VERSION ""

NS_ :

BS_:

BU_: ACM APIM APIM_CDC APIM_CIM APIM_CISM ARM DSP ESPM FCIMB GENERIC GWM HUD_ADV IPC MRCMB_RDAPM_HS3 RACM_RCIM TRM_ITRM TSTR WCM WCMB WCMC

BO_ 531 DesiredTorqBrk_HS3: 8 GWM
 SG_ PrplWhlTot_Tq_RqMx : 7|16@0+ (4,-131072) [-131072|131068] "Nm"  GENERIC
 SG_ LscmbBrkPrchg_B_Actl : 16|1@0+ (1,0) [0|1] "SED"  GENERIC
 SG_ LscmbbMntr_B_Err : 17|1@0+ (1,0) [0|1] "SED"  APIM,APIM_CDC,APIM_CIM,APIM_CISM,IPC
 SG_ LscmbbDeny_B_ActlBrk : 18|1@0+ (1,0) [0|1] "SED"  GENERIC
 SG_ LscmbbBrkDis_B_Actl : 19|1@0+ (1,0) [0|1] "SED"  GENERIC
 SG_ LscmbbBrkDecel_B_Actl : 20|1@0+ (1,0) [0|1] "SED"  GENERIC
 SG_ LscmbbBaSensInc_B_Actl : 21|1@0+ (1,0) [0|1] "SED"  GENERIC
 SG_ AccStopActv_B_ActlBrk : 22|1@0+ (1,0) [0|1] "SED"  GENERIC
 SG_ StabCtlBrkActv_B_Actl : 23|1@0+ (1,0) [0|1] "SED"  APIM,APIM_CDC,APIM_CIM,APIM_CISM
 SG_ PrkBrkStatus : 26|3@0+ (1,0) [0|7] "SED"  APIM,APIM_CDC,APIM_CIM,APIM_CISM,IPC
 SG_ VehStop_D_Stat : 28|2@0+ (1,0) [0|3] "SED"  GENERIC
 SG_ PrkBrkRedLamp_D_Rq : 30|2@0+ (1,0) [0|3] "SED"  APIM_CDC,APIM_CIM,APIM_CISM,IPC
 SG_ TracCtlPtActv_B_Actl : 31|1@0+ (1,0) [0|1] "SED"  GENERIC
 SG_ AccDis_B_ActlEpb : 32|1@0+ (1,0) [0|1] "SED"  GENERIC
 SG_ PrkBrkMsgTxt_D_Rq : 36|4@0+ (1,0) [0|15] "SED"  APIM,APIM_CDC,APIM_CIM,APIM_CISM,IPC
 SG_ PrkBrkYwLamp_D_Rq : 38|2@0+ (1,0) [0|3] "SED"  APIM_CDC,APIM_CIM,APIM_CISM,IPC
 SG_ VehicleStationary : 39|1@0+ (1,0) [0|1] "SED"  GENERIC
 SG_ VehLongOvrGnd_A_Est : 41|10@0+ (0.035,-17.9) [-17.9|17.905] "m/s^2"  TRM_ITRM
 SG_ AccBrkDeny_B_Actl : 42|1@0+ (1,0) [0|1] "SED"  GENERIC
 SG_ AccBrkActv_B_Actl : 43|1@0+ (1,0) [0|1] "SED"  GENERIC
 SG_ AccBrkDis_B_Actl : 44|1@0+ (1,0) [0|1] "SED"  GENERIC
 SG_ AbsActv_B_Actl : 45|1@0+ (1,0) [0|1] "SED"  APIM,APIM_CDC,APIM_CIM,APIM_CISM,TRM_ITRM
 SG_ PrplDrgCtlActv_B_Actl : 46|1@0+ (1,0) [0|1] "SED"  GENERIC
 SG_ CcDis_B_Cmd : 47|1@0+ (1,0) [0|1] "SED"  GENERIC
 SG_ CmbbBrkDis_B_Actl : 56|1@0+ (1,0) [0|1] "SED"  GENERIC
 SG_ CmbbBaSensInc_B_Actl : 57|1@0+ (1,0) [0|1] "SED"  GENERIC
 SG_ CmbbBrkDecel_B_Actl : 58|1@0+ (1,0) [0|1] "SED"  TRM_ITRM
 SG_ CmbbBrkPrchg_B_Actl : 59|1@0+ (1,0) [0|1] "SED"  TRM_ITRM
 SG_ CmbbDeny_B_ActlBrk : 60|1@0+ (1,0) [0|1] "SED"  GENERIC
 SG_ AccBrkPrchgActv_B_Actl : 61|1@0+ (1,0) [0|1] "SED"  GENERIC
 SG_ AccBrkTotTqMn_B_Actl : 62|1@0+ (1,0) [0|1] "SED"  TRM_ITRM
 SG_ AccBrkWarm_B_Actl : 63|1@0+ (1,0) [0|1] "SED"  GENERIC

BO_ 533 APIM_Send_Signals_2: 8 APIM_CDC
 SG_ TCU_Init_Actvtn_St : 1|2@0+ (1,0) [0|3] "SED"  GWM
 SG_ TCU_Final_Actvtn_St : 3|2@0+ (1,0) [0|3] "SED"  GWM
 SG_ TrlrAidMde_D_Rq : 5|2@0+ (1,0) [0|3] "SED"  GWM
 SG_ PaakMyKey_D_Rq : 7|2@0+ (1,0) [0|3] "SED"  GWM
 SG_ DcacMdeButtn_B_Stat : 8|1@0+ (1,0) [0|1] "SED"  GWM
 SG_ DcacGfciTestBttn_B_Stat : 9|1@0+ (1,0) [0|1] "SED"  GWM
 SG_ DcacPwButtn_B_Stat : 10|1@0+ (1,0) [0|1] "SED"  GWM
 SG_ DcacPwResetButtn_B_Stat : 11|1@0+ (1,0) [0|1] "SED"  GWM
 SG_ DcacPwOffButtn_B_Stat : 12|1@0+ (1,0) [0|1] "SED"  GWM
 SG_ DcacPwLoButtn_B_Stat : 13|1@0+ (1,0) [0|1] "SED"  GWM
 SG_ DcacPwHiButtn_B_Stat : 14|1@0+ (1,0) [0|1] "SED"  GWM
 SG_ DcacPwButtn_B_Falt : 15|1@0+ (1,0) [0|1] "SED"  GWM
 SG_ OnbChrgGoTUpdate_B_Rq : 16|1@0+ (1,0) [0|1] "SED"  GWM
 SG_ OnbChrgGoTDelete_B_Rq : 17|1@0+ (1,0) [0|1] "SED"  GWM
 SG_ OnbChrgClearAll_B_Rq : 18|1@0+ (1,0) [0|1] "SED"  GWM
 SG_ AutoEpbButtn_B_Stat : 19|1@0+ (1,0) [0|1] "SED"  GWM
 SG_ TrlrHitch_D_RqMnu : 23|4@0+ (1,0) [0|15] "SED"  GWM
 SG_ OnbChrgGoTOn_D_Rq : 25|2@0+ (1,0) [0|3] "SED"  GWM
 SG_ OnbChrgGoTExtHtr_D_Rq : 27|2@0+ (1,0) [0|3] "SED"  GWM
 SG_ OnbChrgGoTElement_D_Rq : 31|4@0+ (1,0) [0|15] "unitless"  GWM
 SG_ AutoEpbZoomView_B_Stat : 32|1@0+ (1,0) [0|1] "SED"  GWM
 SG_ OnbChrgGoTPrcond_D_Rq : 34|2@0+ (1,0) [0|3] "SED"  GWM
 SG_ OnbChrgGoTHr_T_Rq : 39|5@0+ (1,0) [0|31] "hour"  GWM
 SG_ OtaTrg_D_Stat : 41|2@0+ (1,0) [0|3] "SED"  GWM
 SG_ OnbChrgGoTTouch_D_Rq : 43|2@0+ (1,0) [0|3] "SED"  GWM
 SG_ OnbChrgGoTMnte_D_Rq : 47|4@0+ (1,0) [0|15] "minute"  GWM
 SG_ LghtAmbDrvMde_D_Rq : 49|2@0+ (1,0) [0|3] "SED"  GWM
 SG_ TrlrAlarmButtn_B_Stat : 50|1@0+ (1,0) [0|1] "SED"  GWM,TRM_ITRM
 SG_ TrlrBrkGain_No_Rq : 55|5@0+ (0.5,0) [0|15.5] "unitless"  GWM,TRM_ITRM
 SG_ TjaLcEnbl_D_RqMnu : 57|2@0+ (1,0) [0|3] "SED"  GWM
 SG_ ExtLghtRvrseOn_B_Rq : 58|1@0+ (1,0) [0|1] "SED"  GWM
 SG_ ClrExitAsstEnbl_D_RqMnu : 60|2@0+ (1,0) [0|3] "SED"  GWM
 SG_ DcacPw_D_Rq : 62|2@0+ (1,0) [0|3] "SED"  GWM
 SG_ DcacPwReset_B_Rq : 63|1@0+ (1,0) [0|1] "SED"  GWM

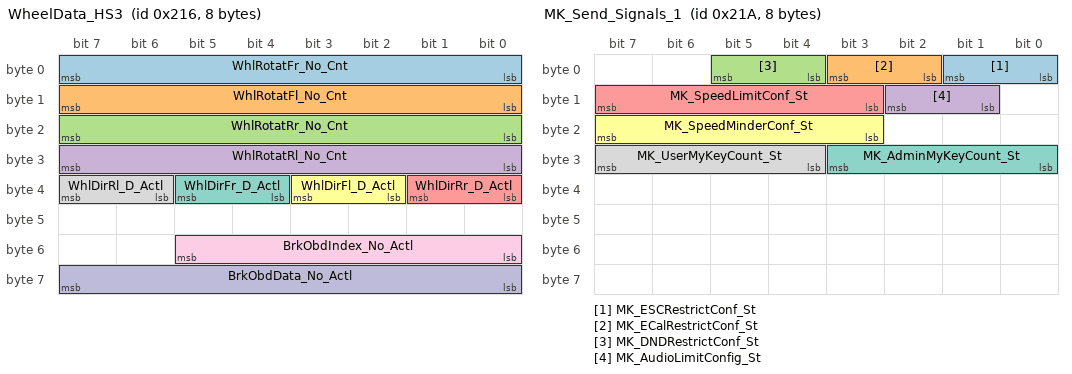
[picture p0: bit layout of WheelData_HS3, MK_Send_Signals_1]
BO_ 534 WheelData_HS3: 8 GWM
 SG_ WhlRotatFr_No_Cnt : 7|8@0+ (1,0) [0|255] "unitless"  APIM,APIM_CDC,APIM_CIM,APIM_CISM
 SG_ WhlRotatFl_No_Cnt : 15|8@0+ (1,0) [0|255] "unitless"  APIM,APIM_CDC,APIM_CIM,APIM_CISM
 SG_ WhlRotatRr_No_Cnt : 23|8@0+ (1,0) [0|255] "unitless"  APIM,APIM_CDC,APIM_CIM,APIM_CISM
 SG_ WhlRotatRl_No_Cnt : 31|8@0+ (1,0) [0|255] "unitless"  APIM,APIM_CDC,APIM_CIM,APIM_CISM
 SG_ WhlDirRr_D_Actl : 33|2@0+ (1,0) [0|3] "SED"  APIM,APIM_CDC,APIM_CIM,APIM_CISM
 SG_ WhlDirFl_D_Actl : 35|2@0+ (1,0) [0|3] "SED"  APIM,APIM_CDC,APIM_CIM,APIM_CISM
 SG_ WhlDirFr_D_Actl : 37|2@0+ (1,0) [0|3] "SED"  APIM,APIM_CDC,APIM_CIM,APIM_CISM
 SG_ WhlDirRl_D_Actl : 39|2@0+ (1,0) [0|3] "SED"  APIM,APIM_CDC,APIM_CIM,APIM_CISM
 SG_ BrkObdIndex_No_Actl : 53|6@0+ (1,0) [0|63] "unitless"  GENERIC
 SG_ BrkObdData_No_Actl : 63|8@0+ (1,0) [0|255] "unitless"  GENERIC

BO_ 535 WheelSpeed_HS3: 8 GWM
 SG_ WhlFl_W_Meas : 6|15@0+ (0.01,0) [0|327.67] "rad/s"  ARM
 SG_ WhlFr_W_Meas : 22|15@0+ (0.01,0) [0|327.67] "rad/s"  ARM
 SG_ WhlRl_W_Meas : 38|15@0+ (0.01,0) [0|327.67] "rad/s"  ARM
 SG_ WhlRr_W_Meas : 54|15@0+ (0.01,0) [0|327.67] "rad/s"  ARM

BO_ 538 MK_Send_Signals_1: 8 IPC
 SG_ MK_ESCRestrictConf_St : 1|2@0+ (1,0) [0|3] "SED"  APIM,APIM_CISM,GWM
 SG_ MK_ECalRestrictConf_St : 3|2@0+ (1,0) [0|3] "SED"  APIM,APIM_CISM,GWM
 SG_ MK_DNDRestrictConf_St : 5|2@0+ (1,0) [0|3] "SED"  APIM,APIM_CISM,GWM
 SG_ MK_AudioLimitConfig_St : 10|2@0+ (1,0) [0|3] "SED"  APIM,APIM_CISM,GWM
 SG_ MK_SpeedLimitConf_St : 15|5@0+ (1,0) [0|31] "SED"  APIM,APIM_CISM,GWM
 SG_ MK_SpeedMinderConf_St : 23|5@0+ (1,0) [0|31] "SED"  APIM,APIM_CISM,GWM
 SG_ MK_AdminMyKeyCount_St : 27|4@0+ (1,0) [0|13] "SED"  APIM,APIM_CISM,GWM
 SG_ MK_UserMyKeyCount_St : 31|4@0+ (1,0) [0|13] "SED"  APIM,APIM_CISM,GWM

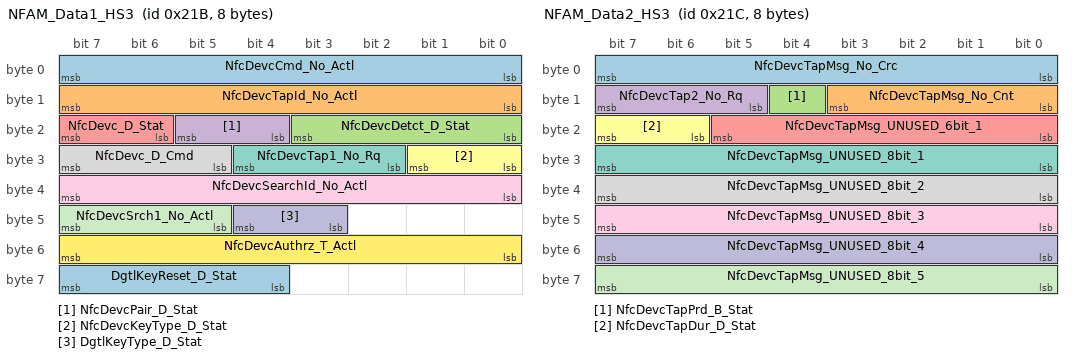
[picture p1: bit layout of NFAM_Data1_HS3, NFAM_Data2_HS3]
BO_ 539 NFAM_Data1_HS3: 8 GWM
 SG_ NfcDevcCmd_No_Actl : 7|8@0+ (1,0) [0|255] "unitless" Vector__XXX
 SG_ NfcDevcTapId_No_Actl : 15|8@0+ (1,0) [0|255] "unitless"  APIM,APIM_CDC,APIM_CIM,IPC
 SG_ NfcDevcDetct_D_Stat : 19|4@0+ (1,0) [0|15] "SED"  APIM,APIM_CDC,APIM_CIM,IPC
 SG_ NfcDevcPair_D_Stat : 21|2@0+ (1,0) [0|3] "SED" Vector__XXX
 SG_ NfcDevc_D_Stat : 23|2@0+ (1,0) [0|3] "SED" Vector__XXX
 SG_ NfcDevcKeyType_D_Stat : 25|2@0+ (1,0) [0|3] "SED" Vector__XXX
 SG_ NfcDevcTap1_No_Rq : 28|3@0+ (1,0) [0|7] "unitless"  APIM,APIM_CDC,APIM_CIM,IPC
 SG_ NfcDevc_D_Cmd : 31|3@0+ (1,0) [0|7] "SED" Vector__XXX
 SG_ NfcDevcSearchId_No_Actl : 39|8@0+ (1,0) [0|255] "unitless" Vector__XXX
 SG_ DgtlKeyType_D_Stat : 44|2@0+ (1,0) [0|3] "SED" Vector__XXX
 SG_ NfcDevcSrch1_No_Actl : 47|3@0+ (1,0) [0|7] "unitless" Vector__XXX
 SG_ NfcDevcAuthrz_T_Actl : 55|8@0+ (1,0) [0|255] "second" Vector__XXX
 SG_ DgtlKeyReset_D_Stat : 63|4@0+ (1,0) [0|15] "SED" Vector__XXX

BO_ 540 NFAM_Data2_HS3: 8 GWM
 SG_ NfcDevcTapMsg_No_Crc : 7|8@0+ (1,0) [0|255] "unitless"  APIM,APIM_CDC,APIM_CIM,IPC
 SG_ NfcDevcTapMsg_No_Cnt : 11|4@0+ (1,0) [0|15] "unitless"  APIM,APIM_CDC,APIM_CIM,IPC
 SG_ NfcDevcTapPrd_B_Stat : 12|1@0+ (1,0) [0|1] "SED"  APIM,APIM_CDC,APIM_CIM,IPC
 SG_ NfcDevcTap2_No_Rq : 15|3@0+ (1,0) [0|7] "unitless"  APIM,APIM_CDC,APIM_CIM,IPC
 SG_ NfcDevcTapMsg_UNUSED_6bit_1 : 21|6@0+ (1,0) [63|63] "Unitless"  APIM_CDC,APIM_CIM
 SG_ NfcDevcTapDur_D_Stat : 23|2@0+ (1,0) [0|3] "SED"  APIM,APIM_CDC,APIM_CIM,IPC
 SG_ NfcDevcTapMsg_UNUSED_8bit_1 : 31|8@0+ (1,0) [255|255] "Unitless"  APIM_CDC,APIM_CIM
 SG_ NfcDevcTapMsg_UNUSED_8bit_2 : 39|8@0+ (1,0) [255|255] "Unitless"  APIM_CDC,APIM_CIM
 SG_ NfcDevcTapMsg_UNUSED_8bit_3 : 47|8@0+ (1,0) [255|255] "Unitless"  APIM_CDC,APIM_CIM
 SG_ NfcDevcTapMsg_UNUSED_8bit_4 : 55|8@0+ (1,0) [255|255] "Unitless"  APIM_CDC,APIM_CIM
 SG_ NfcDevcTapMsg_UNUSED_8bit_5 : 63|8@0+ (1,0) [255|255] "Unitless"  APIM_CDC,APIM_CIM

BO_ 542 LocationServices_3_HS3: 8 GWM
 SG_ LocationServices_3 : 7|64@0+ (1,0) [0|1.84467440737096E+019] "unitless"  ACM,APIM,APIM_CDC,APIM_CIM,APIM_CISM,IPC

BO_ 543 TelTaleData: 8 APIM_CDC
 SG_ TeltalWarnData_No_Actl : 7|64@0+ (1,0) [0|1.84467440737096E+019] "unitless"  APIM,APIM_CISM,GWM

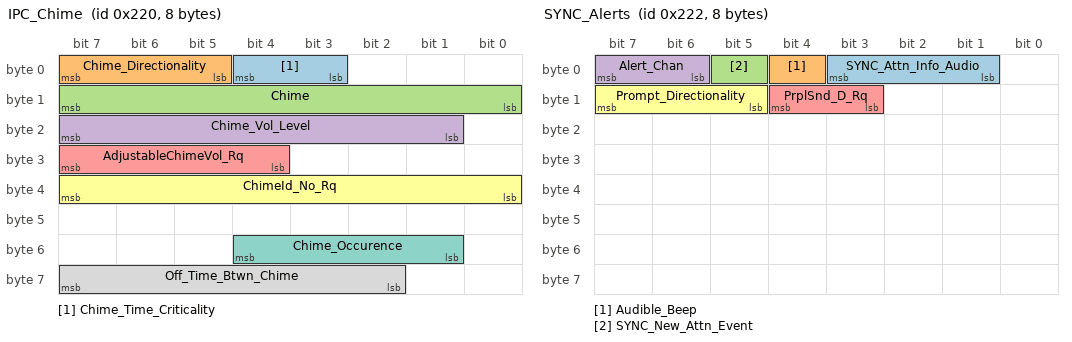
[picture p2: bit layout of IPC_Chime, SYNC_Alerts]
BO_ 544 IPC_Chime: 8 APIM_CDC
 SG_ Chime_Time_Criticality : 4|2@0+ (1,0) [0|3] "SED"  ACM,APIM_CISM,DSP,GWM
 SG_ Chime_Directionality : 7|3@0+ (1,0) [0|7] "SED"  ACM,APIM_CISM,DSP,GWM
 SG_ Chime : 15|8@0+ (1,0) [0|255] "unitless"  ACM,APIM_CISM,DSP,GWM
 SG_ Chime_Vol_Level : 23|7@0+ (1,0) [0|127] "unitless"  ACM,APIM_CISM,DSP,GWM
 SG_ AdjustableChimeVol_Rq : 31|4@0+ (1,0) [0|15] "SED"  ACM,APIM_CISM,DSP,GWM
 SG_ ChimeId_No_Rq : 39|8@0+ (1,0) [0|255] "SED"  ACM,APIM_CISM,GWM
 SG_ Chime_Occurence : 52|4@0+ (1,0) [0|15] "SED"  ACM,APIM_CISM,DSP,GWM
 SG_ Off_Time_Btwn_Chime : 63|6@0+ (1,0) [0|52] "unitless"  ACM,APIM_CISM,DSP,GWM

BO_ 545 DSPAMP_Send_Signals_1: 8 DSP
 SG_ DSP_MyKeyVolLim_St : 2|2@0+ (1,0) [0|3] "SED"  APIM,APIM_CDC,APIM_CIM,APIM_CISM
 SG_ DSP_BeltminderAudio_St : 4|2@0+ (1,0) [0|3] "SED"  APIM,APIM_CDC,APIM_CIM,APIM_CISM
 SG_ DSP_Sur_Sound_st : 7|2@0+ (1,0) [0|3] "SED"  APIM,APIM_CDC,APIM_CIM,APIM_CISM
 SG_ DSP_Audio_Volume_Up_St : 9|1@0+ (1,0) [0|1] "SED"  ACM,APIM,APIM_CDC,APIM_CIM,APIM_CISM,GWM,HUD_ADV,IPC,RACM_RCIM
 SG_ DSP_Audio_Vol_Level_St : 15|5@0+ (1,0) [0|30] "unitless"  ACM,APIM,APIM_CDC,APIM_CIM,APIM_CISM,HUD_ADV,IPC,RACM_RCIM,WCM
 SG_ DSP_MyKeyVolLimitUp_St : 19|2@0+ (1,0) [0|3] "SED"  APIM,APIM_CDC,APIM_CIM,APIM_CISM
 SG_ DSP_Bezel_Diag_St : 23|4@0+ (1,0) [0|15] "SED"  APIM,APIM_CDC,APIM_CIM,APIM_CISM
 SG_ AutoConfigOcc_Rear : 28|1@0+ (1,0) [0|1] "SED"  APIM,APIM_CDC,APIM_CIM,APIM_CISM
 SG_ AutoConfigOcc_AllSeats : 29|1@0+ (1,0) [0|1] "SED"  APIM,APIM_CDC,APIM_CIM,APIM_CISM
 SG_ AutoConfigOcc_Front : 30|1@0+ (1,0) [0|1] "SED"  APIM,APIM_CDC,APIM_CIM,APIM_CISM
 SG_ AutoConfigOcc_Driver : 31|1@0+ (1,0) [0|1] "SED"  APIM,APIM_CDC,APIM_CIM,APIM_CISM
 SG_ SurndSndUpmix2_D_Stat : 34|3@0+ (1,0) [0|7] "SED"  APIM,APIM_CDC,APIM_CIM,APIM_CISM
 SG_ AudioOccMde_D_Stat : 39|5@0+ (1,0) [0|31] "SED"  APIM,APIM_CDC,APIM_CIM,APIM_CISM
 SG_ SpkrDgtlCntr_D_Stat : 43|2@0+ (1,0) [0|3] "SED"  ACM,APIM_CDC,APIM_CIM,APIM_CISM
 SG_ SpkrDgtlLeft_D_Stat : 45|2@0+ (1,0) [0|3] "SED"  GENERIC
 SG_ SpkrDgtlRight_D_Stat : 47|2@0+ (1,0) [0|3] "SED"  GENERIC
 SG_ SndImmrsnLvl_D_Stat : 55|8@0+ (1,0) [0|255] "SED"  APIM,APIM_CDC,APIM_CIM,APIM_CISM

BO_ 546 SYNC_Alerts: 8 APIM_CDC
 SG_ SYNC_Attn_Info_Audio : 3|3@0+ (1,0) [0|7] "SED"  ACM,DSP
 SG_ Audible_Beep : 4|1@0+ (1,0) [0|1] "SED"  ACM,DSP
 SG_ SYNC_New_Attn_Event : 5|1@0+ (1,0) [0|1] "SED"  ACM,DSP
 SG_ Alert_Chan : 7|2@0+ (1,0) [0|3] "SED"  ACM,DSP,RACM_RCIM,WCM
 SG_ PrplSnd_D_Rq : 12|2@0+ (1,0) [0|3] "SED"  ACM
 SG_ Prompt_Directionality : 15|3@0+ (1,0) [0|7] "SED"  ACM,DSP

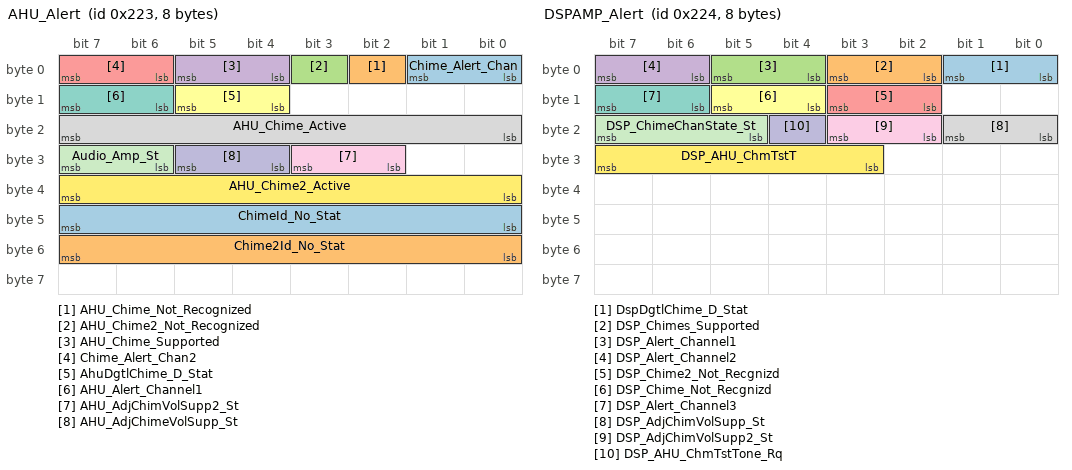
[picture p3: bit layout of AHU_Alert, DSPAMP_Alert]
BO_ 547 AHU_Alert: 8 APIM_CIM
 SG_ Chime_Alert_Chan : 1|2@0+ (1,0) [0|3] "SED"  DSP,GWM,IPC
 SG_ AHU_Chime_Not_Recognized : 2|1@0+ (1,0) [0|1] "SED"  APIM_CDC,GWM,IPC
 SG_ AHU_Chime2_Not_Recognized : 3|1@0+ (1,0) [0|1] "SED"  APIM_CDC,GWM,IPC
 SG_ AHU_Chime_Supported : 5|2@0+ (1,0) [0|3] "SED"  APIM,APIM_CDC,GWM,IPC
 SG_ Chime_Alert_Chan2 : 7|2@0+ (1,0) [0|3] "SED"  DSP,GWM,IPC
 SG_ AhuDgtlChime_D_Stat : 13|2@0+ (1,0) [0|3] "SED"  DSP
 SG_ AHU_Alert_Channel1 : 15|2@0+ (1,0) [0|3] "SED"  APIM,APIM_CDC,GWM,IPC,RACM_RCIM,WCM
 SG_ AHU_Chime_Active : 23|8@0+ (1,0) [0|255] "SED"  APIM_CDC,DSP,GWM,IPC
 SG_ AHU_AdjChimVolSupp2_St : 27|2@0+ (1,0) [0|3] "SED"  APIM_CDC,IPC
 SG_ AHU_AdjChimeVolSupp_St : 29|2@0+ (1,0) [0|3] "SED"  APIM_CDC,IPC
 SG_ Audio_Amp_St : 31|2@0+ (1,0) [0|3] "SED"  GWM
 SG_ AHU_Chime2_Active : 39|8@0+ (1,0) [0|255] "SED"  APIM_CDC,DSP,GWM,IPC
 SG_ ChimeId_No_Stat : 47|8@0+ (1,0) [0|255] "SED"  APIM_CDC,IPC
 SG_ Chime2Id_No_Stat : 55|8@0+ (1,0) [0|255] "SED"  APIM_CDC,IPC

BO_ 548 DSPAMP_Alert: 8 DSP
 SG_ DspDgtlChime_D_Stat : 1|2@0+ (1,0) [0|3] "SED"  ACM,APIM_CIM,APIM_CISM
 SG_ DSP_Chimes_Supported : 3|2@0+ (1,0) [0|3] "SED"  ACM,APIM,APIM_CDC,APIM_CIM,APIM_CISM,IPC
 SG_ DSP_Alert_Channel1 : 5|2@0+ (1,0) [0|3] "SED"  ACM,APIM_CDC,APIM_CIM,APIM_CISM,IPC
 SG_ DSP_Alert_Channel2 : 7|2@0+ (1,0) [0|3] "SED"  ACM,APIM_CDC,APIM_CIM,APIM_CISM,IPC
 SG_ DSP_Chime2_Not_Recgnizd : 11|2@0+ (1,0) [0|3] "SED"  APIM_CDC,APIM_CIM,APIM_CISM,IPC
 SG_ DSP_Chime_Not_Recgnizd : 13|2@0+ (1,0) [0|3] "SED"  APIM_CDC,APIM_CIM,APIM_CISM,IPC
 SG_ DSP_Alert_Channel3 : 15|2@0+ (1,0) [0|3] "SED"  APIM,APIM_CDC,APIM_CIM,APIM_CISM,IPC,RACM_RCIM,WCM
 SG_ DSP_AdjChimVolSupp_St : 17|2@0+ (1,0) [0|3] "SED"  ACM,APIM_CDC,APIM_CIM,APIM_CISM,IPC
 SG_ DSP_AdjChimVolSupp2_St : 19|2@0+ (1,0) [0|3] "SED"  ACM,APIM_CDC,APIM_CIM,APIM_CISM,IPC
 SG_ DSP_AHU_ChmTstTone_Rq : 20|1@0+ (1,0) [0|1] "SED"  ACM,APIM_CIM,APIM_CISM
 SG_ DSP_ChimeChanState_St : 23|3@0+ (1,0) [0|7] "SED"  ACM,APIM_CIM,APIM_CISM
 SG_ DSP_AHU_ChmTstT : 31|5@0+ (1,0) [0|31] "SED"  ACM,APIM_CIM,APIM_CISM

BO_ 549 IPC_Infotainment: 8 APIM_CDC
 SG_ IPC_New_Attn_Event : 0|1@0+ (1,0) [0|1] "SED"  ACM,APIM,APIM_CISM,DSP,GWM
 SG_ HudBrightMnuOn_B_Rq : 1|1@0+ (1,0) [0|1] "SED"  GWM,HUD_ADV
 SG_ IPC_Attn_Info_Audio : 4|3@0+ (1,0) [0|7] "SED"  ACM,APIM,APIM_CISM,DSP,GWM
 SG_ BeltminderAudioMute : 6|2@0+ (1,0) [0|3] "SED"  ACM,APIM,APIM_CISM,DSP,GWM
 SG_ MetricActv_B_Dsply : 7|1@0+ (1,0) [0|1] "SED"  ARM,GWM,HUD_ADV
 SG_ IPC_MyKeyVolLimit_St : 9|2@0+ (1,0) [0|3] "SED"  ACM,APIM,APIM_CISM,DSP,GWM
 SG_ HudVertMnuOn_B_Rq : 11|1@0+ (1,0) [0|1] "SED"  GWM,HUD_ADV
 SG_ SpeedChngChime_D_Rq2 : 13|2@0+ (1,0) [0|3] "SED"  GWM
 SG_ Chime_Source : 15|2@0+ (1,0) [0|3] "SED"  ACM,APIM_CISM,DSP,GWM
 SG_ StrtInGearOk_D_Stat : 17|2@0+ (1,0) [0|3] "SED"  GWM
 SG_ FactoryReset_Rq2 : 18|1@0+ (1,0) [0|1] "SED"  GWM
 SG_ HdcOn_B_Rq : 19|1@0+ (1,0) [0|1] "SED"  GWM
 SG_ HudCntntMnuOn_B_Rq : 20|1@0+ (1,0) [0|1] "SED"  GWM,HUD_ADV
 SG_ HudVertSzMnuOn_B_Rq : 21|1@0+ (1,0) [0|1] "SED"  GWM,HUD_ADV
 SG_ HudRotatMnuOn_B_Rq : 22|1@0+ (1,0) [0|1] "SED"  GWM,HUD_ADV
 SG_ Power_Up_Chime_Modules : 23|1@0+ (1,0) [0|1] "SED"  ACM,APIM_CISM,DSP,GWM
 SG_ WndwCabnMde_D_Rq2 : 25|2@0+ (1,0) [0|3] "SED"  GWM
 SG_ HazrdLghtMde_D_Rq2 : 27|2@0+ (1,0) [0|3] "SED"  GWM
 SG_ DelvrAsstLckMde_D_Rq2 : 29|2@0+ (1,0) [0|3] "SED"  GWM
 SG_ DelvrAsstButtn_D_Rq2 : 31|2@0+ (1,0) [0|3] "SED"  GWM
 SG_ Veh_V2_Dsply : 39|9@0+ (1,0) [0|511] "unitless"  APIM,APIM_CISM,ARM,GWM,HUD_ADV
 SG_ TjaLcEnbl_D_DrvRq : 41|2@0+ (1,0) [0|3] "SED"  GWM
 SG_ CCOI_PolicyClient_St2 : 45|4@0+ (1,0) [0|15] "SED"  GWM
 SG_ WwaActv_B_Stat : 46|1@0+ (1,0) [0|1] "SED"  ACM,APIM,APIM_CISM,GWM
 SG_ BattTracLoThres_D_Rq2 : 52|3@0+ (1,0) [0|7] "SED"  GWM
 SG_ NavIod_D_Rq : 55|3@0+ (1,0) [0|7] "SED"  APIM_CISM,GWM

BO_ 551 APIM_Request_Signals_1: 8 APIM_CDC
 SG_ PrkBrkPerfMnuOn_D_Stat : 1|2@0+ (1,0) [0|3] "SED"  GWM
 SG_ PrkBrkPerfButtn_D_Stat : 3|2@0+ (1,0) [0|3] "SED"  GWM
 SG_ TjaLaneBiasEnbl_D_RqMnu : 5|2@0+ (1,0) [0|3] "SED"  GWM
 SG_ EcoIdl_D_Rq : 7|2@0+ (1,0) [0|3] "SED"  GWM
 SG_ VehPerfDemo_B_RqDrv : 8|1@0+ (1,0) [0|1] "SED"  GWM
 SG_ GoTElementEdit_No_RqMnu : 12|4@0+ (1,0) [0|15] "unitless"  GWM
 SG_ PrcondEdit_D_RqMnu : 15|3@0+ (1,0) [0|7] "SED"  GWM
 SG_ SelDrvMdeDsply_B_Avai2 : 16|1@0+ (1,0) [0|1] "SED"  GWM
 SG_ ChrgToPcEdit_Pc_RqMnu : 23|7@0+ (1,0) [0|127] "percent"  GWM
 SG_ PwRnngBoardT_D_Rq : 25|2@0+ (1,0) [0|3] "SED"  GWM
 SG_ PwRnngBoardSwtch_D_Rq : 27|2@0+ (1,0) [0|3] "SED"  GWM
 SG_ PwRnngBoardMde_D_Rq : 29|2@0+ (1,0) [0|3] "SED"  GWM
 SG_ Rba_D_Rq : 31|2@0+ (1,0) [0|3] "SED"  GWM
 SG_ EmPrflButtnAssoc_D_Rq : 33|2@0+ (1,0) [0|3] "SED"  GWM
 SG_ PmCabnLvl_D_Stat : 36|3@0+ (1,0) [0|7] "SED"  GWM,RACM_RCIM
 SG_ PmCabn_D_Stat : 38|2@0+ (1,0) [0|3] "SED"  GWM,RACM_RCIM
 SG_ Cntr_Plg_Mode_Cmd : 39|1@0+ (1,0) [0|1] "SED"  GWM
 SG_ OneTEditActv_B_RqMnu : 40|1@0+ (1,0) [0|1] "SED"  GWM
 SG_ BattTracLoThres_D_Rq : 43|3@0+ (1,0) [0|7] "SED"  GWM
 SG_ EmPrflKeyAssoc_D_Rq : 46|3@0+ (1,0) [0|7] "SED"  GWM
 SG_ ChrgCrdLckEnbl_B_Stat : 47|1@0+ (1,0) [0|1] "SED"  GWM
 SG_ WndwChildLckPw_B_RqMnu : 48|1@0+ (1,0) [0|1] "SED"  GWM
 SG_ Btt_L_Actl2 : 55|7@0+ (0.1,0) [0|12.7] "meter"  GWM
 SG_ BecConfg_B_RqMnu : 56|1@0+ (1,0) [0|1] "SED"  GWM
 SG_ ChrgOvrdExitScrn_D_Rq : 58|2@0+ (1,0) [0|3] "SED"  GWM
 SG_ EmPrflNo_D_Rq : 61|3@0+ (1,0) [0|7] "SED"  GWM
 SG_ Em_D_Stat : 63|2@0+ (1,0) [0|3] "SED"  GWM

BO_ 552 DSPAMP_Send_Signals: 8 DSP
 SG_ Audio_Demo_Status : 0|1@0+ (1,0) [0|1] "SED"  APIM,APIM_CDC,APIM_CIM,APIM_CISM
 SG_ DSP_Shaker_St : 1|1@0+ (1,0) [0|1] "SED"  APIM,APIM_CDC,APIM_CIM,APIM_CISM
 SG_ DSP_AVC_St : 6|3@0+ (1,0) [0|7] "SED"  APIM,APIM_CDC,APIM_CIM,APIM_CISM
 SG_ DSP_NavCmdVolume_Up : 7|1@0+ (1,0) [0|1] "SED"  APIM,APIM_CDC,APIM_CIM,APIM_CISM,HUD_ADV,IPC
 SG_ DSP_Balance_St : 8|4@0+ (1,-7) [-7|8] "unitless"  APIM,APIM_CDC,APIM_CIM,APIM_CISM
 SG_ DSP_Bass_St : 12|4@0+ (1,-7) [-7|8] "unitless"  APIM,APIM_CDC,APIM_CIM,APIM_CISM
 SG_ DSP_DSPProgram_St : 15|3@0+ (1,0) [0|7] "SED"  APIM,APIM_CDC,APIM_CIM,APIM_CISM
 SG_ DSP_DSP_St : 16|5@0+ (1,0) [0|31] "SED"  APIM,APIM_CDC,APIM_CIM,APIM_CISM
 SG_ DSP_Fader_St : 20|4@0+ (1,-7) [-7|8] "unitless"  APIM,APIM_CDC,APIM_CIM,APIM_CISM
 SG_ DSP_NavCmdVolume_St : 24|5@0+ (1,0) [0|30] "SED"  APIM,APIM_CDC,APIM_CIM,APIM_CISM,HUD_ADV,IPC,WCM
 SG_ DSP_PhoneVolume_Up : 25|1@0+ (1,0) [0|1] "SED"  APIM,APIM_CDC,APIM_CIM,APIM_CISM,HUD_ADV,IPC
 SG_ DSP_Reg_St : 27|2@0+ (1,0) [0|3] "SED"  APIM,APIM_CDC,APIM_CIM,APIM_CISM
 SG_ DSP_PhoneVolume_St : 33|5@0+ (1,0) [0|30] "unitless"  APIM,APIM_CDC,APIM_CIM,APIM_CISM,HUD_ADV,IPC,WCM
 SG_ DSP_TAVolume_Up : 34|1@0+ (1,0) [0|1] "SED"  APIM,APIM_CDC,APIM_CIM,APIM_CISM,HUD_ADV,IPC
 SG_ DSP_VoiceFBVolume_Up : 35|1@0+ (1,0) [0|1] "SED"  APIM,APIM_CDC,APIM_CIM,APIM_CISM,HUD_ADV,IPC
 SG_ DSP_TAVolume_St : 44|5@0+ (1,0) [0|30] "unitless"  APIM,APIM_CDC,APIM_CIM,APIM_CISM,HUD_ADV,IPC,WCM
 SG_ DSP_Midrange_St : 51|4@0+ (1,-7) [-7|8] "unitless"  APIM,APIM_CDC,APIM_CIM,APIM_CISM
 SG_ DSP_Treble_St : 55|4@0+ (1,-7) [-7|8] "unitless"  APIM,APIM_CDC,APIM_CIM,APIM_CISM
 SG_ ActvNseMute_D_Stat : 58|2@0+ (1,0) [0|3] "SED"  APIM,APIM_CDC,APIM_CIM,APIM_CISM
 SG_ DSP_VoiceFBVolume_St : 63|5@0+ (1,0) [0|30] "unitless"  APIM,APIM_CDC,APIM_CIM,APIM_CISM,HUD_ADV,IPC,WCM

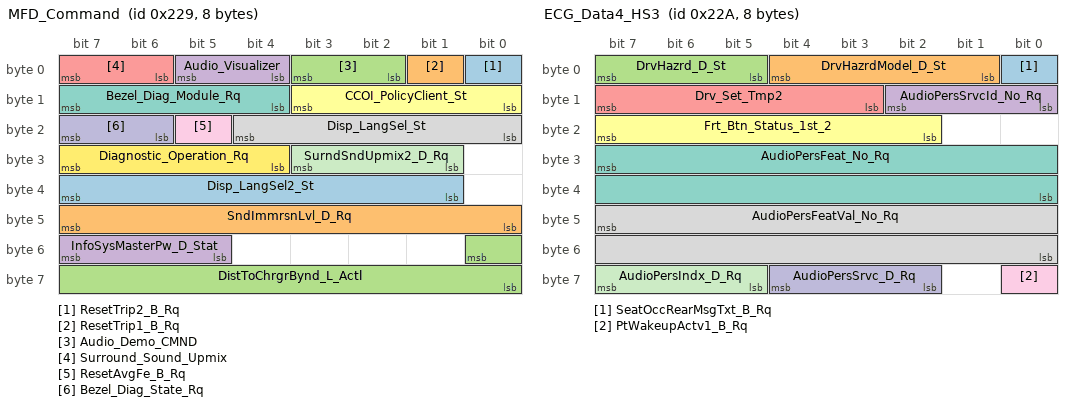
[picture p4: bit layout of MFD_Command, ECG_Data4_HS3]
BO_ 553 MFD_Command: 8 APIM_CDC
 SG_ ResetTrip2_B_Rq : 0|1@0+ (1,0) [0|1] "SED"  GWM,IPC
 SG_ ResetTrip1_B_Rq : 1|1@0+ (1,0) [0|1] "SED"  GWM,IPC
 SG_ Audio_Demo_CMND : 3|2@0+ (1,0) [0|3] "SED"  ACM,DSP,GWM
 SG_ Audio_Visualizer : 5|2@0+ (1,0) [0|3] "SED"  ACM,DSP,GWM
 SG_ Surround_Sound_Upmix : 7|2@0+ (1,0) [0|3] "SED"  DSP,GWM
 SG_ CCOI_PolicyClient_St : 11|4@0+ (1,0) [0|15] "SED"  GWM
 SG_ Bezel_Diag_Module_Rq : 15|4@0+ (1,0) [0|15] "SED"  ACM,DSP,GWM
 SG_ Disp_LangSel_St : 20|5@0+ (1,0) [0|31] "SED"  GWM,IPC,MRCMB_RDAPM_HS3,RACM_RCIM
 SG_ ResetAvgFe_B_Rq : 21|1@0+ (1,0) [0|1] "SED"  GWM,IPC
 SG_ Bezel_Diag_State_Rq : 23|2@0+ (1,0) [0|3] "SED"  ACM,DSP,GWM
 SG_ SurndSndUpmix2_D_Rq : 27|3@0+ (1,0) [0|7] "SED"  DSP,GWM
 SG_ Diagnostic_Operation_Rq : 31|4@0+ (1,0) [0|15] "SED"  ACM,DSP,GWM
 SG_ Disp_LangSel2_St : 39|7@0+ (1,0) [0|127] "SED"  GWM,IPC,MRCMB_RDAPM_HS3
 SG_ SndImmrsnLvl_D_Rq : 47|8@0+ (1,0) [0|255] "SED"  DSP,GWM
 SG_ DistToChrgrBynd_L_Actl : 48|9@0+ (1,0) [0|511] "kilometer"  GWM
 SG_ InfoSysMasterPw_D_Stat : 55|3@0+ (1,0) [0|7] "SED"  GWM

BO_ 554 ECG_Data4_HS3: 8 GWM
 SG_ SeatOccRearMsgTxt_B_Rq : 0|1@0+ (1,0) [0|1] "SED"  APIM,APIM_CDC,APIM_CIM,APIM_CISM
 SG_ DrvHazrdModel_D_St : 4|4@0+ (1,0) [0|15] "SED"  APIM,APIM_CDC,APIM_CIM,APIM_CISM,IPC
 SG_ DrvHazrd_D_St : 7|3@0+ (1,0) [0|7] "SED"  APIM,APIM_CDC,APIM_CIM,APIM_CISM,IPC
 SG_ AudioPersSrvcId_No_Rq : 10|3@0+ (1,0) [0|7] "unitless"  DSP
 SG_ Drv_Set_Tmp2 : 15|5@0+ (1,0) [0|31] "SED"  RACM_RCIM
 SG_ Frt_Btn_Status_1st_2 : 23|6@0+ (1,0) [0|63] "SED"  RACM_RCIM
 SG_ AudioPersFeat_No_Rq : 31|16@0+ (1,0) [0|65535] "unitless"  DSP
 SG_ AudioPersFeatVal_No_Rq : 47|16@0+ (1,0) [0|65535] "unitless"  DSP
 SG_ PtWakeupActv1_B_Rq : 56|1@0+ (1,0) [0|1] "SED"  APIM,APIM_CDC,APIM_CIM,APIM_CISM
 SG_ AudioPersSrvc_D_Rq : 60|3@0+ (1,0) [0|7] "SED"  DSP
 SG_ AudioPersIndx_D_Rq : 63|3@0+ (1,0) [0|7] "SED"  DSP

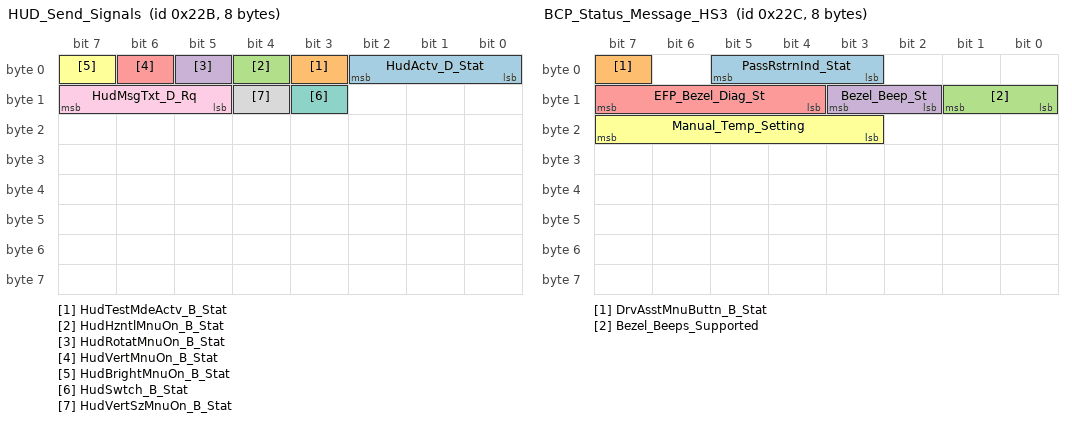
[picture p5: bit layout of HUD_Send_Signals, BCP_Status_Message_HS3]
BO_ 555 HUD_Send_Signals: 8 HUD_ADV
 SG_ HudActv_D_Stat : 2|3@0+ (1,0) [0|7] "SED"  APIM_CDC,APIM_CIM,APIM_CISM,IPC
 SG_ HudTestMdeActv_B_Stat : 3|1@0+ (1,0) [0|1] "SED"  APIM_CDC,APIM_CIM,APIM_CISM,IPC
 SG_ HudHzntlMnuOn_B_Stat : 4|1@0+ (1,0) [0|1] "SED"  APIM_CDC,APIM_CIM,APIM_CISM,IPC
 SG_ HudRotatMnuOn_B_Stat : 5|1@0+ (1,0) [0|1] "SED"  APIM_CDC,APIM_CIM,APIM_CISM,IPC
 SG_ HudVertMnuOn_B_Stat : 6|1@0+ (1,0) [0|1] "SED"  APIM_CDC,APIM_CIM,APIM_CISM,IPC
 SG_ HudBrightMnuOn_B_Stat : 7|1@0+ (1,0) [0|1] "SED"  APIM_CDC,APIM_CIM,APIM_CISM,IPC
 SG_ HudSwtch_B_Stat : 11|1@0+ (1,0) [0|1] "SED"  APIM_CDC,APIM_CIM,APIM_CISM,IPC
 SG_ HudVertSzMnuOn_B_Stat : 12|1@0+ (1,0) [0|1] "SED"  APIM_CDC,APIM_CIM,APIM_CISM,IPC
 SG_ HudMsgTxt_D_Rq : 15|3@0+ (1,0) [0|7] "SED"  APIM_CDC,APIM_CIM,APIM_CISM,IPC

BO_ 556 BCP_Status_Message_HS3: 8 GWM
 SG_ PassRstrnInd_Stat : 5|3@0+ (1,0) [0|7] "SED"  GENERIC
 SG_ DrvAsstMnuButtn_B_Stat : 7|1@0+ (1,0) [0|1] "SED"  APIM,APIM_CDC,APIM_CIM,APIM_CISM
 SG_ Bezel_Beeps_Supported : 9|2@0+ (1,0) [0|3] "SED"  APIM,APIM_CDC,APIM_CIM,APIM_CISM
 SG_ Bezel_Beep_St : 11|2@0+ (1,0) [0|3] "SED"  APIM,APIM_CDC,APIM_CIM,APIM_CISM
 SG_ EFP_Bezel_Diag_St : 15|4@0+ (1,0) [0|15] "SED"  APIM,APIM_CDC,APIM_CIM,APIM_CISM
 SG_ Manual_Temp_Setting : 23|5@0+ (1,0) [0|31] "SED"  ACM,APIM,APIM_CDC,APIM_CIM,APIM_CISM

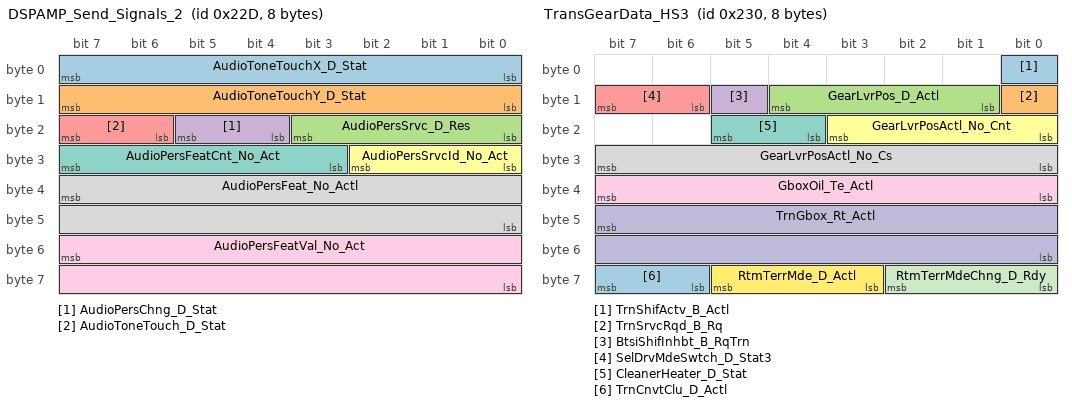
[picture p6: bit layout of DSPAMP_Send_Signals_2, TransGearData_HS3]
BO_ 557 DSPAMP_Send_Signals_2: 8 DSP
 SG_ AudioToneTouchX_D_Stat : 7|8@0+ (1,0) [0|255] "SED"  APIM,APIM_CDC,APIM_CIM,APIM_CISM
 SG_ AudioToneTouchY_D_Stat : 15|8@0+ (1,0) [0|255] "SED"  APIM,APIM_CDC,APIM_CIM,APIM_CISM
 SG_ AudioPersSrvc_D_Res : 19|4@0+ (1,0) [0|15] "SED"  GWM
 SG_ AudioPersChng_D_Stat : 21|2@0+ (1,0) [0|3] "SED"  GWM
 SG_ AudioToneTouch_D_Stat : 23|2@0+ (1,0) [0|3] "SED"  APIM,APIM_CDC,APIM_CIM,APIM_CISM
 SG_ AudioPersSrvcId_No_Act : 26|3@0+ (1,0) [0|7] "unitless"  GWM
 SG_ AudioPersFeatCnt_No_Act : 31|5@0+ (1,0) [0|31] "unitless"  GWM
 SG_ AudioPersFeat_No_Actl : 39|16@0+ (1,0) [0|65535] "unitless"  GWM
 SG_ AudioPersFeatVal_No_Act : 55|16@0+ (1,0) [0|65535] "unitless"  GWM

BO_ 558 ElecHorizon_Data1: 8 GWM
 SG_ EhData1_No_Actl : 7|64@0+ (1,0) [0|1.84467440737096E+019] "unitless"  APIM_CDC,GWM,HUD_ADV

BO_ 559 ElecHorizon_Data2: 8 GWM
 SG_ EhData2_No_Actl : 7|64@0+ (1,0) [0|1.84467440737096E+019] "unitless"  APIM_CDC,GWM,HUD_ADV

BO_ 560 TransGearData_HS3: 8 GWM
 SG_ TrnShifActv_B_Actl : 0|1@0+ (1,0) [0|1] "SED" Vector__XXX
 SG_ TrnSrvcRqd_B_Rq : 8|1@0+ (1,0) [0|1] "SED"  APIM_CDC,APIM_CIM,IPC
 SG_ GearLvrPos_D_Actl : 12|4@0+ (1,0) [0|15] "SED"  ACM,APIM,APIM_CDC,APIM_CIM,APIM_CISM,DSP,IPC,TRM_ITRM
 SG_ BtsiShifInhbt_B_RqTrn : 13|1@0+ (1,0) [0|1] "SED" Vector__XXX
 SG_ SelDrvMdeSwtch_D_Stat3 : 15|2@0+ (1,0) [0|3] "SED" Vector__XXX
 SG_ GearLvrPosActl_No_Cnt : 19|4@0+ (1,0) [0|15] "unitless"  TRM_ITRM
 SG_ CleanerHeater_D_Stat : 21|2@0+ (1,0) [0|3] "SED" Vector__XXX
 SG_ GearLvrPosActl_No_Cs : 31|8@0+ (1,0) [0|255] "unitless"  TRM_ITRM
 SG_ GboxOil_Te_Actl : 39|8@0+ (1,-60) [-60|195] "degC"  APIM,APIM_CDC,APIM_CIM,APIM_CISM,IPC
 SG_ TrnGbox_Rt_Actl : 47|16@0+ (0.001,0) [0|65.535] "unitless" Vector__XXX
 SG_ RtmTerrMdeChng_D_Rdy : 58|3@0+ (1,0) [0|7] "SED" Vector__XXX
 SG_ RtmTerrMde_D_Actl : 61|3@0+ (1,0) [0|7] "SED" Vector__XXX
 SG_ TrnCnvtClu_D_Actl : 63|2@0+ (1,0) [0|3] "SED" Vector__XXX

BO_ 561 TransGearData_2_HS3: 8 GWM
 SG_ TrnMsgTxt_D_Rq : 23|4@0+ (1,0) [0|15] "SED"  APIM_CDC,APIM_CIM,IPC
 SG_ TrnMsgTxt2_D_Rq : 39|3@0+ (1,0) [0|7] "SED"  APIM_CDC,APIM_CIM,APIM_CISM,IPC

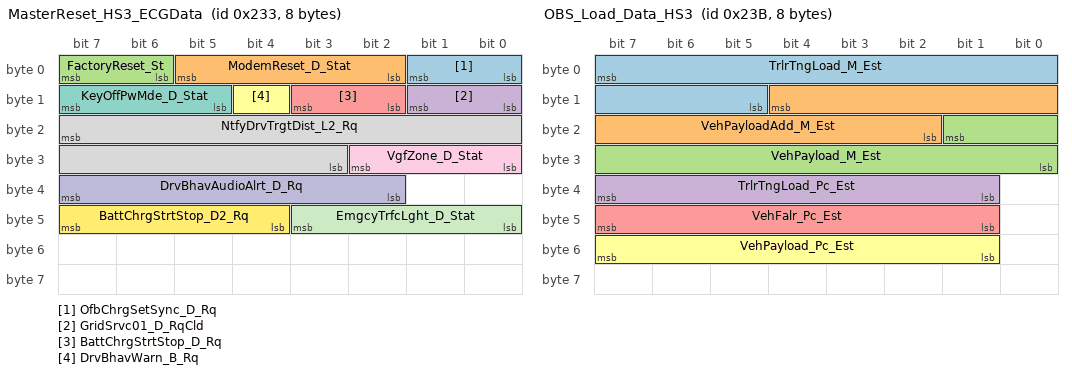
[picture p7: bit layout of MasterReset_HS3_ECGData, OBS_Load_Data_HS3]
BO_ 563 MasterReset_HS3_ECGData: 8 GWM
 SG_ OfbChrgSetSync_D_Rq : 1|2@0+ (1,0) [0|3] "SED"  APIM,APIM_CDC,APIM_CIM,APIM_CISM
 SG_ ModemReset_D_Stat : 5|4@0+ (1,0) [0|15] "SED"  ACM,APIM,APIM_CDC,APIM_CIM,APIM_CISM
 SG_ FactoryReset_St : 7|2@0+ (1,0) [0|3] "SED"  ACM,APIM,APIM_CDC,APIM_CIM,APIM_CISM
 SG_ GridSrvc01_D_RqCld : 9|2@0+ (1,0) [0|3] "SED"  APIM,APIM_CDC,APIM_CIM,APIM_CISM
 SG_ BattChrgStrtStop_D_Rq : 11|2@0+ (1,0) [0|3] "SED"  GENERIC
 SG_ DrvBhavWarn_B_Rq : 12|1@0+ (1,0) [0|1] "SED"  APIM_CDC,APIM_CIM,IPC
 SG_ KeyOffPwMde_D_Stat : 15|3@0+ (1,0) [0|7] "SED"  APIM,APIM_CDC,APIM_CIM,APIM_CISM
 SG_ NtfyDrvTrgtDist_L2_Rq : 23|13@0+ (0.1,0) [0|819.1] "Km" Vector__XXX
 SG_ VgfZone_D_Stat : 26|3@0+ (1,0) [0|7] "SED"  APIM_CDC,IPC
 SG_ DrvBhavAudioAlrt_D_Rq : 39|6@0+ (1,0) [0|63] "SED"  APIM,APIM_CDC,APIM_CIM,APIM_CISM
 SG_ EmgcyTrfcLght_D_Stat : 43|4@0+ (1,0) [0|15] "SED"  APIM_CDC,APIM_CIM
 SG_ BattChrgStrtStop_D2_Rq : 47|4@0+ (1,0) [0|15] "SED" Vector__XXX

BO_ 571 OBS_Load_Data_HS3: 8 GWM
 SG_ TrlrTngLoad_M_Est : 7|11@0+ (10,-10240) [-10240|10230] "kilogram"  APIM,APIM_CDC,APIM_CIM,APIM_CISM
 SG_ VehPayloadAdd_M_Est : 12|11@0+ (5,-5115) [-5115|5120] "kilogram"  APIM,APIM_CDC,APIM_CIM,APIM_CISM
 SG_ VehPayload_M_Est : 17|10@0+ (5,0) [0|5115] "kilogram"  APIM,APIM_CDC,APIM_CIM,APIM_CISM
 SG_ TrlrTngLoad_Pc_Est : 39|7@0+ (1,0) [0|127] "percent"  APIM,APIM_CDC,APIM_CIM,APIM_CISM
 SG_ VehFalr_Pc_Est : 47|7@0+ (1,0) [0|127] "percent"  APIM,APIM_CDC,APIM_CIM,APIM_CISM
 SG_ VehPayload_Pc_Est : 55|7@0+ (1,0) [0|127] "percent"  APIM,APIM_CDC,APIM_CIM,APIM_CISM

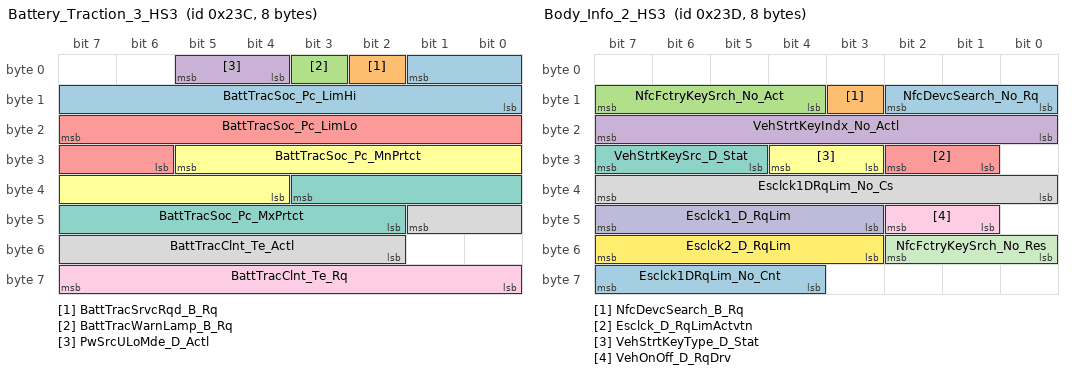
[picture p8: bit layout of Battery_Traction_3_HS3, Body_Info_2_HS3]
BO_ 572 Battery_Traction_3_HS3: 8 GWM
 SG_ BattTracSoc_Pc_LimHi : 1|10@0+ (0.1,0) [0|100] "%" Vector__XXX
 SG_ BattTracSrvcRqd_B_Rq : 2|1@0+ (1,0) [0|1] "SED"  APIM_CDC,APIM_CIM,IPC
 SG_ BattTracWarnLamp_B_Rq : 3|1@0+ (1,0) [0|1] "SED"  APIM_CDC,APIM_CIM,IPC
 SG_ PwSrcULoMde_D_Actl : 5|2@0+ (1,0) [0|3] "SED" Vector__XXX
 SG_ BattTracSoc_Pc_LimLo : 23|10@0+ (0.1,0) [0|100] "%" Vector__XXX
 SG_ BattTracSoc_Pc_MnPrtct : 29|10@0+ (0.1,0) [0|100] "%" Vector__XXX
 SG_ BattTracSoc_Pc_MxPrtct : 35|10@0+ (0.1,0) [0|100] "%"  APIM,APIM_CDC,APIM_CIM,APIM_CISM
 SG_ BattTracClnt_Te_Actl : 41|8@0+ (0.5,-60) [-60|67.5] "degC" Vector__XXX
 SG_ BattTracClnt_Te_Rq : 63|8@0+ (0.5,-60) [-60|67.5] "degC" Vector__XXX

BO_ 573 Body_Info_2_HS3: 8 GWM
 SG_ NfcDevcSearch_No_Rq : 10|3@0+ (1,0) [0|7] "unitless" Vector__XXX
 SG_ NfcDevcSearch_B_Rq : 11|1@0+ (1,0) [0|1] "SED" Vector__XXX
 SG_ NfcFctryKeySrch_No_Act : 15|4@0+ (1,0) [0|15] "unitless" Vector__XXX
 SG_ VehStrtKeyIndx_No_Actl : 23|8@0+ (1,0) [0|255] "unitless"  APIM,APIM_CDC,APIM_CIM
 SG_ Esclck_D_RqLimActvtn : 26|2@0+ (1,0) [0|3] "SED" Vector__XXX
 SG_ VehStrtKeyType_D_Stat : 28|2@0+ (1,0) [0|3] "SED"  APIM,APIM_CDC,APIM_CIM
 SG_ VehStrtKeySrc_D_Stat : 31|3@0+ (1,0) [0|7] "SED"  APIM,APIM_CDC,APIM_CIM
 SG_ Esclck1DRqLim_No_Cs : 39|8@0+ (1,0) [0|255] "unitless" Vector__XXX
 SG_ VehOnOff_D_RqDrv : 42|2@0+ (1,0) [0|3] "SED" Vector__XXX
 SG_ Esclck1_D_RqLim : 47|5@0+ (1,0) [0|31] "SED" Vector__XXX
 SG_ NfcFctryKeySrch_No_Res : 50|3@0+ (1,0) [0|7] "unitless" Vector__XXX
 SG_ Esclck2_D_RqLim : 55|5@0+ (1,0) [0|31] "SED" Vector__XXX
 SG_ Esclck1DRqLim_No_Cnt : 63|4@0+ (1,0) [0|15] "unitless" Vector__XXX

BO_ 576 AUDIO_RDISP2_WORD_Tx: 8 APIM_CDC
 SG_ AUDIO_RDISP2_WORD_Tx : 7|64@0+ (1,0) [0|1.84467440737096E+019] "unitless"  HUD_ADV

BO_ 577 NAV_RDISP2_WORD_Tx: 8 APIM_CDC
 SG_ NAV_RDISP2_WORD_Tx : 7|64@0+ (1,0) [0|1.84467440737096E+019] "unitless"  HUD_ADV

BO_ 578 CONMP_RDISP2_WORD_Tx: 8 APIM_CDC
 SG_ CONMP_RDISP2_WORD_Tx : 7|64@0+ (1,0) [0|1.84467440737096E+019] "unitless"  HUD_ADV

BO_ 579 PHONE_RDISP2_WORD_Tx: 8 APIM_CDC
 SG_ PHONE_RDISP2_WORD_Tx : 7|64@0+ (1,0) [0|1.84467440737096E+019] "unitless"  HUD_ADV

BO_ 581 TRAFFIC_RDISP_WORD_Tx_HS3: 8 GWM
 SG_ TRAFFIC_RDISP_WORD_Tx : 7|64@0+ (1,0) [0|1.84467440737096E+019] "unitless"  APIM,APIM_CDC,APIM_CIM,APIM_CISM

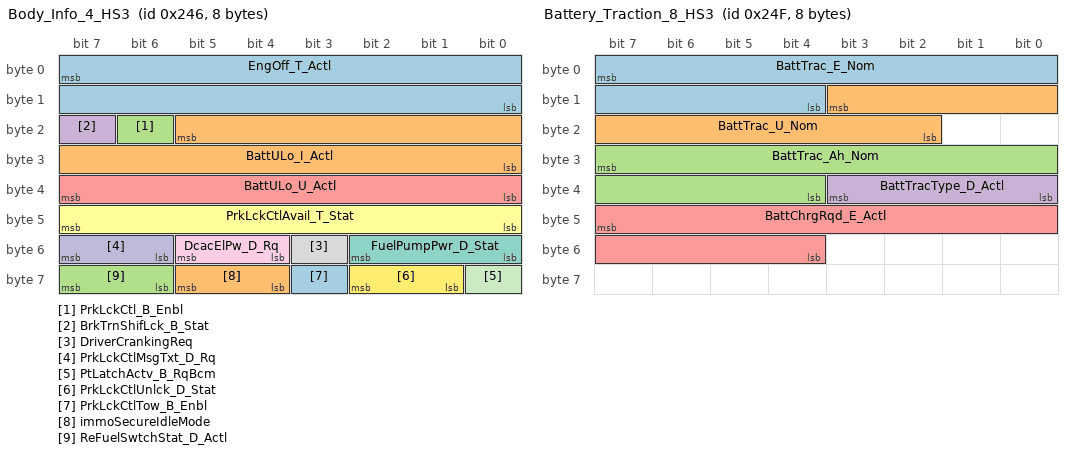
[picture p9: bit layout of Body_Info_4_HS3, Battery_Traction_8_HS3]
BO_ 582 Body_Info_4_HS3: 8 GWM
 SG_ EngOff_T_Actl : 7|16@0+ (1,0) [0|65535] "second^0.5"  APIM_CDC,APIM_CIM,IPC
 SG_ BattULo_I_Actl : 21|14@0+ (0.0625,-512) [-512|511.9375] "ampere" Vector__XXX
 SG_ PrkLckCtl_B_Enbl : 22|1@0+ (1,0) [0|1] "SED"  APIM,APIM_CDC,APIM_CIM,APIM_CISM,IPC
 SG_ BrkTrnShifLck_B_Stat : 23|1@0+ (1,0) [0|1] "SED" Vector__XXX
 SG_ BattULo_U_Actl : 39|8@0+ (0.0625,0) [0|15.9375] "volt" Vector__XXX
 SG_ PrkLckCtlAvail_T_Stat : 47|8@0+ (1,0) [0|255] "second"  APIM_CDC,APIM_CIM,IPC
 SG_ FuelPumpPwr_D_Stat : 50|3@0+ (1,0) [0|7] "SED" Vector__XXX
 SG_ DriverCrankingReq : 51|1@0+ (1,0) [0|1] "SED" Vector__XXX
 SG_ DcacElPw_D_Rq : 53|2@0+ (1,0) [0|3] "SED" Vector__XXX
 SG_ PrkLckCtlMsgTxt_D_Rq : 55|2@0+ (1,0) [0|3] "SED"  APIM_CDC,APIM_CIM,IPC
 SG_ PtLatchActv_B_RqBcm : 56|1@0+ (1,0) [0|1] "SED"  APIM_CDC,APIM_CIM,IPC
 SG_ PrkLckCtlUnlck_D_Stat : 58|2@0+ (1,0) [0|3] "SED"  APIM_CDC,APIM_CIM,IPC
 SG_ PrkLckCtlTow_B_Enbl : 59|1@0+ (1,0) [0|1] "SED"  APIM_CDC,APIM_CIM,IPC
 SG_ immoSecureIdleMode : 61|2@0+ (1,0) [0|3] "SED"  APIM,APIM_CDC,APIM_CIM,APIM_CISM
 SG_ ReFuelSwtchStat_D_Actl : 63|2@0+ (1,0) [0|3] "SED" Vector__XXX

BO_ 584 AUDIO_RDISP2_WORD_Rx: 8 HUD_ADV
 SG_ AUDIO_RDISP2_WORD_Rx : 7|64@0+ (1,0) [0|1.84467440737096E+019] "unitless"  ACM,APIM_CDC,APIM_CIM,APIM_CISM

BO_ 585 NAV_RDISP2_WORD_Rx: 8 HUD_ADV
 SG_ NAV_RDISP2_WORD_Rx : 7|64@0+ (1,0) [0|1.84467440737096E+019] "unitless"  APIM,APIM_CDC,APIM_CIM,APIM_CISM

BO_ 586 CONMP_RDISP2_WORD_Rx: 8 HUD_ADV
 SG_ CONMP_RDISP2_WORD_Rx : 7|64@0+ (1,0) [0|1.84467440737096E+019] "unitless"  APIM,APIM_CDC,APIM_CIM,APIM_CISM

BO_ 587 PHONE_RDISP2_WORD_Rx: 8 HUD_ADV
 SG_ PHONE_RDISP2_WORD_Rx : 7|64@0+ (1,0) [0|1.84467440737096E+019] "unitless"  ACM,APIM,APIM_CDC,APIM_CIM,APIM_CISM

BO_ 588 RDRV_RDISP2_WORD_Rx: 8 HUD_ADV
 SG_ RDRV_RDISP2_WORD_Rx : 7|64@0+ (1,0) [0|1.84467440737096E+019] "unitless"  APIM,GENERIC

BO_ 589 TRAFFIC_RDISP_WORD_Rx: 8 APIM_CDC
 SG_ TRAFFIC_RDISP_WORD_Rx : 7|64@0+ (1,0) [0|1.84467440737096E+019] "unitless"  GWM

BO_ 591 Battery_Traction_8_HS3: 8 GWM
 SG_ BattTrac_E_Nom : 7|12@0+ (50,0) [0|204750] "watt*hr"  APIM,APIM_CDC,APIM_CIM,APIM_CISM
 SG_ BattTrac_U_Nom : 11|10@0+ (0.5,0) [0|511.5] "volt" Vector__XXX
 SG_ BattTrac_Ah_Nom : 31|12@0+ (0.1,0) [0|409.5] "ampere*hour" Vector__XXX
 SG_ BattTracType_D_Actl : 35|4@0+ (1,0) [0|15] "SED" Vector__XXX
 SG_ BattChrgRqd_E_Actl : 47|12@0+ (50,0) [0|204750] "watt*hour" Vector__XXX

BO_ 592 RFA_BLEM_APIM_Tx_HS3: 8 GWM
 SG_ RFA_BLEM_APIM_Tx : 7|64@0+ (1,0) [0|1.84467440737096E+019] "unitless"  APIM,APIM_CDC,APIM_CIM,APIM_CISM

BO_ 593 ECG_MC_WORD_Tx: 8 GWM
 SG_ ECG_MC_WORD_Tx : 7|64@0+ (1,0) [0|1.84467440737096E+019] "unitless"  APIM_CDC,IPC

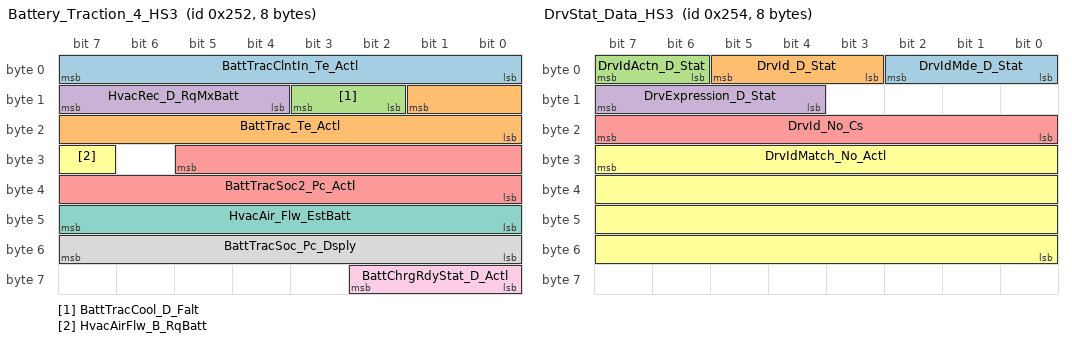
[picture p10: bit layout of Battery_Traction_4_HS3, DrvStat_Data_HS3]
BO_ 594 Battery_Traction_4_HS3: 8 GWM
 SG_ BattTracClntIn_Te_Actl : 7|8@0+ (1,-50) [-50|205] "degC" Vector__XXX
 SG_ BattTrac_Te_Actl : 9|10@0+ (0.5,-50) [-50|461.5] "degC" Vector__XXX
 SG_ BattTracCool_D_Falt : 11|2@0+ (1,0) [0|3] "SED" Vector__XXX
 SG_ HvacRec_D_RqMxBatt : 15|4@0+ (1,0) [0|15] "SED" Vector__XXX
 SG_ BattTracSoc2_Pc_Actl : 29|14@0+ (0.01,0) [0|163.83] "%" Vector__XXX
 SG_ HvacAirFlw_B_RqBatt : 31|1@0+ (1,0) [0|1] "SED" Vector__XXX
 SG_ HvacAir_Flw_EstBatt : 47|8@0+ (0.5,0) [0|127.5] "liter/second" Vector__XXX
 SG_ BattTracSoc_Pc_Dsply : 55|8@0+ (0.5,0) [0|127.5] "Percent"  APIM,APIM_CDC,APIM_CIM,APIM_CISM,HUD_ADV,IPC
 SG_ BattChrgRdyStat_D_Actl : 58|3@0+ (1,0) [0|7] "SED" Vector__XXX

BO_ 595 APIM_Send_Signals_7: 8 APIM_CDC
 SG_ TrakAppl_D_RqMnu : 4|5@0+ (1,0) [0|31] "SED"  GWM,IPC
 SG_ DrvIdMde_D_Rq : 7|3@0+ (1,0) [0|7] "SED"  GWM
 SG_ DrvIdDelete_No_Rq : 15|32@0+ (1,0) [0|4294967295] "Unitless"  GWM
 SG_ EngIdlShutDownT_D_Rq : 47|8@0+ (1,0) [0|255] "SED"  GWM
 SG_ TrakApplActvSet_D_Rq : 55|4@0+ (1,0) [0|15] "SED"  GWM,IPC

BO_ 596 DrvStat_Data_HS3: 8 GWM
 SG_ DrvIdMde_D_Stat : 2|3@0+ (1,0) [0|7] "SED"  APIM,APIM_CDC,APIM_CIM,APIM_CISM
 SG_ DrvId_D_Stat : 5|3@0+ (1,0) [0|7] "SED"  APIM,APIM_CDC,APIM_CIM,APIM_CISM
 SG_ DrvIdActn_D_Stat : 7|2@0+ (1,0) [0|3] "SED"  APIM,APIM_CDC,APIM_CIM,APIM_CISM
 SG_ DrvExpression_D_Stat : 15|4@0+ (1,0) [0|15] "SED"  APIM,APIM_CDC,APIM_CIM,APIM_CISM
 SG_ DrvId_No_Cs : 23|8@0+ (1,0) [0|255] "unitless"  APIM,APIM_CDC,APIM_CIM,APIM_CISM
 SG_ DrvIdMatch_No_Actl : 31|32@0+ (1,0) [0|4294967295] "Unitless"  APIM,APIM_CDC,APIM_CIM,APIM_CISM

BO_ 597 AUDIO_RSE_WORD_Tx: 8 APIM_CIM
 SG_ AUDIO_RSE_WORD_Tx : 7|64@0+ (1,0) [0|1.84467440737096E+019] "unitless"  RACM_RCIM

BO_ 598 CONMP_RSE_WORD_Tx: 8 APIM_CDC
 SG_ CONMP_RSE_WORD_Tx : 7|64@0+ (1,0) [0|1.84467440737096E+019] "unitless"  RACM_RCIM

BO_ 600 APIM_RFA_BLEM_Tx: 8 APIM_CDC
 SG_ APIM_RFA_BLEM_Tx : 7|64@0+ (1,0) [0|1.84467440737096E+019] "unitless"  GWM

BO_ 601 ECG_MC_WORD_Rx: 8 APIM_CDC
 SG_ ECG_MC_WORD_Rx : 7|64@0+ (1,0) [0|1.84467440737096E+019] "unitless"  GWM

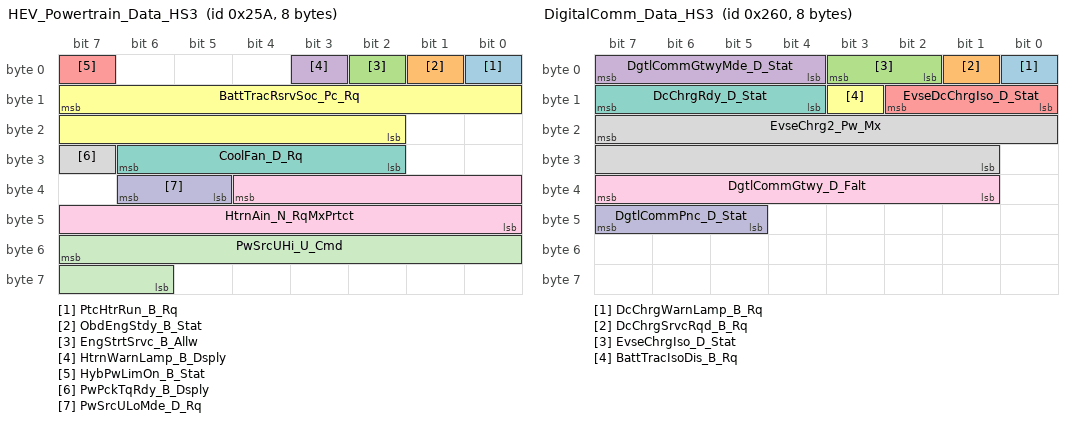
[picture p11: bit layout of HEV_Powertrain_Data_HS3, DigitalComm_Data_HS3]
BO_ 602 HEV_Powertrain_Data_HS3: 8 GWM
 SG_ PtcHtrRun_B_Rq : 0|1@0+ (1,0) [0|1] "SED" Vector__XXX
 SG_ ObdEngStdy_B_Stat : 1|1@0+ (1,0) [0|1] "SED" Vector__XXX
 SG_ EngStrtSrvc_B_Allw : 2|1@0+ (1,0) [0|1] "SED" Vector__XXX
 SG_ HtrnWarnLamp_B_Dsply : 3|1@0+ (1,0) [0|1] "SED"  APIM_CDC,APIM_CIM,IPC
 SG_ HybPwLimOn_B_Stat : 7|1@0+ (1,0) [0|1] "SED" Vector__XXX
 SG_ BattTracRsrvSoc_Pc_Rq : 15|14@0+ (0.01,0) [0|163.83] "percent" Vector__XXX
 SG_ CoolFan_D_Rq : 30|5@0+ (1,0) [0|31] "unitless" Vector__XXX
 SG_ PwPckTqRdy_B_Dsply : 31|1@0+ (1,0) [0|1] "SED"  APIM,APIM_CDC,APIM_CIM,APIM_CISM,IPC
 SG_ HtrnAin_N_RqMxPrtct : 36|13@0+ (2,0) [0|16382] "RPM" Vector__XXX
 SG_ PwSrcULoMde_D_Rq : 38|2@0+ (1,0) [0|3] "SED" Vector__XXX
 SG_ PwSrcUHi_U_Cmd : 55|10@0+ (0.5,0) [0|511.5] "volt" Vector__XXX

BO_ 605 AUDIO_RSE_WORD_Rx: 8 RACM_RCIM
 SG_ AUDIO_RSE_WORD_Rx : 7|64@0+ (1,0) [0|1.84467440737096E+019] "unitless"  ACM,APIM_CDC,APIM_CIM,APIM_CISM

BO_ 606 CONMP_RSE_WORD_Rx: 8 RACM_RCIM
 SG_ CONMP_RSE_WORD_Rx : 7|64@0+ (1,0) [0|1.84467440737096E+019] "unitless"  APIM,APIM_CDC,APIM_CIM,APIM_CISM

BO_ 607 RDRV_RSE_WORD_Rx: 8 RACM_RCIM
 SG_ RDRV_RSE_WORD_Rx : 7|64@0+ (1,0) [0|1.84467440737096E+019] "unitless"  GENERIC

BO_ 608 DigitalComm_Data_HS3: 8 GWM
 SG_ DcChrgWarnLamp_B_Rq : 0|1@0+ (1,0) [0|1] "SED"  APIM_CDC,APIM_CIM
 SG_ DcChrgSrvcRqd_B_Rq : 1|1@0+ (1,0) [0|1] "SED"  APIM_CDC,APIM_CIM,IPC
 SG_ EvseChrgIso_D_Stat : 3|2@0+ (1,0) [0|3] "SED" Vector__XXX
 SG_ DgtlCommGtwyMde_D_Stat : 7|4@0+ (1,0) [0|15] "SED" Vector__XXX
 SG_ EvseDcChrgIso_D_Stat : 10|3@0+ (1,0) [0|7] "SED" Vector__XXX
 SG_ BattTracIsoDis_B_Rq : 11|1@0+ (1,0) [0|1] "SED" Vector__XXX
 SG_ DcChrgRdy_D_Stat : 15|4@0+ (1,0) [0|15] "SED" Vector__XXX
 SG_ EvseChrg2_Pw_Mx : 23|15@0+ (50,0) [0|1638350] "watts" Vector__XXX
 SG_ DgtlCommGtwy_D_Falt : 39|7@0+ (1,0) [0|127] "SED" Vector__XXX
 SG_ DgtlCommPnc_D_Stat : 47|3@0+ (1,0) [0|7] "SED" Vector__XXX

BO_ 610 AWD_Display_Stat_HS3: 8 GWM
 SG_ AwdLckWhlFl_Pc_RqDsply : 7|7@0+ (1,0) [0|127] "percent"  APIM_CDC,APIM_CIM,IPC
 SG_ AwdLckWhlFr_Pc_RqDsply : 15|7@0+ (1,0) [0|127] "percent"  APIM_CDC,APIM_CIM,IPC
 SG_ AwdLckWhlRl_Pc_RqDsply : 23|7@0+ (1,0) [0|127] "percent"  APIM_CDC,APIM_CIM,IPC
 SG_ AwdLckWhlRr_Pc_RqDsply : 31|7@0+ (1,0) [0|127] "percent"  APIM_CDC,APIM_CIM,IPC

BO_ 611 Driveline_Data_1_HS3: 8 GWM
 SG_ AwdSrvcRqd_B_Rq : 0|1@0+ (1,0) [0|1] "SED"  APIM_CDC,APIM_CIM,IPC
 SG_ Awd2wdLamp_D_RqDsply : 2|2@0+ (1,0) [0|3] "SED"  APIM,APIM_CDC,APIM_CIM,APIM_CISM,HUD_ADV,IPC
 SG_ NtrlTowAvail_B_Stat : 4|1@0+ (1,0) [0|1] "SED"  APIM_CDC,APIM_CIM,IPC
 SG_ AwdRnge_D_Actl : 7|3@0+ (1,0) [0|7] "SED"  ACM,APIM,APIM_CDC,APIM_CIM,APIM_CISM,IPC
 SG_ AwdLck_Tq_Rq : 15|12@0+ (1,0) [0|4095] "Nm"  APIM_CDC,APIM_CIM,APIM_CISM,IPC
 SG_ AwdAutoLamp_D_RqDsply : 17|2@0+ (1,0) [0|3] "SED"  APIM,APIM_CDC,APIM_CIM,APIM_CISM,HUD_ADV,IPC
 SG_ AwdHiLamp_D_RqDsply : 19|2@0+ (1,0) [0|3] "SED"  APIM,APIM_CDC,APIM_CIM,APIM_CISM,HUD_ADV,IPC
 SG_ AwdOffRoadMode_D_Stats : 25|2@0+ (1,0) [0|3] "SED"  APIM,APIM_CDC,APIM_CIM,APIM_CISM,IPC
 SG_ AwdSys_D_Stat : 27|2@0+ (1,0) [0|3] "SED"  IPC
 SG_ AwdLck_D_Stat : 31|4@0+ (1,0) [0|15] "SED"  IPC
 SG_ SelDrvMdeAwd_D_Stat : 33|2@0+ (1,0) [0|3] "SED"  GENERIC
 SG_ AwdLoLamp_D_RqDsply : 35|2@0+ (1,0) [0|3] "SED"  APIM,APIM_CDC,APIM_CIM,APIM_CISM,HUD_ADV,IPC
 SG_ AwdDrvMde_D_Stat : 38|3@0+ (1,0) [0|7] "SED"  APIM,APIM_CDC,APIM_CIM,APIM_CISM,IPC
 SG_ TrnAout_Tq_RqMx : 47|13@0+ (1,-1250) [-1250|6941] "Nm"  IPC
 SG_ AwdTerrMde_D_Actl : 50|3@0+ (1,0) [0|7] "SED"  IPC
 SG_ AwdTerrMdeChng_D_Rdy : 58|3@0+ (1,0) [0|7] "SED"  IPC
 SG_ AwdStat_D_RqDsply : 63|5@0+ (1,0) [0|31] "SED"  APIM_CDC,APIM_CIM,IPC

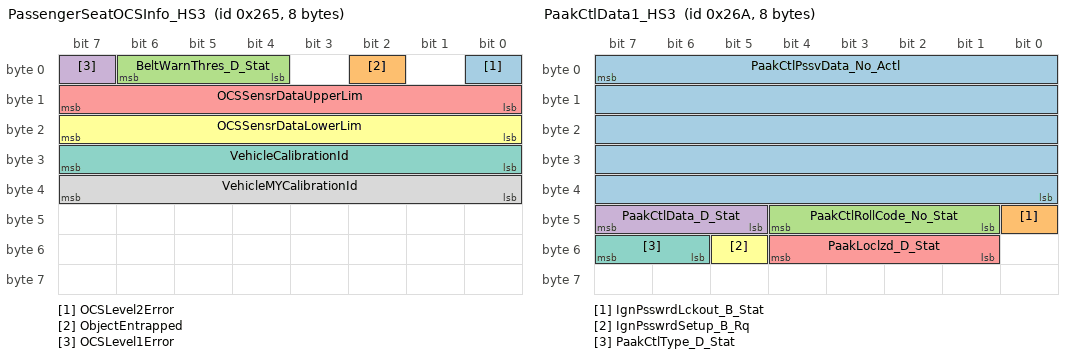
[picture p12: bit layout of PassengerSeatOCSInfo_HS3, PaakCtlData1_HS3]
BO_ 613 PassengerSeatOCSInfo_HS3: 8 GWM
 SG_ OCSLevel2Error : 0|1@0+ (1,0) [0|1] "SED" Vector__XXX
 SG_ ObjectEntrapped : 2|1@0+ (1,0) [0|1] "SED"  APIM_CDC,APIM_CIM,IPC
 SG_ BeltWarnThres_D_Stat : 6|3@0+ (1,0) [0|7] "SED" Vector__XXX
 SG_ OCSLevel1Error : 7|1@0+ (1,0) [0|1] "SED" Vector__XXX
 SG_ OCSSensrDataUpperLim : 15|8@0+ (1,0) [0|255] "SED" Vector__XXX
 SG_ OCSSensrDataLowerLim : 23|8@0+ (1,0) [0|255] "SED" Vector__XXX
 SG_ VehicleCalibrationId : 31|8@0+ (1,0) [0|255] "SED" Vector__XXX
 SG_ VehicleMYCalibrationId : 39|8@0+ (1,0) [0|255] "SED" Vector__XXX

BO_ 618 PaakCtlData1_HS3: 8 GWM
 SG_ PaakCtlPssvData_No_Actl : 7|40@0+ (1,0) [0|1099511627775] "unitless" Vector__XXX
 SG_ IgnPsswrdLckout_B_Stat : 40|1@0+ (1,0) [0|1] "SED"  APIM,APIM_CDC,APIM_CIM,APIM_CISM
 SG_ PaakCtlRollCode_No_Stat : 44|4@0+ (1,0) [0|15] "unitless" Vector__XXX
 SG_ PaakCtlData_D_Stat : 47|3@0+ (1,0) [0|7] "SED" Vector__XXX
 SG_ PaakLoclzd_D_Stat : 52|4@0+ (1,0) [0|15] "SED" Vector__XXX
 SG_ IgnPsswrdSetup_B_Rq : 53|1@0+ (1,0) [0|1] "SED"  APIM,APIM_CDC,APIM_CIM,APIM_CISM
 SG_ PaakCtlType_D_Stat : 55|2@0+ (1,0) [0|3] "SED" Vector__XXX

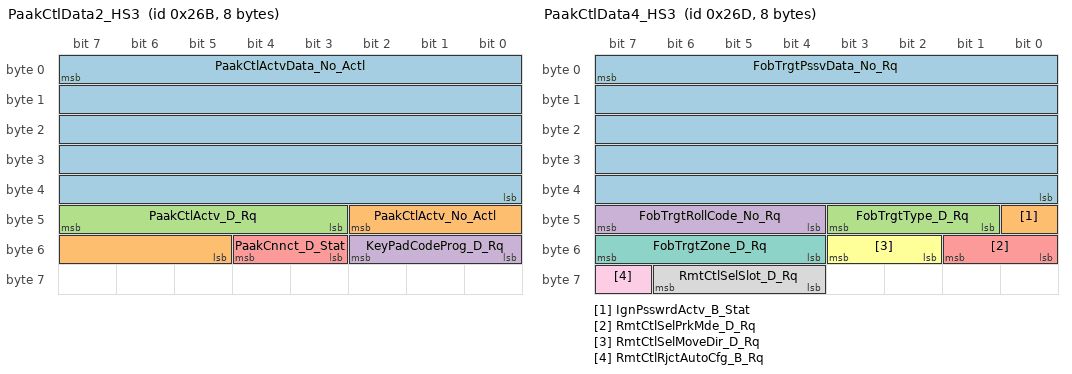
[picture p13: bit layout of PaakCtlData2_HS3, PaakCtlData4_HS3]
BO_ 619 PaakCtlData2_HS3: 8 GWM
 SG_ PaakCtlActvData_No_Actl : 7|40@0+ (1,0) [0|1099511627775] "unitless" Vector__XXX
 SG_ PaakCtlActv_No_Actl : 42|6@0+ (1,0) [0|63] "unitless" Vector__XXX
 SG_ PaakCtlActv_D_Rq : 47|5@0+ (1,0) [0|31] "SED" Vector__XXX
 SG_ KeyPadCodeProg_D_Rq : 50|3@0+ (1,0) [0|7] "SED" Vector__XXX
 SG_ PaakCnnct_D_Stat : 52|2@0+ (1,0) [0|3] "SED"  APIM,APIM_CDC,APIM_CIM,APIM_CISM

BO_ 621 PaakCtlData4_HS3: 8 GWM
 SG_ FobTrgtPssvData_No_Rq : 7|40@0+ (1,0) [0|1099511627775] "Encrypted" Vector__XXX
 SG_ IgnPsswrdActv_B_Stat : 40|1@0+ (1,0) [0|1] "SED"  APIM,APIM_CDC,APIM_CIM,APIM_CISM
 SG_ FobTrgtType_D_Rq : 43|3@0+ (1,0) [0|7] "SED" Vector__XXX
 SG_ FobTrgtRollCode_No_Rq : 47|4@0+ (1,0) [0|15] "unitless" Vector__XXX
 SG_ RmtCtlSelPrkMde_D_Rq : 49|2@0+ (1,0) [0|3] "SED" Vector__XXX
 SG_ RmtCtlSelMoveDir_D_Rq : 51|2@0+ (1,0) [0|3] "SED" Vector__XXX
 SG_ FobTrgtZone_D_Rq : 55|4@0+ (1,0) [0|15] "SED" Vector__XXX
 SG_ RmtCtlSelSlot_D_Rq : 62|3@0+ (1,0) [0|7] "SED" Vector__XXX
 SG_ RmtCtlRjctAutoCfg_B_Rq : 63|1@0+ (1,0) [0|1] "SED" Vector__XXX

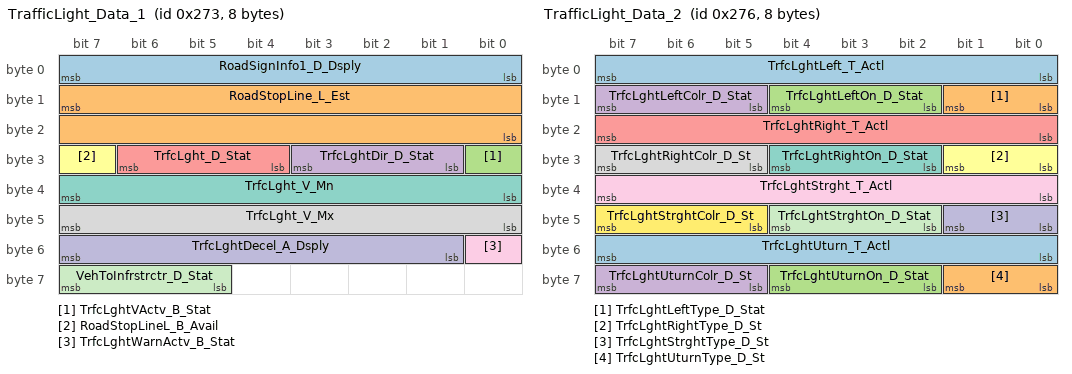
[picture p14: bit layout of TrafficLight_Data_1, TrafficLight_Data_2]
BO_ 627 TrafficLight_Data_1: 8 APIM_CDC
 SG_ RoadSignInfo1_D_Dsply : 7|8@0+ (1,0) [0|255] "SED"  GWM,IPC
 SG_ RoadStopLine_L_Est : 15|16@0+ (1,0) [0|65535] "cm"  GWM,IPC
 SG_ TrfcLghtVActv_B_Stat : 24|1@0+ (1,0) [0|1] "SED"  GWM,IPC
 SG_ TrfcLghtDir_D_Stat : 27|3@0+ (1,0) [0|7] "SED"  GWM,HUD_ADV,IPC
 SG_ TrfcLght_D_Stat : 30|3@0+ (1,0) [0|7] "SED"  GWM,HUD_ADV,IPC
 SG_ RoadStopLineL_B_Avail : 31|1@0+ (1,0) [0|1] "SED"  GWM,IPC
 SG_ TrfcLght_V_Mn : 39|8@0+ (1,0) [0|255] "km/hour"  GWM,IPC
 SG_ TrfcLght_V_Mx : 47|8@0+ (1,0) [0|255] "km/hour"  GWM,IPC
 SG_ TrfcLghtWarnActv_B_Stat : 48|1@0+ (1,0) [0|1] "SED"  GWM,HUD_ADV,IPC
 SG_ TrfcLghtDecel_A_Dsply : 55|7@0+ (1,0) [0|127] "km/hour"  GWM,HUD_ADV,IPC
 SG_ VehToInfrstrctr_D_Stat : 63|3@0+ (1,0) [0|7] "SED"  GWM,HUD_ADV,IPC

BO_ 630 TrafficLight_Data_2: 8 APIM_CDC
 SG_ TrfcLghtLeft_T_Actl : 7|8@0+ (1,0) [0|255] "second"  GWM,HUD_ADV,IPC
 SG_ TrfcLghtLeftType_D_Stat : 9|2@0+ (1,0) [0|3] "SED"  GWM,HUD_ADV,IPC
 SG_ TrfcLghtLeftOn_D_Stat : 12|3@0+ (1,0) [0|7] "SED"  GWM,HUD_ADV,IPC
 SG_ TrfcLghtLeftColr_D_Stat : 15|3@0+ (1,0) [0|7] "SED"  GWM,HUD_ADV,IPC
 SG_ TrfcLghtRight_T_Actl : 23|8@0+ (1,0) [0|255] "second"  GWM,HUD_ADV,IPC
 SG_ TrfcLghtRightType_D_St : 25|2@0+ (1,0) [0|3] "SED"  GWM,HUD_ADV,IPC
 SG_ TrfcLghtRightOn_D_Stat : 28|3@0+ (1,0) [0|7] "SED"  GWM,HUD_ADV,IPC
 SG_ TrfcLghtRightColr_D_St : 31|3@0+ (1,0) [0|7] "SED"  GWM,HUD_ADV,IPC
 SG_ TrfcLghtStrght_T_Actl : 39|8@0+ (1,0) [0|255] "second"  GWM,HUD_ADV,IPC
 SG_ TrfcLghtStrghtType_D_St : 41|2@0+ (1,0) [0|3] "SED"  GWM,HUD_ADV,IPC
 SG_ TrfcLghtStrghtOn_D_Stat : 44|3@0+ (1,0) [0|7] "SED"  GWM,HUD_ADV,IPC
 SG_ TrfcLghtStrghtColr_D_St : 47|3@0+ (1,0) [0|7] "SED"  GWM,HUD_ADV,IPC
 SG_ TrfcLghtUturn_T_Actl : 55|8@0+ (1,0) [0|255] "second"  GWM,HUD_ADV,IPC
 SG_ TrfcLghtUturnType_D_St : 57|2@0+ (1,0) [0|3] "SED"  GWM,HUD_ADV,IPC
 SG_ TrfcLghtUturnOn_D_Stat : 60|3@0+ (1,0) [0|7] "SED"  GWM,HUD_ADV,IPC
 SG_ TrfcLghtUturnColr_D_St : 63|3@0+ (1,0) [0|7] "SED"  GWM,HUD_ADV,IPC

BO_ 636 TCU_Send_Signals_3_HS3: 8 GWM
 SG_ WifiHtsptCrdntl_B_Stat : 0|1@0+ (1,0) [0|1] "SED"  APIM,APIM_CDC,APIM_CIM,APIM_CISM
 SG_ WifiHtsptEnbl_D_Stat : 2|2@0+ (1,0) [0|3] "SED"  APIM,APIM_CDC,APIM_CIM,APIM_CISM
 SG_ WifiEnbl_D_Stat : 4|2@0+ (1,0) [0|3] "SED"  APIM,APIM_CDC,APIM_CIM,APIM_CISM
 SG_ WifiDevcListNew_B_Stat : 5|1@0+ (1,0) [0|1] "SED"  APIM,APIM_CDC,APIM_CIM,APIM_CISM
 SG_ WifiDataUsage_D_Stat : 7|2@0+ (1,0) [0|3] "SED"  APIM,APIM_CDC,APIM_CIM,APIM_CISM
 SG_ ModemSigStren_D_Stat : 11|3@0+ (1,0) [0|7] "SED"  ACM,APIM,APIM_CDC,APIM_CIM,APIM_CISM
 SG_ WifiHtsptVisbl_D_Stat : 13|2@0+ (1,0) [0|3] "SED"  APIM,APIM_CDC,APIM_CIM,APIM_CISM
 SG_ WifiHtsptScrty_D_Stat : 15|2@0+ (1,0) [0|3] "SED"  APIM,APIM_CDC,APIM_CIM,APIM_CISM
 SG_ WifiDataUsage_Pc_Actl : 20|4@0+ (5,50) [50|125] "percent"  APIM,APIM_CDC,APIM_CIM,APIM_CISM
 SG_ WifiHtsptCnnct_D_Stat : 26|2@0+ (1,0) [0|3] "SED"  APIM,APIM_CDC,APIM_CIM,APIM_CISM
 SG_ WifiDataUsageOn_D_Stat : 28|2@0+ (1,0) [0|3] "SED"  APIM,APIM_CDC,APIM_CIM,APIM_CISM
 SG_ ModemTechnology_D2_Stat : 31|3@0+ (1,0) [0|7] "SED"  APIM,APIM_CDC,APIM_CIM,APIM_CISM,HUD_ADV
 SG_ Telematics_D_Falt : 39|3@0+ (1,0) [0|7] "SED"  APIM,APIM_CDC,APIM_CIM,APIM_CISM
 SG_ WifiNoDevcCnnct_No_Actl : 47|8@0+ (1,0) [0|255] "unitless"  APIM,APIM_CDC,APIM_CIM,APIM_CISM
 SG_ WifiHtspt_D_Falt : 51|4@0+ (1,0) [0|15] "SED"  ACM,APIM,APIM_CDC,APIM_CIM,APIM_CISM
 SG_ WifiHtsptFqBand_D_Stat : 60|2@0+ (1,0) [0|3] "SED"  ACM,APIM,APIM_CDC,APIM_CIM,APIM_CISM
 SG_ WifiHtsptFq_D_Avail : 63|3@0+ (1,0) [0|7] "SED"  ACM,APIM,APIM_CDC,APIM_CIM,APIM_CISM

BO_ 638 TCU_Send_Signals_5_HS3: 8 GWM
 SG_ EmgcyCallCancl_T_Actl : 4|5@0+ (1,0) [0|31] "second"  APIM,APIM_CDC,APIM_CIM,APIM_CISM
 SG_ EmgcyCall_D_Stat : 7|3@0+ (1,0) [0|7] "SED"  APIM,APIM_CDC,APIM_CIM,APIM_CISM
 SG_ EmgcyCallHmi_D_Stat : 14|4@0+ (1,0) [0|15] "SED"  APIM,APIM_CDC,APIM_CIM,APIM_CISM
 SG_ EmgcyCallFalt_B_Dsply : 15|1@0+ (1,0) [0|1] "SED"  APIM_CDC,APIM_CIM,IPC

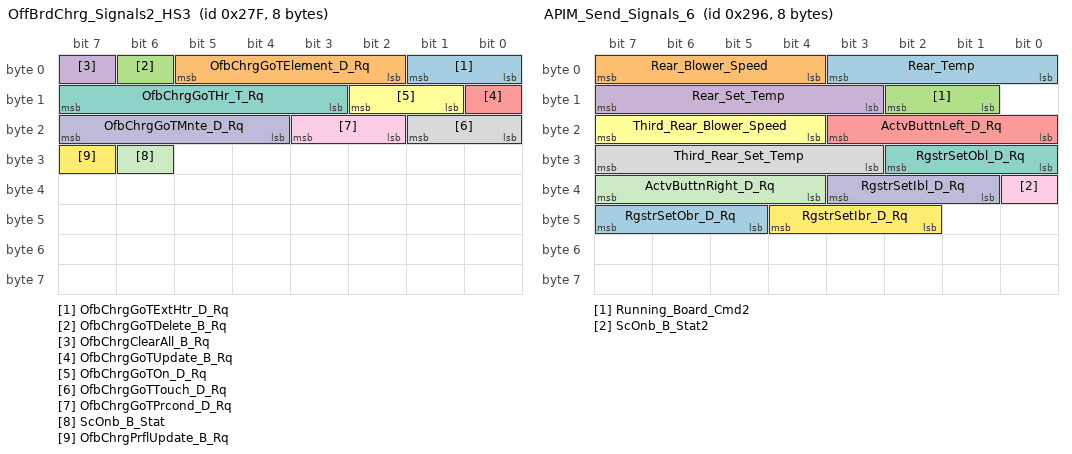
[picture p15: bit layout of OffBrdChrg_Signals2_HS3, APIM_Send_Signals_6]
BO_ 639 OffBrdChrg_Signals2_HS3: 8 GWM
 SG_ OfbChrgGoTExtHtr_D_Rq : 1|2@0+ (1,0) [0|3] "SED"  GENERIC
 SG_ OfbChrgGoTElement_D_Rq : 5|4@0+ (1,0) [0|15] "unitless"  GENERIC
 SG_ OfbChrgGoTDelete_B_Rq : 6|1@0+ (1,0) [0|1] "SED"  GENERIC
 SG_ OfbChrgClearAll_B_Rq : 7|1@0+ (1,0) [0|1] "SED"  GENERIC
 SG_ OfbChrgGoTUpdate_B_Rq : 8|1@0+ (1,0) [0|1] "SED"  APIM,APIM_CDC,APIM_CIM,APIM_CISM
 SG_ OfbChrgGoTOn_D_Rq : 10|2@0+ (1,0) [0|3] "SED"  GENERIC
 SG_ OfbChrgGoTHr_T_Rq : 15|5@0+ (1,0) [0|31] "hour"  GENERIC
 SG_ OfbChrgGoTTouch_D_Rq : 17|2@0+ (1,0) [0|3] "SED"  GENERIC
 SG_ OfbChrgGoTPrcond_D_Rq : 19|2@0+ (1,0) [0|3] "SED"  GENERIC
 SG_ OfbChrgGoTMnte_D_Rq : 23|4@0+ (1,0) [0|15] "minute"  GENERIC
 SG_ ScOnb_B_Stat : 30|1@0+ (1,0) [0|1] "SED"  APIM,APIM_CDC,APIM_CIM,APIM_CISM
 SG_ OfbChrgPrflUpdate_B_Rq : 31|1@0+ (1,0) [0|1] "SED"  APIM,APIM_CDC,APIM_CIM,APIM_CISM

BO_ 640 PwrFoldSeatRight_HS3: 8 GWM
 SG_ SeatFold3lButtn_D_Stat : 0|1@0+ (1,0) [0|1] "SED" Vector__XXX
 SG_ SeatFold3bButtn_D_Stat : 1|1@0+ (1,0) [0|1] "SED" Vector__XXX
 SG_ SeatBckMtnRl_D_Stat : 4|3@0+ (1,0) [0|7] "SED" Vector__XXX
 SG_ SeatBckMtn3l_D_Stat : 7|3@0+ (1,0) [0|7] "SED" Vector__XXX
 SG_ SeatBckPosRl_D_Stat : 11|4@0+ (1,0) [0|15] "SED" Vector__XXX
 SG_ SeatBckPos3l_D_Stat : 15|4@0+ (1,0) [0|15] "SED" Vector__XXX
 SG_ SeatFoldRrButtn_D_Stat : 16|1@0+ (1,0) [0|1] "SED" Vector__XXX
 SG_ SeatFoldRlButtn_D_Stat : 17|1@0+ (1,0) [0|1] "SED" Vector__XXX
 SG_ SeatFoldRbButtn_D_Stat : 18|1@0+ (1,0) [0|1] "SED" Vector__XXX
 SG_ SeatFold3rButtn_D_Stat : 19|1@0+ (1,0) [0|1] "SED" Vector__XXX
 SG_ SeatMtnRlMsgTxt_D_Rq : 23|4@0+ (1,0) [0|15] "SED"  APIM,APIM_CDC,APIM_CIM,APIM_CISM,IPC
 SG_ SeatSlidPosR2Drv_B_St : 24|1@0+ (1,0) [0|1] "SED" Vector__XXX
 SG_ SeatMovIdR2Drv_No_Actl : 27|3@0+ (1,0) [0|7] "unitless" Vector__XXX
 SG_ SeatMovR2Drv_D_Res : 31|4@0+ (1,0) [0|15] "SED" Vector__XXX
 SG_ SeatCalfRestR2Drv_B_St : 34|1@0+ (1,0) [0|1] "SED" Vector__XXX
 SG_ SeatLmbrHghtR2Drv_B_St : 35|1@0+ (1,0) [0|1] "SED" Vector__XXX
 SG_ SeatLmbrExtnR2Drv_B_St : 36|1@0+ (1,0) [0|1] "SED" Vector__XXX
 SG_ SeatBckInclnR2Drv_B_St : 37|1@0+ (1,0) [0|1] "SED" Vector__XXX
 SG_ SeatMovSrvcR2Drv_D_Arb : 39|2@0+ (1,0) [0|3] "SED" Vector__XXX

BO_ 645 ECG_Data5_HS3: 8 GWM
 SG_ VehImpactCode_No2_Actl : 7|16@0+ (1,0) [0|65535] "unitless"  APIM,APIM_CDC,APIM_CIM,APIM_CISM

BO_ 647 HEC_DispDimm: 8 IPC
 SG_ HEC_BTEndTelService_Rq : 3|2@0+ (1,0) [0|3] "SED"  APIM,APIM_CISM
 SG_ HEC_BTIncomingCall_Rq : 23|2@0+ (1,0) [0|3] "SED"  APIM,APIM_CISM

BO_ 648 APIM_Send_Signals_5: 8 APIM_CDC
 SG_ TrlrCamraHght_L_Actl : 7|8@0+ (25,0) [0|6375] "millimeter"  GWM
 SG_ TrlrWidth_L_Actl : 15|7@0+ (25,0) [0|3175] "millimeter"  GWM
 SG_ HitchToTrlrBox_L_Actl : 23|7@0+ (25,0) [0|3175] "millimeter"  GWM
 SG_ TrlrCamraCalib_D_Rq : 31|2@0+ (1,0) [0|3] "SED"  GWM

BO_ 649 APIM_Send_Signals_11: 8 APIM_CDC
 SG_ AirAmb_Te_ActlCld2 : 7|10@0+ (0.25,-128) [-128|127.75] "degC"  GWM
 SG_ InftnmntHlth_D_Stat : 13|4@0+ (1,0) [0|15] "SED"  GWM
 SG_ InftnmntHlth_No_Actl : 23|4@0+ (1,0) [0|15] "unitless"  GWM

BO_ 651 TCU_Send_Signals_HS3: 8 GWM
 SG_ CrnkInhbtSrvcHlth_B_St : 36|1@0+ (1,0) [0|1] "SED" Vector__XXX
 SG_ EmgcyCallMute_D_Stat : 39|3@0+ (1,0) [0|7] "SED"  ACM,APIM,APIM_CDC,APIM_CIM,APIM_CISM,DSP
 SG_ TelematicsSrvc_D_St : 47|3@0+ (1,0) [0|7] "SED"  ACM,APIM,APIM_CDC,APIM_CIM,APIM_CISM

BO_ 652 TCUB_Send_Signals_HS3: 8 GWM
 SG_ TelematicsSrvc_D_St2 : 7|3@0+ (1,0) [0|7] "SED"  APIM,APIM_CDC,APIM_CIM,APIM_CISM

BO_ 659 APIM_NFAM_Word_Tx: 8 APIM_CDC
 SG_ APIM_NFAM_Word_Tx : 7|64@0+ (1,0) [0|1.84467440737096E+019] "unitless"  GWM

BO_ 662 APIM_Send_Signals_6: 8 APIM_CDC
 SG_ Rear_Temp : 3|4@0+ (1,0) [0|15] "SED"  GWM
 SG_ Rear_Blower_Speed : 7|4@0+ (1,0) [0|15] "SED"  GWM
 SG_ Running_Board_Cmd2 : 10|2@0+ (1,0) [0|3] "SED"  GWM
 SG_ Rear_Set_Temp : 15|5@0+ (1,0) [0|31] "SED"  GWM
 SG_ ActvButtnLeft_D_Rq : 19|4@0+ (1,0) [0|15] "SED"  GWM
 SG_ Third_Rear_Blower_Speed : 23|4@0+ (1,0) [0|15] "SED"  GWM
 SG_ RgstrSetObl_D_Rq : 26|3@0+ (1,0) [0|7] "SED"  GWM
 SG_ Third_Rear_Set_Temp : 31|5@0+ (1,0) [0|31] "SED"  GWM
 SG_ ScOnb_B_Stat2 : 32|1@0+ (1,0) [0|1] "SED"  GWM
 SG_ RgstrSetIbl_D_Rq : 35|3@0+ (1,0) [0|7] "SED"  GWM
 SG_ ActvButtnRight_D_Rq : 39|4@0+ (1,0) [0|15] "SED"  GWM
 SG_ RgstrSetIbr_D_Rq : 44|3@0+ (1,0) [0|7] "SED"  GWM
 SG_ RgstrSetObr_D_Rq : 47|3@0+ (1,0) [0|7] "SED"  GWM

BO_ 663 PowerTransferData_HS3: 8 GWM
 SG_ Bpt_Pw_Allw : 7|16@0+ (0.1,0) [0|6553.5] "kilowatt"  APIM,APIM_CDC,APIM_CIM,APIM_CISM
 SG_ BptMnSoc_L_Actl : 23|13@0+ (0.1,0) [0|819.1] "kilometer"  APIM,APIM_CDC,APIM_CIM,APIM_CISM
 SG_ BptDchrg_T_Rmng : 26|15@0+ (1,0) [0|32767] "minute"  APIM,APIM_CDC,APIM_CIM,APIM_CISM
 SG_ Bpt_I_Est : 43|10@0+ (1,-510) [-510|513] "ampere"  APIM_CDC,APIM_CIM,APIM_CISM
 SG_ BptDchrg_Pw_Dsply : 49|10@0+ (0.1,0) [0|102.3] "kilowatt"  APIM,APIM_CDC,APIM_CIM,APIM_CISM

BO_ 667 APIM_NFAM_Word_Rx_HS3: 8 GWM
 SG_ APIM_NFAM_Word_Rx : 7|64@0+ (1,0) [0|1.84467440737096E+019] "unitless"  APIM,APIM_CDC,APIM_CIM,APIM_CISM

BO_ 668 PwrFoldSeatLeft_HS3: 8 GWM
 SG_ SeatFold3lButtn_D_Stat2 : 0|1@0+ (1,0) [0|1] "SED" Vector__XXX
 SG_ SeatFold3bButtn_D_Stat2 : 1|1@0+ (1,0) [0|1] "SED" Vector__XXX
 SG_ SeatBckMtnRr_D_Stat : 4|3@0+ (1,0) [0|7] "SED" Vector__XXX
 SG_ SeatBckMtn3r_D_Stat : 7|3@0+ (1,0) [0|7] "SED" Vector__XXX
 SG_ SeatBckPosRr_D_Stat : 11|4@0+ (1,0) [0|15] "SED" Vector__XXX
 SG_ SeatBckPos3r_D_Stat : 15|4@0+ (1,0) [0|15] "SED" Vector__XXX
 SG_ SeatFoldRrButtn_D_Stat2 : 16|1@0+ (1,0) [0|1] "SED" Vector__XXX
 SG_ SeatFoldRlButtn_D_Stat2 : 17|1@0+ (1,0) [0|1] "SED" Vector__XXX
 SG_ SeatFoldRbButtn_D_Stat2 : 18|1@0+ (1,0) [0|1] "SED" Vector__XXX
 SG_ SeatFold3rButtn_D_Stat2 : 19|1@0+ (1,0) [0|1] "SED" Vector__XXX
 SG_ SeatMtnRrMsgTxt_D_Rq : 23|4@0+ (1,0) [0|15] "SED"  APIM,APIM_CDC,APIM_CIM,APIM_CISM,IPC
 SG_ SeatSlidPosR2Psng_B_St : 24|1@0+ (1,0) [0|1] "SED" Vector__XXX
 SG_ SeatMovIdR2Psng_No_Act : 27|3@0+ (1,0) [0|7] "unitless" Vector__XXX
 SG_ SeatMovR2Psngr_D_Res : 31|4@0+ (1,0) [0|15] "SED" Vector__XXX
 SG_ SeatCalfRstR2Psng_B_St : 34|1@0+ (1,0) [0|1] "SED" Vector__XXX
 SG_ SeatLmbrHgtR2Psng_B_St : 35|1@0+ (1,0) [0|1] "SED" Vector__XXX
 SG_ SeatLmbrExtnR2Psn_B_St : 36|1@0+ (1,0) [0|1] "SED" Vector__XXX
 SG_ SeatBckInclR2Psng_B_St : 37|1@0+ (1,0) [0|1] "SED" Vector__XXX
 SG_ SeatMovSrvcR2Psn_D_Arb : 39|2@0+ (1,0) [0|3] "SED" Vector__XXX

BO_ 669 Pass_Dr_Stat2_HS3: 8 GWM
 SG_ DrHandleOuterRr_D_Stat : 4|3@0+ (1,0) [0|7] "SED"  APIM_CDC,APIM_CIM,IPC
 SG_ DrHandleOuterFr_D_Stat : 7|3@0+ (1,0) [0|7] "SED"  APIM_CDC,APIM_CIM,IPC

BO_ 670 Driver_Dr_Stat2_HS3: 8 GWM
 SG_ DrHandleOuterRl_D_Stat : 4|3@0+ (1,0) [0|7] "SED"  APIM_CDC,APIM_CIM,IPC
 SG_ DrHandleOuterFl_D_Stat : 7|3@0+ (1,0) [0|7] "SED"  APIM_CDC,APIM_CIM,IPC

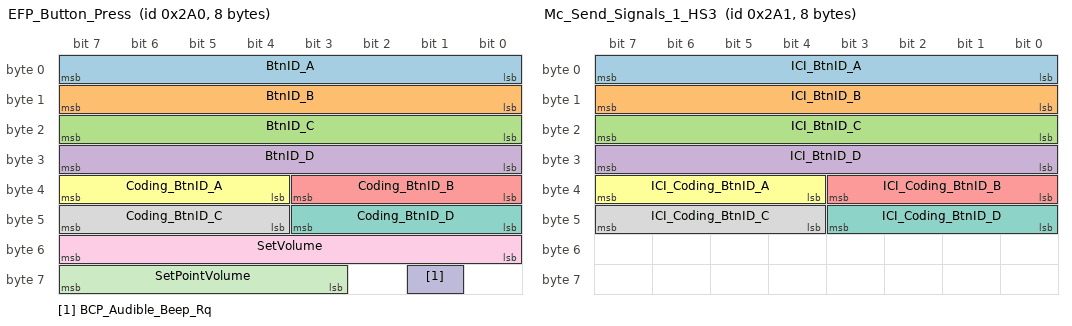
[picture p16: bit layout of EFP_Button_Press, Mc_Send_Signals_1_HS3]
BO_ 672 EFP_Button_Press: 8 GWM
 SG_ BtnID_A : 7|8@0+ (1,0) [0|255] "unitless"  ACM,APIM,APIM_CDC,APIM_CIM,APIM_CISM
 SG_ BtnID_B : 15|8@0+ (1,0) [0|255] "unitless"  ACM,APIM,APIM_CDC,APIM_CIM,APIM_CISM
 SG_ BtnID_C : 23|8@0+ (1,0) [0|255] "unitless"  ACM,APIM,APIM_CDC,APIM_CIM,APIM_CISM
 SG_ BtnID_D : 31|8@0+ (1,0) [0|255] "unitless"  ACM,APIM,APIM_CDC,APIM_CIM,APIM_CISM
 SG_ Coding_BtnID_B : 35|4@0+ (1,0) [0|15] "SED"  ACM,APIM,APIM_CDC,APIM_CIM,APIM_CISM
 SG_ Coding_BtnID_A : 39|4@0+ (1,0) [0|15] "SED"  ACM,APIM,APIM_CDC,APIM_CIM,APIM_CISM
 SG_ Coding_BtnID_D : 43|4@0+ (1,0) [0|15] "SED"  ACM,APIM,APIM_CDC,APIM_CIM,APIM_CISM
 SG_ Coding_BtnID_C : 47|4@0+ (1,0) [0|15] "SED"  ACM,APIM,APIM_CDC,APIM_CIM,APIM_CISM
 SG_ SetVolume : 55|8@0+ (1,-30) [-30|30] "unitless"  ACM,APIM,APIM_CDC,APIM_CIM,APIM_CISM,DSP,GWM
 SG_ BCP_Audible_Beep_Rq : 57|1@0+ (1,0) [0|1] "SED"  ACM,APIM_CDC,APIM_CIM,APIM_CISM,DSP
 SG_ SetPointVolume : 63|5@0+ (1,0) [0|31] "unitless"  ACM,APIM,APIM_CDC,APIM_CIM,APIM_CISM,DSP,GWM

BO_ 673 Mc_Send_Signals_1_HS3: 8 GWM
 SG_ ICI_BtnID_A : 7|8@0+ (1,0) [0|255] "unitless"  APIM,APIM_CDC,APIM_CIM,APIM_CISM,HUD_ADV,IPC
 SG_ ICI_BtnID_B : 15|8@0+ (1,0) [0|255] "unitless"  APIM,APIM_CDC,APIM_CIM,APIM_CISM,HUD_ADV,IPC
 SG_ ICI_BtnID_C : 23|8@0+ (1,0) [0|255] "unitless"  APIM,APIM_CDC,APIM_CIM,APIM_CISM,HUD_ADV,IPC
 SG_ ICI_BtnID_D : 31|8@0+ (1,0) [0|255] "unitless"  APIM,APIM_CDC,APIM_CIM,APIM_CISM,HUD_ADV,IPC
 SG_ ICI_Coding_BtnID_B : 35|4@0+ (1,0) [0|15] "SED"  APIM,APIM_CDC,APIM_CIM,APIM_CISM,HUD_ADV,IPC
 SG_ ICI_Coding_BtnID_A : 39|4@0+ (1,0) [0|15] "SED"  APIM,APIM_CDC,APIM_CIM,APIM_CISM,HUD_ADV,IPC
 SG_ ICI_Coding_BtnID_D : 43|4@0+ (1,0) [0|15] "SED"  APIM,APIM_CDC,APIM_CIM,APIM_CISM,HUD_ADV,IPC
 SG_ ICI_Coding_BtnID_C : 47|4@0+ (1,0) [0|15] "SED"  APIM,APIM_CDC,APIM_CIM,APIM_CISM,HUD_ADV,IPC

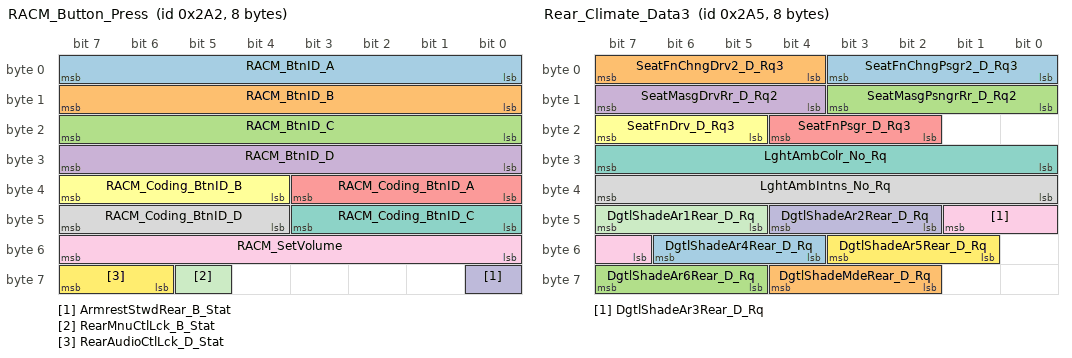
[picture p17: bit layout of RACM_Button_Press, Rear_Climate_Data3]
BO_ 674 RACM_Button_Press: 8 RACM_RCIM
 SG_ RACM_BtnID_A : 7|8@0+ (1,0) [0|255] "unitless"  APIM,APIM_CDC,APIM_CIM,APIM_CISM
 SG_ RACM_BtnID_B : 15|8@0+ (1,0) [0|255] "unitless"  APIM,APIM_CDC,APIM_CIM,APIM_CISM
 SG_ RACM_BtnID_C : 23|8@0+ (1,0) [0|255] "unitless"  APIM,APIM_CDC,APIM_CIM,APIM_CISM
 SG_ RACM_BtnID_D : 31|8@0+ (1,0) [0|255] "unitless"  APIM,APIM_CDC,APIM_CIM,APIM_CISM
 SG_ RACM_Coding_BtnID_A : 35|4@0+ (1,0) [0|15] "SED"  APIM,APIM_CDC,APIM_CIM,APIM_CISM
 SG_ RACM_Coding_BtnID_B : 39|4@0+ (1,0) [0|15] "SED"  APIM,APIM_CDC,APIM_CIM,APIM_CISM
 SG_ RACM_Coding_BtnID_C : 43|4@0+ (1,0) [0|15] "SED"  APIM,APIM_CDC,APIM_CIM,APIM_CISM
 SG_ RACM_Coding_BtnID_D : 47|4@0+ (1,0) [0|15] "SED"  APIM,APIM_CDC,APIM_CIM,APIM_CISM
 SG_ RACM_SetVolume : 55|8@0+ (1,-30) [-30|30] "unitless"  APIM,APIM_CDC,APIM_CIM,APIM_CISM
 SG_ ArmrestStwdRear_B_Stat : 56|1@0+ (1,0) [0|1] "SED"  GWM
 SG_ RearMnuCtlLck_B_Stat : 61|1@0+ (1,0) [0|1] "Unitless"  APIM_CDC,APIM_CIM
 SG_ RearAudioCtlLck_D_Stat : 63|2@0+ (1,0) [0|3] "SED"  APIM,APIM_CDC,APIM_CIM,APIM_CISM,FCIMB

BO_ 676 MC_RDISP_WORD_Tx: 8 IPC
 SG_ MC_RDISP_WORD_Tx : 7|64@0+ (1,0) [0|1.84467440737096E+019] "unitless"  APIM,APIM_CISM

BO_ 677 Rear_Climate_Data3: 8 RACM_RCIM
 SG_ SeatFnChngPsgr2_D_Rq3 : 3|4@0+ (1,0) [0|15] "SED"  GWM
 SG_ SeatFnChngDrv2_D_Rq3 : 7|4@0+ (1,0) [0|15] "SED"  GWM
 SG_ SeatMasgPsngrRr_D_Rq2 : 11|4@0+ (1,0) [0|15] "SED"  GWM
 SG_ SeatMasgDrvRr_D_Rq2 : 15|4@0+ (1,0) [0|15] "SED"  GWM
 SG_ SeatFnPsgr_D_Rq3 : 20|3@0+ (1,0) [0|7] "SED"  GWM
 SG_ SeatFnDrv_D_Rq3 : 23|3@0+ (1,0) [0|7] "SED"  GWM
 SG_ LghtAmbColr_No_Rq : 31|8@0+ (1,0) [0|255] "unitless"  GWM
 SG_ LghtAmbIntns_No_Rq : 39|8@0+ (1,0) [0|255] "unitless"  GWM
 SG_ DgtlShadeAr3Rear_D_Rq : 41|3@0+ (1,0) [0|7] "SED"  GWM
 SG_ DgtlShadeAr2Rear_D_Rq : 44|3@0+ (1,0) [0|7] "SED"  GWM
 SG_ DgtlShadeAr1Rear_D_Rq : 47|3@0+ (1,0) [0|7] "SED"  GWM
 SG_ DgtlShadeAr5Rear_D_Rq : 51|3@0+ (1,0) [0|7] "SED"  GWM
 SG_ DgtlShadeAr4Rear_D_Rq : 54|3@0+ (1,0) [0|7] "SED"  GWM
 SG_ DgtlShadeMdeRear_D_Rq : 60|3@0+ (1,0) [0|7] "SED"  GWM
 SG_ DgtlShadeAr6Rear_D_Rq : 63|3@0+ (1,0) [0|7] "SED"  GWM

BO_ 681 Con_Send_Signals_6: 8 ACM
 SG_ Con_DB1Filter1_St : 7|16@0+ (1,0) [0|65535] "unitless"  IPC
 SG_ Con_DB1Filter2_St : 23|16@0+ (1,0) [0|65535] "unitless"  IPC
 SG_ Con_DB1Filter3_St : 33|10@0+ (1,0) [0|1023] "unitless"  IPC
 SG_ Con_DB1FilterConfig_St : 38|5@0+ (1,0) [0|31] "SED"  IPC
 SG_ Con_DB1temIndex_St : 55|16@0+ (1,0) [0|65535] "unitless"  IPC

BO_ 684 MC_RDISP_WORD_Rx: 8 APIM
 SG_ MC_RDISP_WORD_Rx : 7|64@0+ (1,0) [0|1.84467440737096E+019] "unitless"  IPC

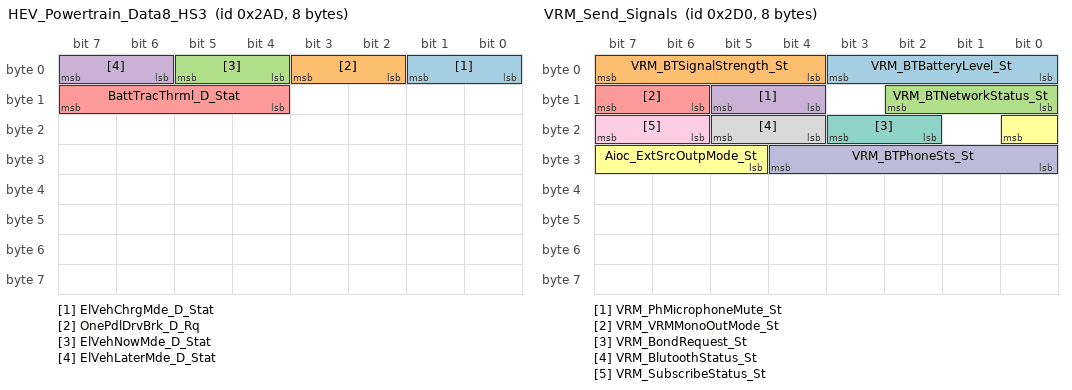
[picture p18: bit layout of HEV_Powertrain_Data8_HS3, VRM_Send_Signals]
BO_ 685 HEV_Powertrain_Data8_HS3: 8 GWM
 SG_ ElVehChrgMde_D_Stat : 1|2@0+ (1,0) [0|3] "SED"  APIM,APIM_CDC
 SG_ OnePdlDrvBrk_D_Rq : 3|2@0+ (1,0) [0|3] "SED" Vector__XXX
 SG_ ElVehNowMde_D_Stat : 5|2@0+ (1,0) [0|3] "SED"  APIM,APIM_CDC
 SG_ ElVehLaterMde_D_Stat : 7|2@0+ (1,0) [0|3] "SED"  APIM,APIM_CDC
 SG_ BattTracThrml_D_Stat : 15|4@0+ (1,0) [0|15] "SED" Vector__XXX

BO_ 688 APIM_TCUB_Word_Rx_HS3: 8 GWM
 SG_ APIM_TCUB_Word_Rx : 7|64@0+ (1,0) [0|1.84467440737096E+019] "unitless"  APIM,APIM_CDC,APIM_CIM,APIM_CISM

BO_ 689 AUDIO_MC_WORD_Tx: 8 ACM
 SG_ AUDIO_MC_WORD_Tx : 7|64@0+ (1,0) [0|1.84467440737096E+019] "unitless"  APIM_CDC,IPC

BO_ 692 AUDIO_RDISP_WORD_Tx: 8 ACM
 SG_ AUDIO_RDISP_WORD_Tx : 7|64@0+ (1,0) [0|1.84467440737096E+019] "unitless"  APIM,APIM_CDC

BO_ 694 PHONE_MC_WORD_Tx: 8 APIM_CISM
 SG_ PHONE_MC_WORD_Tx : 7|64@0+ (1,0) [0|1.84467440737096E+019] "unitless"  IPC

BO_ 695 CONMP_MC_WORD_Tx: 8 APIM
 SG_ CONMP_MC_WORD_Tx : 7|64@0+ (1,0) [0|1.84467440737096E+019] "unitless"  IPC

BO_ 696 APIM_TCUB_Word_Tx: 8 APIM_CDC
 SG_ APIM_TCUB_Word_Tx : 7|64@0+ (1,0) [0|1.84467440737096E+019] "unitless"  GWM

BO_ 697 AUDIO_MC_WORD_Rx: 8 APIM_CDC
 SG_ AUDIO_MC_WORD_Rx : 7|64@0+ (1,0) [0|1.84467440737096E+019] "unitless"  ACM,APIM_CISM

BO_ 700 AUDIO_RDISP_WORD_Rx: 8 APIM_CDC
 SG_ AUDIO_RDISP_WORD_Rx : 7|64@0+ (1,0) [0|1.84467440737096E+019] "unitless"  ACM

BO_ 702 PHONE_MC_WORD_Rx: 8 IPC
 SG_ PHONE_MC_WORD_Rx : 7|64@0+ (1,0) [0|1.84467440737096E+019] "unitless"  APIM,APIM_CISM

BO_ 703 CONMP_MC_WORD_Rx: 8 APIM_CDC
 SG_ CONMP_MC_WORD_Rx : 7|64@0+ (1,0) [0|1.84467440737096E+019] "unitless"  APIM,APIM_CISM

BO_ 704 NAV_MC_WORD_Tx: 8 APIM_CISM
 SG_ NAV_MC_WORD_Tx : 7|64@0+ (1,0) [0|1.84467440737096E+019] "unitless"  IPC

BO_ 705 SDARS_RDISP_WORD_Tx: 8 ACM
 SG_ SDARS_RDISP_WORD_Tx : 7|64@0+ (1,0) [0|1.84467440737096E+019] "unitless"  APIM,APIM_CDC

BO_ 706 SDARS_MC_WORD_Tx: 8 ACM
 SG_ SDARS_MC_WORD_Tx : 7|64@0+ (1,0) [0|1.84467440737096E+019] "unitless"  APIM_CDC,IPC

BO_ 707 SSPClnt_SSPSrv_WORD_Tx: 8 ACM
 SG_ SSPClnt_SSPSrv_WORD_Tx : 7|64@0+ (1,0) [0|1.84467440737096E+019] "unitless"  APIM,APIM_CDC

BO_ 708 TMCSrvr_TMCClnt_WORD_Tx: 8 ACM
 SG_ TMCSrvr_TMCClnt_WORD_Tx : 7|64@0+ (1,0) [0|1.84467440737096E+019] "unitless"  APIM,APIM_CDC

BO_ 709 DSPAMP_RDISP_WORD_Tx: 8 DSP
 SG_ DSPAMP_RDISP_WORD_Tx : 7|64@0+ (1,0) [0|1.84467440737096E+019] "unitless"  APIM,APIM_CDC,APIM_CIM,APIM_CISM

BO_ 710 BEZEL_RDISP_WORD_Tx_HS3: 8 GWM
 SG_ BEZEL_RDISP_WORD_Tx : 7|64@0+ (1,0) [0|1.84467440737096E+019] "unitless"  APIM,APIM_CDC,APIM_CIM,APIM_CISM

BO_ 711 MyKeySrvr_MyKeyClient_Word: 8 IPC
 SG_ MyKeySrvr_MyKeyClient_Word : 7|64@0+ (1,0) [0|1.84467440737096E+019] "unitless"  APIM,APIM_CISM

BO_ 712 NAV_MC_WORD_Rx: 8 IPC
 SG_ NAV_MC_WORD_Rx : 7|64@0+ (1,0) [0|1.84467440737096E+019] "unitless"  APIM,APIM_CISM

BO_ 713 SDARS_RDISP_WORD_Rx: 8 APIM_CDC
 SG_ SDARS_RDISP_WORD_Rx : 7|64@0+ (1,0) [0|1.84467440737096E+019] "unitless"  ACM

BO_ 714 SDARS_MC_WORD_Rx: 8 APIM_CDC
 SG_ SDARS_MC_WORD_Rx : 7|64@0+ (1,0) [0|1.84467440737096E+019] "unitless"  ACM,APIM_CISM

BO_ 715 SSPClnt_SSPSrv_WORD_Rx: 8 APIM_CDC
 SG_ SSPClnt_SSPSrv_WORD_Rx : 7|64@0+ (1,0) [0|1.84467440737096E+019] "unitless"  ACM

BO_ 716 TMCSrvr_TMCClient_WORD_Rx: 8 APIM_CDC
 SG_ TMCSrvr_TMCClient_WORD_Rx : 7|64@0+ (1,0) [0|1.84467440737096E+019] "unitless"  ACM

BO_ 717 DSPAMP_RDISP_WORD_Rx: 8 APIM_CDC
 SG_ DSPAMP_RDISP_WORD_Rx : 7|64@0+ (1,0) [0|1.84467440737096E+019] "unitless"  DSP

BO_ 718 BEZEL_RDISP_WORD_Rx: 8 APIM_CDC
 SG_ BEZEL_RDISP_WORD_Rx : 7|64@0+ (1,0) [0|1.84467440737096E+019] "unitless"  GWM

BO_ 719 MyKeySrvr_Clnt_Word_Rx: 8 APIM_CISM
 SG_ MyKeySrvr_Clnt_Word_Rx : 7|64@0+ (1,0) [0|1.84467440737096E+019] "unitless"  IPC

BO_ 720 VRM_Send_Signals: 8 APIM_CDC
 SG_ VRM_BTBatteryLevel_St : 3|4@0+ (1,0) [0|15] "unitless"  IPC
 SG_ VRM_BTSignalStrength_St : 7|4@0+ (1,0) [0|15] "unitless"  IPC
 SG_ VRM_BTNetworkStatus_St : 10|3@0+ (1,0) [0|7] "unitless"  IPC
 SG_ VRM_PhMicrophoneMute_St : 13|2@0+ (1,0) [0|3] "SED"  IPC
 SG_ VRM_VRMMonoOutMode_St : 15|2@0+ (1,0) [0|3] "SED"  GENERIC
 SG_ Aioc_ExtSrcOutpMode_St : 16|4@0+ (1,0) [0|15] "SED"  GENERIC
 SG_ VRM_BondRequest_St : 19|2@0+ (1,0) [0|3] "SED"  GENERIC
 SG_ VRM_BlutoothStatus_St : 21|2@0+ (1,0) [0|3] "SED"  IPC
 SG_ VRM_SubscribeStatus_St : 23|2@0+ (1,0) [0|3] "SED"  GENERIC
 SG_ VRM_BTPhoneSts_St : 28|5@0+ (1,0) [0|31] "SED"  GWM,HUD_ADV,IPC,RACM_RCIM

BO_ 721 VRM_Send_Signals_1: 8 APIM_CISM
 SG_ VRM_ComTrafficInfDsp_St : 1|2@0+ (1,0) [0|3] "SED"  GENERIC
 SG_ VRM_ComGuidance_St : 4|3@0+ (1,0) [0|7] "SED"  GENERIC
 SG_ VRM_ComCallControl_St : 7|3@0+ (1,0) [0|7] "SED"  GENERIC
 SG_ VRM_ComZoom_St : 12|5@0+ (1,0) [0|31] "SED"  GENERIC
 SG_ VRM_ComDynamicGuidande_St : 15|2@0+ (1,0) [0|3] "SED"  GENERIC
 SG_ VRM_ComDisplay_St : 19|3@0+ (1,0) [0|7] "SED"  GENERIC
 SG_ VRM_ComDetour_St : 23|4@0+ (1,0) [0|15] "SED"  GENERIC
 SG_ VRM_ComSelTrackSource_St : 25|2@0+ (1,0) [0|3] "SED"  GENERIC
 SG_ VRM_VoiceRecStatus_St : 28|3@0+ (1,0) [0|7] "SED"  IPC
 SG_ VRM_ComShowNavInfo_St : 31|3@0+ (1,0) [0|7] "SED"  GENERIC
 SG_ VRM_ComSelectTrack_St : 39|7@0+ (1,0) [0|100] "unitless"  GENERIC
 SG_ VRM_ComDestHome_St : 41|2@0+ (1,0) [0|3] "SED"  GENERIC
 SG_ VRM_ComTelService_St : 44|3@0+ (1,0) [0|7] "SED"  GENERIC
 SG_ VRM_ComSelectDisc_St : 47|3@0+ (1,0) [0|7] "SED"  GENERIC
 SG_ VRM_ComDelWaypoint_St : 49|2@0+ (1,0) [0|3] "SED"  GENERIC
 SG_ VRM_SuggestedRoute_St : 51|2@0+ (1,0) [0|3] "SED"  GENERIC
 SG_ VRM_ComBTDTMFTone_St : 55|4@0+ (1,0) [0|15] "SED"  GENERIC
 SG_ VRM_Zoom_Option_St : 57|2@0+ (1,0) [0|3] "SED"  GENERIC
 SG_ VRM_DetourUnit_st : 59|2@0+ (1,0) [0|3] "SED"  GENERIC
 SG_ VRM_BTDefaultPhone_St : 63|4@0+ (1,0) [0|15] "SED"  IPC

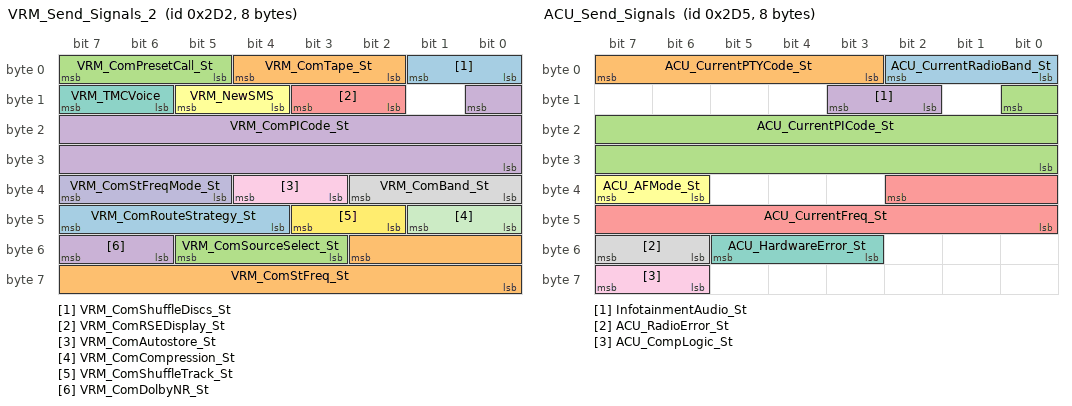
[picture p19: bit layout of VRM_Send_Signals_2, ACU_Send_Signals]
BO_ 722 VRM_Send_Signals_2: 8 APIM_CDC
 SG_ VRM_ComShuffleDiscs_St : 1|2@0+ (1,0) [0|3] "SED"  GENERIC
 SG_ VRM_ComTape_St : 4|3@0+ (1,0) [0|7] "SED"  GENERIC
 SG_ VRM_ComPresetCall_St : 7|3@0+ (1,0) [0|7] "SED"  GENERIC
 SG_ VRM_ComPICode_St : 8|17@0+ (1,0) [0|65535] "unitless"  GENERIC
 SG_ VRM_ComRSEDisplay_St : 11|2@0+ (1,0) [0|3] "SED"  GENERIC
 SG_ VRM_NewSMS : 13|2@0+ (1,0) [0|3] "SED"  HUD_ADV,IPC
 SG_ VRM_TMCVoice : 15|2@0+ (1,0) [0|3] "SED"  GENERIC
 SG_ VRM_ComBand_St : 34|3@0+ (1,0) [0|7] "SED"  GENERIC
 SG_ VRM_ComAutostore_St : 36|2@0+ (1,0) [0|3] "SED"  GENERIC
 SG_ VRM_ComStFreqMode_St : 39|3@0+ (1,0) [0|7] "SED"  GENERIC
 SG_ VRM_ComCompression_St : 41|2@0+ (1,0) [0|3] "SED"  GENERIC
 SG_ VRM_ComShuffleTrack_St : 43|2@0+ (1,0) [0|3] "SED"  GENERIC
 SG_ VRM_ComRouteStrategy_St : 47|4@0+ (1,0) [0|15] "SED"  GENERIC
 SG_ VRM_ComStFreq_St : 50|11@0+ (1,0) [0|1557] "unitless"  GENERIC
 SG_ VRM_ComSourceSelect_St : 53|3@0+ (1,0) [0|7] "SED"  GENERIC
 SG_ VRM_ComDolbyNR_St : 55|2@0+ (1,0) [0|3] "SED"  GENERIC

BO_ 725 ACU_Send_Signals: 8 APIM_CIM
 SG_ ACU_CurrentRadioBand_St : 2|3@0+ (1,0) [0|7] "SED"  APIM_CDC,GWM,IPC
 SG_ ACU_CurrentPTYCode_St : 7|5@0+ (1,0) [0|31] "unitless"  APIM,APIM_CDC,GWM,IPC,RACM_RCIM
 SG_ ACU_CurrentPICode_St : 8|17@0+ (1,0) [0|65535] "unitless"  APIM,APIM_CDC,GWM,RACM_RCIM
 SG_ InfotainmentAudio_St : 11|2@0+ (1,0) [0|3] "SED"  APIM,APIM_CDC,DSP
 SG_ ACU_CurrentFreq_St : 34|11@0+ (1,0) [0|1557] "unitless"  APIM,APIM_CDC,DSP,GWM,IPC,RACM_RCIM,WCM,WCMB,WCMC
 SG_ ACU_AFMode_St : 39|2@0+ (1,0) [0|3] "SED"  APIM,APIM_CDC,GWM
 SG_ ACU_HardwareError_St : 53|3@0+ (1,0) [0|7] "SED"  APIM,APIM_CDC,GWM,IPC,RACM_RCIM
 SG_ ACU_RadioError_St : 55|2@0+ (1,0) [0|3] "SED"  APIM,APIM_CDC,GWM,IPC,RACM_RCIM
 SG_ ACU_CompLogic_St : 63|2@0+ (1,0) [0|3] "SED"  GENERIC,GWM

BO_TX_BU_ 533 : APIM,APIM_CDC,APIM_CIM,APIM_CISM;
BO_TX_BU_ 543 : APIM_CDC,APIM_CIM,APIM_CISM,IPC;
BO_TX_BU_ 544 : APIM_CDC,APIM_CIM,APIM_CISM,IPC;
BO_TX_BU_ 546 : APIM,APIM_CDC,APIM_CIM,APIM_CISM;
BO_TX_BU_ 547 : ACM,APIM_CIM,APIM_CISM;
BO_TX_BU_ 549 : APIM_CDC,APIM_CIM,APIM_CISM,IPC;
BO_TX_BU_ 551 : APIM,APIM_CDC,APIM_CIM,APIM_CISM;
BO_TX_BU_ 553 : APIM,APIM_CDC,APIM_CIM,APIM_CISM;
BO_TX_BU_ 556 : FCIMB,GWM;
BO_TX_BU_ 558 : APIM,APIM_CIM,APIM_CISM,GWM;
BO_TX_BU_ 559 : APIM,APIM_CIM,APIM_CISM,GWM;
BO_TX_BU_ 576 : ACM,APIM_CDC,APIM_CIM,APIM_CISM;
BO_TX_BU_ 577 : APIM,APIM_CDC,APIM_CIM,APIM_CISM;
BO_TX_BU_ 578 : APIM,APIM_CDC,APIM_CIM,APIM_CISM;
BO_TX_BU_ 579 : ACM,APIM,APIM_CDC,APIM_CIM,APIM_CISM;
BO_TX_BU_ 589 : APIM,APIM_CDC,APIM_CIM,APIM_CISM;
BO_TX_BU_ 595 : APIM,APIM_CDC,APIM_CIM,APIM_CISM;
BO_TX_BU_ 597 : ACM,APIM_CIM,APIM_CISM;
BO_TX_BU_ 598 : APIM,APIM_CDC,APIM_CIM,APIM_CISM;
BO_TX_BU_ 600 : APIM,APIM_CDC,APIM_CIM,APIM_CISM;
BO_TX_BU_ 601 : APIM_CDC,IPC;
BO_TX_BU_ 627 : APIM,APIM_CDC,APIM_CIM,APIM_CISM;
BO_TX_BU_ 630 : APIM,APIM_CDC,APIM_CIM,APIM_CISM;
BO_TX_BU_ 648 : APIM,APIM_CDC;
BO_TX_BU_ 649 : APIM,APIM_CDC;
BO_TX_BU_ 659 : APIM,APIM_CDC,APIM_CIM,APIM_CISM;
BO_TX_BU_ 662 : APIM,APIM_CDC,APIM_CIM,APIM_CISM;
BO_TX_BU_ 672 : FCIMB,GWM;
BO_TX_BU_ 684 : APIM,APIM_CISM;
BO_TX_BU_ 689 : ACM,APIM_CISM;
BO_TX_BU_ 694 : APIM,APIM_CISM;
BO_TX_BU_ 695 : APIM,APIM_CISM;
BO_TX_BU_ 696 : APIM,APIM_CDC,APIM_CIM,APIM_CISM;
BO_TX_BU_ 697 : APIM_CDC,IPC;
BO_TX_BU_ 700 : APIM,APIM_CDC;
BO_TX_BU_ 703 : APIM_CDC,IPC;
BO_TX_BU_ 704 : APIM,APIM_CISM;
BO_TX_BU_ 706 : ACM,APIM_CISM;
BO_TX_BU_ 713 : APIM,APIM_CDC;
BO_TX_BU_ 714 : APIM_CDC,IPC;
BO_TX_BU_ 715 : APIM,APIM_CDC;
BO_TX_BU_ 716 : APIM,APIM_CDC;
BO_TX_BU_ 717 : APIM,APIM_CDC,APIM_CIM,APIM_CISM;
BO_TX_BU_ 718 : APIM,APIM_CDC,APIM_CIM,APIM_CISM;
BO_TX_BU_ 719 : APIM,APIM_CISM;
BO_TX_BU_ 720 : APIM,APIM_CDC,APIM_CIM,APIM_CISM;
BO_TX_BU_ 721 : APIM,APIM_CISM;
BO_TX_BU_ 722 : APIM,APIM_CDC,APIM_CISM;
BO_TX_BU_ 725 : ACM,APIM_CIM,APIM_CISM;
CM_ BO_ 531 "IC is NOT to use data in this message for displays, Used data from 415 instead.";
CM_ BO_ 544 "Method IPC_Chime";
CM_ BO_ 549 "Method IPC _Infotainment";
CM_ BO_ 553 "FCDIM, APIM Tx";
CM_ BO_ 554 "TCU_CPPM Tx";
CM_ BO_ 558 "APIM Tx";
CM_ BO_ 559 "APIM Tx";
CM_ BO_ 560 "MHT (U611/625) the HPCM will Rx 0x230 from the PCM_HEV
Powersplit FWD HEV?s (Cx482/3 430) the HPCM will Tx 0x230";
CM_ BO_ 581 "TP message";
CM_ BO_ 600 "Tx by HS3 APIM";
CM_ BO_ 611 "Used on Applications with 4x4 supplied by Motorola.";
CM_ BO_ 651 "TCU CPPM Tx";
CM_ BO_ 673 "Do not use this Frame for other Cluster Interaction";
CM_ BO_ 688 "TP message";
CM_ BO_ 710 "TP message(Transport Protocol), Rx's HS3 APIM & MFD, transmitted immediately";
BA_DEF_ BO_  "E2EDataId" INT 0 65535;
BA_DEF_ BO_  "E2EDataLength" INT 0 512;
BA_DEF_ BO_  "E2EProfile" STRING ;
BA_DEF_ BO_  "GenMsgRoutingTimeoutTime" INT 0 5000;
BA_DEF_ BO_  "MessageGateway" ENUM  "No","Yes";
BA_DEF_ BO_  "VFrameFormat" ENUM  "StandardCAN","ExtendedCAN","reserved","reserved","reserved","reserved","reserved","reserved","reserved","reserved","reserved","reserved","reserved","reserved","StandardCAN_FD","ExtendedCAN_FD";
BA_DEF_ SG_  "ECGUsedRxSignal" ENUM  "No","Yes";
BA_DEF_ SG_  "ECGUsedTxSignal" ENUM  "No","Yes";
BA_DEF_ SG_  "GenSigInactiveValue" INT 0 100000;
BA_DEF_ SG_  "GenSigSendType" ENUM  "Cyclic","OnWrite","vector_leerstring","OnChange","vector_leerstring","IfActive","vector_leerstring","NoSigSendType";
BA_DEF_ BO_  "NetworkInitialization" ENUM  "No","Yes";
BA_DEF_ SG_  "GenSigStartValue" HEX 0 268435455;
BA_DEF_ BO_  "GenMsgStartDelayTime" INT 0 10000;
BA_DEF_ SG_  "WakeupSignal" ENUM  "No","Yes";
BA_DEF_ BO_  "GenMsgNrOfRepetition" INT 0 100;
BA_DEF_ BO_  "GenMsgDelayTime" INT 0 1000;
BA_DEF_ BO_  "GenMsgCycleTime" INT 0 100000;
BA_DEF_ BO_  "GenMsgSendType" ENUM  "FixedPeriodic","Event","EnabledPeriodic","NotUsed","NotUsed","EventPeriodic","NotUsed","NotUsed","NoMsgSendType";
BA_DEF_ BO_  "FrameRouting" STRING ;
BA_DEF_ BO_  "TpTxIndex" INT 0 536870911;
BA_DEF_ BO_  "OvtpPushApplication" ENUM  "FALSE","TRUE";
BA_DEF_ BO_  "SCP_FreshnessValueLength" INT 0 512;
BA_DEF_ BO_  "SCP_FreshnessValueTxLength" INT 0 512;
BA_DEF_ BO_  "SCP_AuthInfoTxLength" INT 0 512;
BA_DEF_ BO_  "NmAsrMessage" ENUM  "No","Yes";
BA_DEF_ BO_  "DiagState" ENUM  "No","Yes";
BA_DEF_ BO_  "DiagRequest" ENUM  "No","Yes";
BA_DEF_ BO_  "DiagResponse" ENUM  "No","Yes";
BA_DEF_ BO_  "GenMsgILSupport" ENUM  "No","Yes";
BA_DEF_ SG_  "SystemSignalLongSymbol" STRING ;
BA_DEF_ BO_  "SystemMessageLongSymbol" STRING ;
BA_DEF_DEF_  "E2EDataId" 1;
BA_DEF_DEF_  "E2EDataLength" 0;
BA_DEF_DEF_  "E2EProfile" "";
BA_DEF_DEF_  "GenMsgRoutingTimeoutTime" 0;
BA_DEF_DEF_  "MessageGateway" "No";
BA_DEF_DEF_  "VFrameFormat" "StandardCAN";
BA_DEF_DEF_  "ECGUsedRxSignal" "No";
BA_DEF_DEF_  "ECGUsedTxSignal" "No";
BA_DEF_DEF_  "GenSigInactiveValue" 0;
BA_DEF_DEF_  "GenSigSendType" "NoSigSendType";
BA_DEF_DEF_  "NetworkInitialization" "Yes";
BA_DEF_DEF_  "GenSigStartValue" 0;
BA_DEF_DEF_  "GenMsgStartDelayTime" 0;
BA_DEF_DEF_  "WakeupSignal" "No";
BA_DEF_DEF_  "GenMsgNrOfRepetition" 1;
BA_DEF_DEF_  "GenMsgDelayTime" 20;
BA_DEF_DEF_  "GenMsgCycleTime" 0;
BA_DEF_DEF_  "GenMsgSendType" "NoMsgSendType";
BA_DEF_DEF_  "FrameRouting" "";
BA_DEF_DEF_  "TpTxIndex" 0;
BA_DEF_DEF_  "OvtpPushApplication" "FALSE";
BA_DEF_DEF_  "SCP_FreshnessValueLength" 64;
BA_DEF_DEF_  "SCP_FreshnessValueTxLength" 11;
BA_DEF_DEF_  "SCP_AuthInfoTxLength" 53;
BA_DEF_DEF_  "NmAsrMessage" "No";
BA_DEF_DEF_  "DiagState" "No";
BA_DEF_DEF_  "DiagRequest" "No";
BA_DEF_DEF_  "DiagResponse" "No";
BA_DEF_DEF_  "GenMsgILSupport" "Yes";
BA_DEF_DEF_  "SystemSignalLongSymbol" "";
BA_DEF_DEF_  "SystemMessageLongSymbol" "";
BA_ "FrameRouting" BO_ 531 "FD1_CAN,0x213;";
BA_ "GenMsgSendType" BO_ 533 5;
BA_ "GenMsgCycleTime" BO_ 533 1000;
BA_ "FrameRouting" BO_ 534 "FD1_CAN,0x216;";
BA_ "FrameRouting" BO_ 535 "FD1_CAN,0x217;";
BA_ "GenMsgSendType" BO_ 538 5;
BA_ "GenMsgCycleTime" BO_ 538 1000;
BA_ "FrameRouting" BO_ 539 "FD2_CAN,0x21B;";
BA_ "FrameRouting" BO_ 540 "FD2_CAN,0x21C;";
BA_ "FrameRouting" BO_ 542 "FD2_CAN,0x21E;";
BA_ "GenMsgSendType" BO_ 543 0;
BA_ "GenMsgCycleTime" BO_ 543 1000;
BA_ "GenMsgSendType" BO_ 544 5;
BA_ "GenMsgCycleTime" BO_ 544 1000;
BA_ "GenMsgSendType" BO_ 545 5;
BA_ "GenMsgCycleTime" BO_ 545 1000;
BA_ "GenMsgSendType" BO_ 546 5;
BA_ "GenMsgCycleTime" BO_ 546 1000;
BA_ "GenMsgSendType" BO_ 547 5;
BA_ "GenMsgCycleTime" BO_ 547 1000;
BA_ "GenMsgSendType" BO_ 548 5;
BA_ "GenMsgCycleTime" BO_ 548 1000;
BA_ "GenMsgSendType" BO_ 549 5;
BA_ "GenMsgCycleTime" BO_ 549 1000;
BA_ "GenMsgSendType" BO_ 551 5;
BA_ "GenMsgCycleTime" BO_ 551 1000;
BA_ "GenMsgSendType" BO_ 552 5;
BA_ "GenMsgCycleTime" BO_ 552 1000;
BA_ "GenMsgSendType" BO_ 553 5;
BA_ "GenMsgCycleTime" BO_ 553 1000;
BA_ "GenMsgSendType" BO_ 554 5;
BA_ "GenMsgCycleTime" BO_ 554 1000;
BA_ "GenMsgSendType" BO_ 555 5;
BA_ "GenMsgCycleTime" BO_ 555 1000;
BA_ "GenMsgSendType" BO_ 556 5;
BA_ "GenMsgCycleTime" BO_ 556 1000;
BA_ "FrameRouting" BO_ 556 "MS1_CAN,0x22C;";
BA_ "GenMsgSendType" BO_ 557 5;
BA_ "GenMsgCycleTime" BO_ 557 1000;
BA_ "GenMsgSendType" BO_ 558 1;
BA_ "GenMsgSendType" BO_ 559 1;
BA_ "FrameRouting" BO_ 560 "FD1_CAN,0x230;";
BA_ "FrameRouting" BO_ 561 "FD1_CAN,0x231;";
BA_ "GenMsgSendType" BO_ 563 5;
BA_ "GenMsgCycleTime" BO_ 563 1000;
BA_ "FrameRouting" BO_ 571 "FD1_CAN,0x23B;";
BA_ "FrameRouting" BO_ 572 "HS2_CAN,0x24B;";
BA_ "FrameRouting" BO_ 573 "FD1_CAN,0x23D;";
BA_ "TpTxIndex" BO_ 576 41;
BA_ "TpTxIndex" BO_ 577 42;
BA_ "TpTxIndex" BO_ 578 43;
BA_ "TpTxIndex" BO_ 579 44;
BA_ "TpTxIndex" BO_ 581 30;
BA_ "FrameRouting" BO_ 581 "FD2_CAN,0x245;";
BA_ "FrameRouting" BO_ 582 "FD1_CAN,0x242;";
BA_ "TpTxIndex" BO_ 584 41;
BA_ "TpTxIndex" BO_ 585 42;
BA_ "TpTxIndex" BO_ 586 43;
BA_ "TpTxIndex" BO_ 587 44;
BA_ "TpTxIndex" BO_ 588 45;
BA_ "TpTxIndex" BO_ 589 30;
BA_ "FrameRouting" BO_ 591 "HS2_CAN,0x24F;";
BA_ "TpTxIndex" BO_ 592 50;
BA_ "FrameRouting" BO_ 592 "FD2_CAN,0x250;";
BA_ "TpTxIndex" BO_ 593 58;
BA_ "FrameRouting" BO_ 594 "HS2_CAN,0x24C;";
BA_ "GenMsgSendType" BO_ 595 5;
BA_ "GenMsgCycleTime" BO_ 595 500;
BA_ "FrameRouting" BO_ 596 "FD3_CAN,0x254;";
BA_ "TpTxIndex" BO_ 597 46;
BA_ "TpTxIndex" BO_ 598 47;
BA_ "TpTxIndex" BO_ 600 50;
BA_ "TpTxIndex" BO_ 601 58;
BA_ "NetworkInitialization" BO_ 601 0;
BA_ "FrameRouting" BO_ 602 "FD1_CAN,0x25A;";
BA_ "TpTxIndex" BO_ 605 46;
BA_ "TpTxIndex" BO_ 606 47;
BA_ "TpTxIndex" BO_ 607 48;
BA_ "FrameRouting" BO_ 608 "HS2_CAN,0x25F;";
BA_ "FrameRouting" BO_ 610 "FD1_CAN,0x262;";
BA_ "FrameRouting" BO_ 611 "FD1_CAN,0x263;";
BA_ "FrameRouting" BO_ 613 "HS2_CAN,0x265;";
BA_ "FrameRouting" BO_ 618 "FD2_CAN,0x26A;";
BA_ "FrameRouting" BO_ 619 "FD2_CAN,0x26B;";
BA_ "FrameRouting" BO_ 621 "FD2_CAN,0x26D;";
BA_ "GenMsgSendType" BO_ 627 0;
BA_ "GenMsgCycleTime" BO_ 627 100;
BA_ "GenMsgSendType" BO_ 630 0;
BA_ "GenMsgCycleTime" BO_ 630 100;
BA_ "FrameRouting" BO_ 636 "FD2_CAN,0x27C;";
BA_ "FrameRouting" BO_ 638 "FD2_CAN,0x27E;";
BA_ "GenMsgSendType" BO_ 639 5;
BA_ "GenMsgCycleTime" BO_ 639 1000;
BA_ "FrameRouting" BO_ 640 "FD3_CAN,0x280;";
BA_ "GenMsgSendType" BO_ 645 0;
BA_ "GenMsgCycleTime" BO_ 645 100;
BA_ "GenMsgSendType" BO_ 647 5;
BA_ "GenMsgCycleTime" BO_ 647 200;
BA_ "GenMsgSendType" BO_ 648 5;
BA_ "GenMsgCycleTime" BO_ 648 1000;
BA_ "GenMsgSendType" BO_ 649 0;
BA_ "GenMsgCycleTime" BO_ 649 100;
BA_ "FrameRouting" BO_ 651 "FD2_CAN,0x28B;";
BA_ "FrameRouting" BO_ 652 "FD2_CAN,0x28C;";
BA_ "TpTxIndex" BO_ 659 125;
BA_ "GenMsgSendType" BO_ 662 5;
BA_ "GenMsgCycleTime" BO_ 662 1000;
BA_ "FrameRouting" BO_ 663 "FD1_CAN,0x297;";
BA_ "TpTxIndex" BO_ 667 125;
BA_ "FrameRouting" BO_ 667 "FD2_CAN,0x29B;";
BA_ "FrameRouting" BO_ 668 "FD3_CAN,0x29C;";
BA_ "FrameRouting" BO_ 669 "FD3_CAN,0x29D;";
BA_ "FrameRouting" BO_ 670 "FD3_CAN,0x29E;";
BA_ "GenMsgStartDelayTime" BO_ 672 150;
BA_ "GenMsgSendType" BO_ 672 5;
BA_ "GenMsgCycleTime" BO_ 672 1000;
BA_ "FrameRouting" BO_ 672 "MS1_CAN,0x2A0;";
BA_ "FrameRouting" BO_ 673 "FD3_CAN,0x2A1;HS2_CAN,0x2A1;HS2_CAN,0x2A1;";
BA_ "GenMsgStartDelayTime" BO_ 674 150;
BA_ "GenMsgSendType" BO_ 674 5;
BA_ "GenMsgDelayTime" BO_ 674 10;
BA_ "GenMsgCycleTime" BO_ 674 1000;
BA_ "TpTxIndex" BO_ 676 29;
BA_ "NetworkInitialization" BO_ 676 0;
BA_ "GenMsgSendType" BO_ 677 5;
BA_ "GenMsgCycleTime" BO_ 677 1000;
BA_ "GenMsgSendType" BO_ 681 5;
BA_ "GenMsgCycleTime" BO_ 681 1000;
BA_ "TpTxIndex" BO_ 684 29;
BA_ "FrameRouting" BO_ 685 "FD1_CAN,0x25E;";
BA_ "TpTxIndex" BO_ 688 121;
BA_ "FrameRouting" BO_ 688 "FD2_CAN,0x2B0;";
BA_ "TpTxIndex" BO_ 689 12;
BA_ "TpTxIndex" BO_ 692 15;
BA_ "TpTxIndex" BO_ 694 17;
BA_ "TpTxIndex" BO_ 695 18;
BA_ "TpTxIndex" BO_ 696 121;
BA_ "TpTxIndex" BO_ 697 12;
BA_ "NetworkInitialization" BO_ 697 0;
BA_ "TpTxIndex" BO_ 700 15;
BA_ "TpTxIndex" BO_ 702 17;
BA_ "NetworkInitialization" BO_ 702 0;
BA_ "TpTxIndex" BO_ 703 18;
BA_ "NetworkInitialization" BO_ 703 0;
BA_ "TpTxIndex" BO_ 704 31;
BA_ "TpTxIndex" BO_ 705 27;
BA_ "TpTxIndex" BO_ 706 28;
BA_ "TpTxIndex" BO_ 707 23;
BA_ "TpTxIndex" BO_ 708 33;
BA_ "TpTxIndex" BO_ 709 25;
BA_ "TpTxIndex" BO_ 710 26;
BA_ "FrameRouting" BO_ 710 "MS1_CAN,0x2C6;";
BA_ "TpTxIndex" BO_ 711 24;
BA_ "NetworkInitialization" BO_ 711 0;
BA_ "TpTxIndex" BO_ 712 31;
BA_ "NetworkInitialization" BO_ 712 0;
BA_ "TpTxIndex" BO_ 713 27;
BA_ "TpTxIndex" BO_ 714 28;
BA_ "NetworkInitialization" BO_ 714 0;
BA_ "TpTxIndex" BO_ 715 23;
BA_ "TpTxIndex" BO_ 716 33;
BA_ "TpTxIndex" BO_ 717 25;
BA_ "TpTxIndex" BO_ 718 26;
BA_ "TpTxIndex" BO_ 719 24;
BA_ "GenMsgSendType" BO_ 720 5;
BA_ "GenMsgCycleTime" BO_ 720 1000;
BA_ "GenMsgSendType" BO_ 721 5;
BA_ "GenMsgCycleTime" BO_ 721 1000;
BA_ "GenMsgSendType" BO_ 722 5;
BA_ "GenMsgCycleTime" BO_ 722 1000;
BA_ "GenMsgSendType" BO_ 725 5;
BA_ "GenMsgCycleTime" BO_ 725 1000;
BA_ "GenSigStartValue" SG_ 531 PrkBrkStatus 7;
BA_ "GenSigStartValue" SG_ 531 VehStop_D_Stat 2;
BA_ "WakeupSignal" SG_ 531 PrkBrkRedLamp_D_Rq 1;
BA_ "WakeupSignal" SG_ 531 PrkBrkMsgTxt_D_Rq 1;
BA_ "WakeupSignal" SG_ 531 PrkBrkYwLamp_D_Rq 1;
BA_ "GenSigSendType" SG_ 533 TCU_Init_Actvtn_St 3;
BA_ "GenSigSendType" SG_ 533 TCU_Final_Actvtn_St 3;
BA_ "GenSigSendType" SG_ 533 TrlrAidMde_D_Rq 3;
BA_ "GenSigSendType" SG_ 533 PaakMyKey_D_Rq 3;
BA_ "GenSigSendType" SG_ 533 DcacMdeButtn_B_Stat 3;
BA_ "GenSigSendType" SG_ 533 DcacGfciTestBttn_B_Stat 3;
BA_ "GenSigSendType" SG_ 533 DcacPwButtn_B_Stat 3;
BA_ "GenSigSendType" SG_ 533 DcacPwResetButtn_B_Stat 3;
BA_ "GenSigSendType" SG_ 533 DcacPwOffButtn_B_Stat 3;
BA_ "GenSigSendType" SG_ 533 DcacPwLoButtn_B_Stat 3;
BA_ "GenSigSendType" SG_ 533 DcacPwHiButtn_B_Stat 3;
BA_ "GenSigSendType" SG_ 533 DcacPwButtn_B_Falt 3;
BA_ "GenSigSendType" SG_ 533 OnbChrgGoTUpdate_B_Rq 3;
BA_ "ECGUsedRxSignal" SG_ 533 OnbChrgGoTUpdate_B_Rq 1;
BA_ "GenSigSendType" SG_ 533 OnbChrgGoTDelete_B_Rq 3;
BA_ "GenSigSendType" SG_ 533 OnbChrgClearAll_B_Rq 3;
BA_ "GenSigSendType" SG_ 533 AutoEpbButtn_B_Stat 3;
BA_ "GenSigSendType" SG_ 533 TrlrHitch_D_RqMnu 3;
BA_ "GenSigStartValue" SG_ 533 OnbChrgGoTOn_D_Rq 2;
BA_ "GenSigSendType" SG_ 533 OnbChrgGoTOn_D_Rq 3;
BA_ "GenSigSendType" SG_ 533 OnbChrgGoTExtHtr_D_Rq 3;
BA_ "GenSigSendType" SG_ 533 OnbChrgGoTElement_D_Rq 3;
BA_ "GenSigSendType" SG_ 533 AutoEpbZoomView_B_Stat 3;
BA_ "GenSigSendType" SG_ 533 OnbChrgGoTPrcond_D_Rq 3;
BA_ "GenSigStartValue" SG_ 533 OnbChrgGoTHr_T_Rq 30;
BA_ "GenSigSendType" SG_ 533 OtaTrg_D_Stat 3;
BA_ "GenSigSendType" SG_ 533 OnbChrgGoTTouch_D_Rq 3;
BA_ "WakeupSignal" SG_ 533 LghtAmbDrvMde_D_Rq 1;
BA_ "GenSigSendType" SG_ 533 LghtAmbDrvMde_D_Rq 3;
BA_ "GenSigSendType" SG_ 533 TrlrAlarmButtn_B_Stat 3;
BA_ "GenSigSendType" SG_ 533 TrlrBrkGain_No_Rq 3;
BA_ "GenSigSendType" SG_ 533 TjaLcEnbl_D_RqMnu 3;
BA_ "GenSigStartValue" SG_ 533 ExtLghtRvrseOn_B_Rq 1;
BA_ "GenSigSendType" SG_ 533 ExtLghtRvrseOn_B_Rq 3;
BA_ "GenSigSendType" SG_ 533 ClrExitAsstEnbl_D_RqMnu 3;
BA_ "GenSigSendType" SG_ 533 DcacPw_D_Rq 3;
BA_ "GenSigSendType" SG_ 533 DcacPwReset_B_Rq 3;
BA_ "GenSigSendType" SG_ 538 MK_ESCRestrictConf_St 3;
BA_ "GenSigSendType" SG_ 538 MK_ECalRestrictConf_St 3;
BA_ "GenSigSendType" SG_ 538 MK_DNDRestrictConf_St 3;
BA_ "GenSigSendType" SG_ 538 MK_AudioLimitConfig_St 3;
BA_ "GenSigSendType" SG_ 538 MK_SpeedLimitConf_St 3;
BA_ "GenSigSendType" SG_ 538 MK_SpeedMinderConf_St 3;
BA_ "GenSigSendType" SG_ 538 MK_AdminMyKeyCount_St 3;
BA_ "GenSigSendType" SG_ 538 MK_UserMyKeyCount_St 3;
BA_ "WakeupSignal" SG_ 539 NfcDevcDetct_D_Stat 1;
BA_ "GenSigStartValue" SG_ 540 NfcDevcTapMsg_UNUSED_6bit_1 63;
BA_ "GenSigInactiveValue" SG_ 540 NfcDevcTapMsg_UNUSED_6bit_1 63;
BA_ "GenSigStartValue" SG_ 540 NfcDevcTapMsg_UNUSED_8bit_1 255;
BA_ "GenSigInactiveValue" SG_ 540 NfcDevcTapMsg_UNUSED_8bit_1 255;
BA_ "GenSigStartValue" SG_ 540 NfcDevcTapMsg_UNUSED_8bit_2 255;
BA_ "GenSigInactiveValue" SG_ 540 NfcDevcTapMsg_UNUSED_8bit_2 255;
BA_ "GenSigStartValue" SG_ 540 NfcDevcTapMsg_UNUSED_8bit_3 255;
BA_ "GenSigInactiveValue" SG_ 540 NfcDevcTapMsg_UNUSED_8bit_3 255;
BA_ "GenSigStartValue" SG_ 540 NfcDevcTapMsg_UNUSED_8bit_4 255;
BA_ "GenSigInactiveValue" SG_ 540 NfcDevcTapMsg_UNUSED_8bit_4 255;
BA_ "GenSigStartValue" SG_ 540 NfcDevcTapMsg_UNUSED_8bit_5 255;
BA_ "GenSigInactiveValue" SG_ 540 NfcDevcTapMsg_UNUSED_8bit_5 255;
BA_ "ECGUsedRxSignal" SG_ 543 TeltalWarnData_No_Actl 1;
BA_ "GenSigSendType" SG_ 544 Chime_Time_Criticality 3;
BA_ "ECGUsedRxSignal" SG_ 544 Chime_Time_Criticality 1;
BA_ "GenSigSendType" SG_ 544 Chime_Directionality 3;
BA_ "ECGUsedRxSignal" SG_ 544 Chime_Directionality 1;
BA_ "WakeupSignal" SG_ 544 Chime 1;
BA_ "GenSigSendType" SG_ 544 AdjustableChimeVol_Rq 3;
BA_ "ECGUsedRxSignal" SG_ 544 AdjustableChimeVol_Rq 1;
BA_ "GenSigSendType" SG_ 544 ChimeId_No_Rq 3;
BA_ "GenSigSendType" SG_ 544 Chime_Occurence 3;
BA_ "ECGUsedRxSignal" SG_ 544 Chime_Occurence 1;
BA_ "ECGUsedRxSignal" SG_ 544 Off_Time_Btwn_Chime 1;
BA_ "GenSigSendType" SG_ 545 DSP_MyKeyVolLim_St 3;
BA_ "GenSigSendType" SG_ 545 DSP_BeltminderAudio_St 3;
BA_ "GenSigSendType" SG_ 545 DSP_Sur_Sound_st 3;
BA_ "GenSigSendType" SG_ 545 DSP_Audio_Volume_Up_St 3;
BA_ "ECGUsedRxSignal" SG_ 545 DSP_Audio_Volume_Up_St 1;
BA_ "GenSigSendType" SG_ 545 DSP_Audio_Vol_Level_St 3;
BA_ "GenSigSendType" SG_ 545 DSP_MyKeyVolLimitUp_St 3;
BA_ "GenSigSendType" SG_ 545 DSP_Bezel_Diag_St 3;
BA_ "GenSigSendType" SG_ 545 AutoConfigOcc_Rear 3;
BA_ "GenSigSendType" SG_ 545 AutoConfigOcc_AllSeats 3;
BA_ "GenSigSendType" SG_ 545 AutoConfigOcc_Front 3;
BA_ "GenSigSendType" SG_ 545 AutoConfigOcc_Driver 3;
BA_ "GenSigSendType" SG_ 545 SurndSndUpmix2_D_Stat 3;
BA_ "GenSigSendType" SG_ 545 AudioOccMde_D_Stat 3;
BA_ "GenSigSendType" SG_ 545 SpkrDgtlCntr_D_Stat 3;
BA_ "GenSigSendType" SG_ 545 SpkrDgtlLeft_D_Stat 3;
BA_ "GenSigSendType" SG_ 545 SpkrDgtlRight_D_Stat 3;
BA_ "GenSigSendType" SG_ 545 SndImmrsnLvl_D_Stat 3;
BA_ "GenSigSendType" SG_ 546 SYNC_Attn_Info_Audio 3;
BA_ "GenSigSendType" SG_ 546 Audible_Beep 3;
BA_ "GenSigSendType" SG_ 546 SYNC_New_Attn_Event 3;
BA_ "GenSigSendType" SG_ 546 Alert_Chan 3;
BA_ "GenSigSendType" SG_ 546 PrplSnd_D_Rq 3;
BA_ "GenSigSendType" SG_ 546 Prompt_Directionality 3;
BA_ "GenSigSendType" SG_ 547 Chime_Alert_Chan 3;
BA_ "GenSigSendType" SG_ 547 AHU_Chime_Not_Recognized 3;
BA_ "GenSigSendType" SG_ 547 AHU_Chime2_Not_Recognized 3;
BA_ "GenSigSendType" SG_ 547 AHU_Chime_Supported 3;
BA_ "GenSigSendType" SG_ 547 Chime_Alert_Chan2 3;
BA_ "GenSigSendType" SG_ 547 AhuDgtlChime_D_Stat 3;
BA_ "GenSigSendType" SG_ 547 AHU_Alert_Channel1 3;
BA_ "GenSigSendType" SG_ 547 AHU_Chime_Active 3;
BA_ "GenSigSendType" SG_ 547 AHU_AdjChimVolSupp2_St 3;
BA_ "GenSigSendType" SG_ 547 AHU_AdjChimeVolSupp_St 3;
BA_ "GenSigSendType" SG_ 547 Audio_Amp_St 3;
BA_ "ECGUsedRxSignal" SG_ 547 Audio_Amp_St 1;
BA_ "GenSigSendType" SG_ 547 AHU_Chime2_Active 3;
BA_ "GenSigSendType" SG_ 547 ChimeId_No_Stat 3;
BA_ "GenSigSendType" SG_ 547 Chime2Id_No_Stat 3;
BA_ "GenSigSendType" SG_ 548 DspDgtlChime_D_Stat 3;
BA_ "GenSigSendType" SG_ 548 DSP_Chimes_Supported 3;
BA_ "GenSigSendType" SG_ 548 DSP_Alert_Channel1 3;
BA_ "GenSigSendType" SG_ 548 DSP_Alert_Channel2 3;
BA_ "GenSigSendType" SG_ 548 DSP_Chime2_Not_Recgnizd 3;
BA_ "GenSigSendType" SG_ 548 DSP_Chime_Not_Recgnizd 3;
BA_ "GenSigSendType" SG_ 548 DSP_Alert_Channel3 3;
BA_ "GenSigSendType" SG_ 548 DSP_AdjChimVolSupp_St 3;
BA_ "GenSigSendType" SG_ 548 DSP_AdjChimVolSupp2_St 3;
BA_ "GenSigSendType" SG_ 548 DSP_AHU_ChmTstTone_Rq 3;
BA_ "GenSigSendType" SG_ 548 DSP_ChimeChanState_St 3;
BA_ "GenSigSendType" SG_ 548 DSP_AHU_ChmTstT 3;
BA_ "GenSigSendType" SG_ 549 IPC_New_Attn_Event 3;
BA_ "GenSigSendType" SG_ 549 HudBrightMnuOn_B_Rq 3;
BA_ "GenSigSendType" SG_ 549 IPC_Attn_Info_Audio 3;
BA_ "GenSigSendType" SG_ 549 BeltminderAudioMute 3;
BA_ "GenSigSendType" SG_ 549 MetricActv_B_Dsply 3;
BA_ "GenSigSendType" SG_ 549 IPC_MyKeyVolLimit_St 3;
BA_ "GenSigSendType" SG_ 549 HudVertMnuOn_B_Rq 3;
BA_ "GenSigSendType" SG_ 549 SpeedChngChime_D_Rq2 3;
BA_ "GenSigSendType" SG_ 549 Chime_Source 3;
BA_ "ECGUsedRxSignal" SG_ 549 Chime_Source 1;
BA_ "GenSigSendType" SG_ 549 StrtInGearOk_D_Stat 3;
BA_ "ECGUsedRxSignal" SG_ 549 StrtInGearOk_D_Stat 1;
BA_ "GenSigSendType" SG_ 549 FactoryReset_Rq2 3;
BA_ "ECGUsedRxSignal" SG_ 549 FactoryReset_Rq2 1;
BA_ "GenSigSendType" SG_ 549 HdcOn_B_Rq 3;
BA_ "GenSigSendType" SG_ 549 HudCntntMnuOn_B_Rq 3;
BA_ "GenSigSendType" SG_ 549 HudVertSzMnuOn_B_Rq 3;
BA_ "GenSigSendType" SG_ 549 HudRotatMnuOn_B_Rq 3;
BA_ "WakeupSignal" SG_ 549 Power_Up_Chime_Modules 1;
BA_ "GenSigSendType" SG_ 549 Power_Up_Chime_Modules 3;
BA_ "ECGUsedRxSignal" SG_ 549 Power_Up_Chime_Modules 1;
BA_ "GenSigSendType" SG_ 549 WndwCabnMde_D_Rq2 3;
BA_ "GenSigSendType" SG_ 549 HazrdLghtMde_D_Rq2 3;
BA_ "GenSigSendType" SG_ 549 DelvrAsstLckMde_D_Rq2 3;
BA_ "GenSigSendType" SG_ 549 DelvrAsstButtn_D_Rq2 3;
BA_ "GenSigSendType" SG_ 549 Veh_V2_Dsply 3;
BA_ "GenSigSendType" SG_ 549 TjaLcEnbl_D_DrvRq 3;
BA_ "GenSigSendType" SG_ 549 CCOI_PolicyClient_St2 3;
BA_ "ECGUsedRxSignal" SG_ 549 CCOI_PolicyClient_St2 1;
BA_ "GenSigSendType" SG_ 549 WwaActv_B_Stat 3;
BA_ "GenSigSendType" SG_ 549 BattTracLoThres_D_Rq2 3;
BA_ "GenSigSendType" SG_ 549 NavIod_D_Rq 3;
BA_ "GenSigSendType" SG_ 551 PrkBrkPerfMnuOn_D_Stat 3;
BA_ "GenSigSendType" SG_ 551 PrkBrkPerfButtn_D_Stat 3;
BA_ "GenSigSendType" SG_ 551 TjaLaneBiasEnbl_D_RqMnu 3;
BA_ "GenSigSendType" SG_ 551 EcoIdl_D_Rq 3;
BA_ "GenSigSendType" SG_ 551 VehPerfDemo_B_RqDrv 3;
BA_ "GenSigSendType" SG_ 551 GoTElementEdit_No_RqMnu 3;
BA_ "ECGUsedRxSignal" SG_ 551 GoTElementEdit_No_RqMnu 1;
BA_ "GenSigSendType" SG_ 551 PrcondEdit_D_RqMnu 3;
BA_ "GenSigSendType" SG_ 551 SelDrvMdeDsply_B_Avai2 3;
BA_ "GenSigStartValue" SG_ 551 ChrgToPcEdit_Pc_RqMnu 126;
BA_ "GenSigSendType" SG_ 551 ChrgToPcEdit_Pc_RqMnu 3;
BA_ "GenSigSendType" SG_ 551 PwRnngBoardT_D_Rq 3;
BA_ "GenSigSendType" SG_ 551 PwRnngBoardSwtch_D_Rq 3;
BA_ "GenSigSendType" SG_ 551 PwRnngBoardMde_D_Rq 3;
BA_ "GenSigSendType" SG_ 551 Rba_D_Rq 3;
BA_ "GenSigSendType" SG_ 551 EmPrflButtnAssoc_D_Rq 3;
BA_ "GenSigSendType" SG_ 551 PmCabnLvl_D_Stat 3;
BA_ "GenSigSendType" SG_ 551 PmCabn_D_Stat 3;
BA_ "WakeupSignal" SG_ 551 Cntr_Plg_Mode_Cmd 1;
BA_ "GenSigSendType" SG_ 551 Cntr_Plg_Mode_Cmd 3;
BA_ "GenSigSendType" SG_ 551 OneTEditActv_B_RqMnu 3;
BA_ "ECGUsedRxSignal" SG_ 551 OneTEditActv_B_RqMnu 1;
BA_ "GenSigSendType" SG_ 551 BattTracLoThres_D_Rq 3;
BA_ "GenSigSendType" SG_ 551 EmPrflKeyAssoc_D_Rq 3;
BA_ "GenSigSendType" SG_ 551 ChrgCrdLckEnbl_B_Stat 3;
BA_ "ECGUsedRxSignal" SG_ 551 ChrgCrdLckEnbl_B_Stat 1;
BA_ "GenSigSendType" SG_ 551 WndwChildLckPw_B_RqMnu 3;
BA_ "ECGUsedRxSignal" SG_ 551 WndwChildLckPw_B_RqMnu 1;
BA_ "GenSigStartValue" SG_ 551 Btt_L_Actl2 126;
BA_ "GenSigStartValue" SG_ 551 BecConfg_B_RqMnu 1;
BA_ "GenSigSendType" SG_ 551 BecConfg_B_RqMnu 3;
BA_ "GenSigSendType" SG_ 551 ChrgOvrdExitScrn_D_Rq 3;
BA_ "ECGUsedRxSignal" SG_ 551 ChrgOvrdExitScrn_D_Rq 1;
BA_ "GenSigSendType" SG_ 551 EmPrflNo_D_Rq 3;
BA_ "WakeupSignal" SG_ 551 Em_D_Stat 1;
BA_ "GenSigSendType" SG_ 551 Em_D_Stat 3;
BA_ "GenSigSendType" SG_ 552 Audio_Demo_Status 3;
BA_ "GenSigSendType" SG_ 552 DSP_Shaker_St 3;
BA_ "GenSigSendType" SG_ 552 DSP_AVC_St 3;
BA_ "GenSigSendType" SG_ 552 DSP_NavCmdVolume_Up 1;
BA_ "GenSigSendType" SG_ 552 DSP_Balance_St 3;
BA_ "GenSigSendType" SG_ 552 DSP_Bass_St 3;
BA_ "GenSigSendType" SG_ 552 DSP_DSPProgram_St 3;
BA_ "GenSigSendType" SG_ 552 DSP_DSP_St 3;
BA_ "GenSigSendType" SG_ 552 DSP_Fader_St 3;
BA_ "GenSigSendType" SG_ 552 DSP_PhoneVolume_Up 1;
BA_ "GenSigSendType" SG_ 552 DSP_Reg_St 3;
BA_ "GenSigSendType" SG_ 552 DSP_TAVolume_Up 1;
BA_ "GenSigSendType" SG_ 552 DSP_VoiceFBVolume_Up 1;
BA_ "GenSigSendType" SG_ 552 DSP_Midrange_St 3;
BA_ "GenSigSendType" SG_ 552 DSP_Treble_St 3;
BA_ "GenSigSendType" SG_ 552 ActvNseMute_D_Stat 3;
BA_ "GenSigSendType" SG_ 553 ResetTrip2_B_Rq 3;
BA_ "GenSigSendType" SG_ 553 ResetTrip1_B_Rq 3;
BA_ "GenSigSendType" SG_ 553 Audio_Demo_CMND 3;
BA_ "GenSigSendType" SG_ 553 Audio_Visualizer 3;
BA_ "GenSigSendType" SG_ 553 Surround_Sound_Upmix 3;
BA_ "ECGUsedRxSignal" SG_ 553 CCOI_PolicyClient_St 1;
BA_ "GenSigSendType" SG_ 553 Bezel_Diag_Module_Rq 3;
BA_ "GenSigSendType" SG_ 553 Disp_LangSel_St 3;
BA_ "ECGUsedRxSignal" SG_ 553 Disp_LangSel_St 1;
BA_ "GenSigSendType" SG_ 553 ResetAvgFe_B_Rq 3;
BA_ "GenSigSendType" SG_ 553 Bezel_Diag_State_Rq 3;
BA_ "GenSigSendType" SG_ 553 SurndSndUpmix2_D_Rq 3;
BA_ "GenSigSendType" SG_ 553 Diagnostic_Operation_Rq 3;
BA_ "GenSigSendType" SG_ 553 Disp_LangSel2_St 3;
BA_ "ECGUsedRxSignal" SG_ 553 Disp_LangSel2_St 1;
BA_ "GenSigSendType" SG_ 553 SndImmrsnLvl_D_Rq 3;
BA_ "GenSigStartValue" SG_ 553 DistToChrgrBynd_L_Actl 510;
BA_ "GenSigSendType" SG_ 553 InfoSysMasterPw_D_Stat 3;
BA_ "ECGUsedRxSignal" SG_ 553 InfoSysMasterPw_D_Stat 1;
BA_ "GenSigSendType" SG_ 554 SeatOccRearMsgTxt_B_Rq 3;
BA_ "ECGUsedTxSignal" SG_ 554 SeatOccRearMsgTxt_B_Rq 1;
BA_ "GenSigSendType" SG_ 554 DrvHazrdModel_D_St 3;
BA_ "ECGUsedTxSignal" SG_ 554 DrvHazrdModel_D_St 1;
BA_ "GenSigStartValue" SG_ 554 DrvHazrd_D_St 2;
BA_ "GenSigSendType" SG_ 554 DrvHazrd_D_St 3;
BA_ "ECGUsedTxSignal" SG_ 554 DrvHazrd_D_St 1;
BA_ "GenSigSendType" SG_ 554 AudioPersSrvcId_No_Rq 3;
BA_ "ECGUsedTxSignal" SG_ 554 AudioPersSrvcId_No_Rq 1;
BA_ "GenSigSendType" SG_ 554 Drv_Set_Tmp2 3;
BA_ "ECGUsedTxSignal" SG_ 554 Drv_Set_Tmp2 1;
BA_ "GenSigSendType" SG_ 554 Frt_Btn_Status_1st_2 3;
BA_ "ECGUsedTxSignal" SG_ 554 Frt_Btn_Status_1st_2 1;
BA_ "GenSigSendType" SG_ 554 AudioPersFeat_No_Rq 3;
BA_ "ECGUsedTxSignal" SG_ 554 AudioPersFeat_No_Rq 1;
BA_ "GenSigSendType" SG_ 554 AudioPersFeatVal_No_Rq 3;
BA_ "ECGUsedTxSignal" SG_ 554 AudioPersFeatVal_No_Rq 1;
BA_ "WakeupSignal" SG_ 554 PtWakeupActv1_B_Rq 1;
BA_ "GenSigSendType" SG_ 554 PtWakeupActv1_B_Rq 3;
BA_ "ECGUsedTxSignal" SG_ 554 PtWakeupActv1_B_Rq 1;
BA_ "GenSigSendType" SG_ 554 AudioPersSrvc_D_Rq 3;
BA_ "ECGUsedTxSignal" SG_ 554 AudioPersSrvc_D_Rq 1;
BA_ "GenSigStartValue" SG_ 554 AudioPersIndx_D_Rq 4;
BA_ "GenSigSendType" SG_ 554 AudioPersIndx_D_Rq 3;
BA_ "ECGUsedTxSignal" SG_ 554 AudioPersIndx_D_Rq 1;
BA_ "GenSigSendType" SG_ 555 HudActv_D_Stat 3;
BA_ "GenSigSendType" SG_ 555 HudTestMdeActv_B_Stat 3;
BA_ "GenSigSendType" SG_ 555 HudHzntlMnuOn_B_Stat 3;
BA_ "GenSigSendType" SG_ 555 HudRotatMnuOn_B_Stat 3;
BA_ "GenSigSendType" SG_ 555 HudVertMnuOn_B_Stat 3;
BA_ "GenSigSendType" SG_ 555 HudBrightMnuOn_B_Stat 3;
BA_ "GenSigSendType" SG_ 555 HudSwtch_B_Stat 3;
BA_ "GenSigSendType" SG_ 555 HudVertSzMnuOn_B_Stat 3;
BA_ "GenSigSendType" SG_ 555 HudMsgTxt_D_Rq 3;
BA_ "GenSigSendType" SG_ 556 PassRstrnInd_Stat 3;
BA_ "GenSigSendType" SG_ 556 DrvAsstMnuButtn_B_Stat 3;
BA_ "GenSigSendType" SG_ 556 Bezel_Beeps_Supported 3;
BA_ "GenSigSendType" SG_ 556 Bezel_Beep_St 3;
BA_ "GenSigSendType" SG_ 556 EFP_Bezel_Diag_St 3;
BA_ "GenSigSendType" SG_ 556 Manual_Temp_Setting 3;
BA_ "GenSigSendType" SG_ 557 AudioToneTouchX_D_Stat 3;
BA_ "GenSigSendType" SG_ 557 AudioToneTouchY_D_Stat 3;
BA_ "GenSigSendType" SG_ 557 AudioPersSrvc_D_Res 3;
BA_ "ECGUsedRxSignal" SG_ 557 AudioPersSrvc_D_Res 1;
BA_ "GenSigSendType" SG_ 557 AudioPersChng_D_Stat 3;
BA_ "ECGUsedRxSignal" SG_ 557 AudioPersChng_D_Stat 1;
BA_ "GenSigSendType" SG_ 557 AudioToneTouch_D_Stat 3;
BA_ "WakeupSignal" SG_ 557 AudioPersSrvcId_No_Act 1;
BA_ "GenSigSendType" SG_ 557 AudioPersSrvcId_No_Act 3;
BA_ "ECGUsedRxSignal" SG_ 557 AudioPersSrvcId_No_Act 1;
BA_ "WakeupSignal" SG_ 557 AudioPersFeatCnt_No_Act 1;
BA_ "GenSigSendType" SG_ 557 AudioPersFeatCnt_No_Act 3;
BA_ "ECGUsedRxSignal" SG_ 557 AudioPersFeatCnt_No_Act 1;
BA_ "GenSigSendType" SG_ 557 AudioPersFeat_No_Actl 3;
BA_ "ECGUsedRxSignal" SG_ 557 AudioPersFeat_No_Actl 1;
BA_ "GenSigSendType" SG_ 557 AudioPersFeatVal_No_Act 3;
BA_ "ECGUsedRxSignal" SG_ 557 AudioPersFeatVal_No_Act 1;
BA_ "GenSigSendType" SG_ 558 EhData1_No_Actl 1;
BA_ "ECGUsedTxSignal" SG_ 558 EhData1_No_Actl 1;
BA_ "GenSigSendType" SG_ 559 EhData2_No_Actl 1;
BA_ "ECGUsedTxSignal" SG_ 559 EhData2_No_Actl 1;
BA_ "GenSigStartValue" SG_ 560 GearLvrPos_D_Actl 14;
BA_ "GenSigStartValue" SG_ 560 GboxOil_Te_Actl 254;
BA_ "GenSigSendType" SG_ 563 OfbChrgSetSync_D_Rq 3;
BA_ "ECGUsedTxSignal" SG_ 563 OfbChrgSetSync_D_Rq 1;
BA_ "GenSigSendType" SG_ 563 ModemReset_D_Stat 3;
BA_ "ECGUsedTxSignal" SG_ 563 ModemReset_D_Stat 1;
BA_ "GenSigSendType" SG_ 563 FactoryReset_St 3;
BA_ "ECGUsedTxSignal" SG_ 563 FactoryReset_St 1;
BA_ "GenSigStartValue" SG_ 563 GridSrvc01_D_RqCld 2;
BA_ "GenSigSendType" SG_ 563 GridSrvc01_D_RqCld 3;
BA_ "ECGUsedTxSignal" SG_ 563 GridSrvc01_D_RqCld 1;
BA_ "GenSigSendType" SG_ 563 BattChrgStrtStop_D_Rq 3;
BA_ "ECGUsedTxSignal" SG_ 563 BattChrgStrtStop_D_Rq 1;
BA_ "GenSigSendType" SG_ 563 DrvBhavWarn_B_Rq 3;
BA_ "ECGUsedTxSignal" SG_ 563 DrvBhavWarn_B_Rq 1;
BA_ "GenSigSendType" SG_ 563 KeyOffPwMde_D_Stat 3;
BA_ "ECGUsedTxSignal" SG_ 563 KeyOffPwMde_D_Stat 1;
BA_ "WakeupSignal" SG_ 563 NtfyDrvTrgtDist_L2_Rq 1;
BA_ "GenSigStartValue" SG_ 563 NtfyDrvTrgtDist_L2_Rq 8190;
BA_ "GenSigSendType" SG_ 563 NtfyDrvTrgtDist_L2_Rq 3;
BA_ "ECGUsedTxSignal" SG_ 563 NtfyDrvTrgtDist_L2_Rq 1;
BA_ "GenSigSendType" SG_ 563 VgfZone_D_Stat 3;
BA_ "ECGUsedTxSignal" SG_ 563 VgfZone_D_Stat 1;
BA_ "GenSigSendType" SG_ 563 DrvBhavAudioAlrt_D_Rq 3;
BA_ "ECGUsedTxSignal" SG_ 563 DrvBhavAudioAlrt_D_Rq 1;
BA_ "GenSigSendType" SG_ 563 EmgcyTrfcLght_D_Stat 3;
BA_ "ECGUsedTxSignal" SG_ 563 EmgcyTrfcLght_D_Stat 1;
BA_ "GenSigSendType" SG_ 563 BattChrgStrtStop_D2_Rq 3;
BA_ "ECGUsedTxSignal" SG_ 563 BattChrgStrtStop_D2_Rq 1;
BA_ "GenSigStartValue" SG_ 571 TrlrTngLoad_M_Est 2046;
BA_ "GenSigStartValue" SG_ 571 VehPayloadAdd_M_Est 2046;
BA_ "GenSigStartValue" SG_ 571 VehPayload_M_Est 1022;
BA_ "GenSigStartValue" SG_ 571 TrlrTngLoad_Pc_Est 126;
BA_ "GenSigStartValue" SG_ 571 VehFalr_Pc_Est 126;
BA_ "GenSigStartValue" SG_ 571 VehPayload_Pc_Est 126;
BA_ "GenSigStartValue" SG_ 572 BattTracSoc_Pc_LimHi 600;
BA_ "GenSigStartValue" SG_ 572 BattTracSoc_Pc_LimLo 400;
BA_ "GenSigStartValue" SG_ 572 BattTracSoc_Pc_MnPrtct 30;
BA_ "GenSigStartValue" SG_ 572 BattTracSoc_Pc_MxPrtct 700;
BA_ "GenSigStartValue" SG_ 572 BattTracClnt_Te_Actl 254;
BA_ "GenSigStartValue" SG_ 572 BattTracClnt_Te_Rq 190;
BA_ "WakeupSignal" SG_ 573 VehStrtKeyIndx_No_Actl 1;
BA_ "WakeupSignal" SG_ 573 VehStrtKeyType_D_Stat 1;
BA_ "WakeupSignal" SG_ 573 VehStrtKeySrc_D_Stat 1;
BA_ "GenSigStartValue" SG_ 573 Esclck1DRqLim_No_Cs 255;
BA_ "GenSigStartValue" SG_ 573 Esclck1DRqLim_No_Cnt 1;
BA_ "GenSigSendType" SG_ 581 TRAFFIC_RDISP_WORD_Tx 3;
BA_ "GenSigStartValue" SG_ 582 BattULo_I_Actl 16383;
BA_ "GenSigStartValue" SG_ 582 BattULo_U_Actl 255;
BA_ "WakeupSignal" SG_ 582 PrkLckCtlAvail_T_Stat 1;
BA_ "WakeupSignal" SG_ 582 PrkLckCtlMsgTxt_D_Rq 1;
BA_ "WakeupSignal" SG_ 582 ReFuelSwtchStat_D_Actl 1;
BA_ "GenSigSendType" SG_ 589 TRAFFIC_RDISP_WORD_Rx 3;
BA_ "GenSigStartValue" SG_ 591 BattTrac_E_Nom 4094;
BA_ "GenSigStartValue" SG_ 591 BattTrac_U_Nom 1022;
BA_ "GenSigStartValue" SG_ 591 BattTrac_Ah_Nom 4093;
BA_ "GenSigStartValue" SG_ 591 BattTracType_D_Actl 8;
BA_ "GenSigStartValue" SG_ 591 BattChrgRqd_E_Actl 4094;
BA_ "GenSigSendType" SG_ 592 RFA_BLEM_APIM_Tx 3;
BA_ "ECGUsedTxSignal" SG_ 593 ECG_MC_WORD_Tx 1;
BA_ "GenSigStartValue" SG_ 594 BattTracClntIn_Te_Actl 75;
BA_ "GenSigStartValue" SG_ 594 BattTrac_Te_Actl 150;
BA_ "GenSigStartValue" SG_ 594 HvacRec_D_RqMxBatt 10;
BA_ "GenSigStartValue" SG_ 594 BattTracSoc2_Pc_Actl 16382;
BA_ "WakeupSignal" SG_ 594 HvacAirFlw_B_RqBatt 1;
BA_ "GenSigStartValue" SG_ 594 BattTracSoc_Pc_Dsply 254;
BA_ "GenSigSendType" SG_ 595 TrakAppl_D_RqMnu 3;
BA_ "GenSigSendType" SG_ 595 DrvIdMde_D_Rq 3;
BA_ "GenSigSendType" SG_ 595 DrvIdDelete_No_Rq 3;
BA_ "GenSigSendType" SG_ 595 EngIdlShutDownT_D_Rq 3;
BA_ "GenSigSendType" SG_ 595 TrakApplActvSet_D_Rq 3;
BA_ "GenSigSendType" SG_ 600 APIM_RFA_BLEM_Tx 3;
BA_ "ECGUsedRxSignal" SG_ 601 ECG_MC_WORD_Rx 1;
BA_ "GenSigStartValue" SG_ 602 BattTracRsrvSoc_Pc_Rq 16382;
BA_ "WakeupSignal" SG_ 608 DcChrgWarnLamp_B_Rq 1;
BA_ "GenSigStartValue" SG_ 608 EvseDcChrgIso_D_Stat 6;
BA_ "GenSigStartValue" SG_ 608 EvseChrg2_Pw_Mx 32766;
BA_ "GenSigStartValue" SG_ 611 AwdRnge_D_Actl 7;
BA_ "GenSigStartValue" SG_ 611 TrnAout_Tq_RqMx 8191;
BA_ "GenSigStartValue" SG_ 613 BeltWarnThres_D_Stat 6;
BA_ "WakeupSignal" SG_ 618 PaakCtlPssvData_No_Actl 1;
BA_ "WakeupSignal" SG_ 618 PaakCtlRollCode_No_Stat 1;
BA_ "WakeupSignal" SG_ 618 PaakCtlData_D_Stat 1;
BA_ "WakeupSignal" SG_ 618 PaakLoclzd_D_Stat 1;
BA_ "WakeupSignal" SG_ 618 PaakCtlType_D_Stat 1;
BA_ "WakeupSignal" SG_ 619 PaakCtlActv_D_Rq 1;
BA_ "GenSigStartValue" SG_ 627 RoadStopLine_L_Est 65534;
BA_ "GenSigStartValue" SG_ 627 TrfcLght_V_Mn 254;
BA_ "GenSigStartValue" SG_ 627 TrfcLght_V_Mx 254;
BA_ "GenSigStartValue" SG_ 627 TrfcLghtDecel_A_Dsply 126;
BA_ "GenSigStartValue" SG_ 627 VehToInfrstrctr_D_Stat 6;
BA_ "GenSigStartValue" SG_ 630 TrfcLghtLeft_T_Actl 254;
BA_ "GenSigStartValue" SG_ 630 TrfcLghtRight_T_Actl 254;
BA_ "GenSigStartValue" SG_ 630 TrfcLghtStrght_T_Actl 254;
BA_ "GenSigStartValue" SG_ 630 TrfcLghtUturn_T_Actl 254;
BA_ "GenSigStartValue" SG_ 636 ModemSigStren_D_Stat 6;
BA_ "GenSigSendType" SG_ 639 OfbChrgGoTExtHtr_D_Rq 3;
BA_ "ECGUsedTxSignal" SG_ 639 OfbChrgGoTExtHtr_D_Rq 1;
BA_ "GenSigSendType" SG_ 639 OfbChrgGoTElement_D_Rq 3;
BA_ "ECGUsedTxSignal" SG_ 639 OfbChrgGoTElement_D_Rq 1;
BA_ "ECGUsedTxSignal" SG_ 639 OfbChrgGoTDelete_B_Rq 1;
BA_ "GenSigSendType" SG_ 639 OfbChrgClearAll_B_Rq 3;
BA_ "ECGUsedTxSignal" SG_ 639 OfbChrgClearAll_B_Rq 1;
BA_ "GenSigSendType" SG_ 639 OfbChrgGoTUpdate_B_Rq 3;
BA_ "ECGUsedTxSignal" SG_ 639 OfbChrgGoTUpdate_B_Rq 1;
BA_ "GenSigSendType" SG_ 639 OfbChrgGoTOn_D_Rq 3;
BA_ "ECGUsedTxSignal" SG_ 639 OfbChrgGoTOn_D_Rq 1;
BA_ "GenSigStartValue" SG_ 639 OfbChrgGoTHr_T_Rq 30;
BA_ "ECGUsedTxSignal" SG_ 639 OfbChrgGoTHr_T_Rq 1;
BA_ "GenSigSendType" SG_ 639 OfbChrgGoTTouch_D_Rq 3;
BA_ "ECGUsedTxSignal" SG_ 639 OfbChrgGoTTouch_D_Rq 1;
BA_ "ECGUsedTxSignal" SG_ 639 OfbChrgGoTPrcond_D_Rq 1;
BA_ "ECGUsedTxSignal" SG_ 639 OfbChrgGoTMnte_D_Rq 1;
BA_ "GenSigSendType" SG_ 639 ScOnb_B_Stat 3;
BA_ "ECGUsedTxSignal" SG_ 639 ScOnb_B_Stat 1;
BA_ "GenSigSendType" SG_ 639 OfbChrgPrflUpdate_B_Rq 3;
BA_ "ECGUsedTxSignal" SG_ 639 OfbChrgPrflUpdate_B_Rq 1;
BA_ "ECGUsedTxSignal" SG_ 645 VehImpactCode_No2_Actl 1;
BA_ "GenSigSendType" SG_ 647 HEC_BTEndTelService_Rq 3;
BA_ "GenSigSendType" SG_ 647 HEC_BTIncomingCall_Rq 3;
BA_ "GenSigSendType" SG_ 648 TrlrCamraHght_L_Actl 3;
BA_ "GenSigSendType" SG_ 648 TrlrWidth_L_Actl 3;
BA_ "GenSigSendType" SG_ 648 HitchToTrlrBox_L_Actl 3;
BA_ "GenSigSendType" SG_ 648 TrlrCamraCalib_D_Rq 3;
BA_ "GenSigStartValue" SG_ 649 AirAmb_Te_ActlCld2 512;
BA_ "GenSigStartValue" SG_ 651 CrnkInhbtSrvcHlth_B_St 1;
BA_ "GenSigSendType" SG_ 659 APIM_NFAM_Word_Tx 3;
BA_ "ECGUsedRxSignal" SG_ 659 APIM_NFAM_Word_Tx 1;
BA_ "GenSigSendType" SG_ 662 Rear_Temp 3;
BA_ "GenSigSendType" SG_ 662 Rear_Blower_Speed 3;
BA_ "GenSigSendType" SG_ 662 Running_Board_Cmd2 3;
BA_ "ECGUsedRxSignal" SG_ 662 Running_Board_Cmd2 1;
BA_ "GenSigSendType" SG_ 662 Rear_Set_Temp 3;
BA_ "GenSigSendType" SG_ 662 ActvButtnLeft_D_Rq 3;
BA_ "GenSigSendType" SG_ 662 Third_Rear_Blower_Speed 3;
BA_ "GenSigSendType" SG_ 662 RgstrSetObl_D_Rq 3;
BA_ "GenSigSendType" SG_ 662 Third_Rear_Set_Temp 3;
BA_ "GenSigSendType" SG_ 662 ScOnb_B_Stat2 3;
BA_ "ECGUsedTxSignal" SG_ 662 ScOnb_B_Stat2 1;
BA_ "ECGUsedRxSignal" SG_ 662 ScOnb_B_Stat2 1;
BA_ "GenSigSendType" SG_ 662 RgstrSetIbl_D_Rq 3;
BA_ "GenSigSendType" SG_ 662 ActvButtnRight_D_Rq 3;
BA_ "GenSigSendType" SG_ 662 RgstrSetIbr_D_Rq 3;
BA_ "GenSigSendType" SG_ 662 RgstrSetObr_D_Rq 3;
BA_ "GenSigStartValue" SG_ 663 Bpt_Pw_Allw 65534;
BA_ "GenSigStartValue" SG_ 663 BptMnSoc_L_Actl 8190;
BA_ "GenSigStartValue" SG_ 663 BptDchrg_T_Rmng 32766;
BA_ "GenSigStartValue" SG_ 663 Bpt_I_Est 1022;
BA_ "GenSigStartValue" SG_ 663 BptDchrg_Pw_Dsply 1022;
BA_ "GenSigSendType" SG_ 667 APIM_NFAM_Word_Rx 3;
BA_ "WakeupSignal" SG_ 672 BtnID_A 1;
BA_ "GenSigStartValue" SG_ 672 BtnID_A 255;
BA_ "WakeupSignal" SG_ 672 BtnID_B 1;
BA_ "GenSigStartValue" SG_ 672 BtnID_B 255;
BA_ "WakeupSignal" SG_ 672 BtnID_C 1;
BA_ "GenSigStartValue" SG_ 672 BtnID_C 255;
BA_ "WakeupSignal" SG_ 672 BtnID_D 1;
BA_ "GenSigStartValue" SG_ 672 BtnID_D 255;
BA_ "WakeupSignal" SG_ 672 Coding_BtnID_B 1;
BA_ "GenSigSendType" SG_ 672 Coding_BtnID_B 3;
BA_ "WakeupSignal" SG_ 672 Coding_BtnID_A 1;
BA_ "GenSigSendType" SG_ 672 Coding_BtnID_A 3;
BA_ "WakeupSignal" SG_ 672 Coding_BtnID_D 1;
BA_ "GenSigSendType" SG_ 672 Coding_BtnID_D 3;
BA_ "WakeupSignal" SG_ 672 Coding_BtnID_C 1;
BA_ "GenSigSendType" SG_ 672 Coding_BtnID_C 3;
BA_ "WakeupSignal" SG_ 672 SetVolume 1;
BA_ "GenSigStartValue" SG_ 672 SetVolume 30;
BA_ "GenSigSendType" SG_ 672 SetVolume 3;
BA_ "ECGUsedRxSignal" SG_ 672 SetVolume 1;
BA_ "WakeupSignal" SG_ 672 SetPointVolume 1;
BA_ "GenSigSendType" SG_ 672 SetPointVolume 3;
BA_ "ECGUsedRxSignal" SG_ 672 SetPointVolume 1;
BA_ "GenSigStartValue" SG_ 673 ICI_BtnID_A 255;
BA_ "GenSigStartValue" SG_ 673 ICI_BtnID_B 255;
BA_ "GenSigStartValue" SG_ 673 ICI_BtnID_C 255;
BA_ "GenSigStartValue" SG_ 673 ICI_BtnID_D 255;
BA_ "GenSigSendType" SG_ 674 RACM_BtnID_A 3;
BA_ "GenSigSendType" SG_ 674 RACM_BtnID_B 3;
BA_ "GenSigSendType" SG_ 674 RACM_BtnID_C 3;
BA_ "GenSigSendType" SG_ 674 RACM_BtnID_D 3;
BA_ "GenSigSendType" SG_ 674 RACM_Coding_BtnID_A 3;
BA_ "GenSigSendType" SG_ 674 RACM_Coding_BtnID_B 3;
BA_ "GenSigSendType" SG_ 674 RACM_Coding_BtnID_C 3;
BA_ "GenSigSendType" SG_ 674 RACM_Coding_BtnID_D 3;
BA_ "GenSigSendType" SG_ 674 RACM_SetVolume 3;
BA_ "GenSigStartValue" SG_ 674 ArmrestStwdRear_B_Stat 1;
BA_ "GenSigSendType" SG_ 674 ArmrestStwdRear_B_Stat 3;
BA_ "GenSigSendType" SG_ 674 RearMnuCtlLck_B_Stat 3;
BA_ "GenSigSendType" SG_ 674 RearAudioCtlLck_D_Stat 3;
BA_ "GenSigSendType" SG_ 677 SeatFnChngPsgr2_D_Rq3 3;
BA_ "GenSigSendType" SG_ 677 SeatFnChngDrv2_D_Rq3 3;
BA_ "GenSigSendType" SG_ 677 SeatMasgPsngrRr_D_Rq2 3;
BA_ "GenSigSendType" SG_ 677 SeatMasgDrvRr_D_Rq2 3;
BA_ "GenSigSendType" SG_ 677 SeatFnPsgr_D_Rq3 3;
BA_ "GenSigSendType" SG_ 677 SeatFnDrv_D_Rq3 3;
BA_ "GenSigSendType" SG_ 677 LghtAmbColr_No_Rq 3;
BA_ "GenSigSendType" SG_ 677 LghtAmbIntns_No_Rq 3;
BA_ "GenSigSendType" SG_ 677 DgtlShadeAr3Rear_D_Rq 3;
BA_ "GenSigSendType" SG_ 677 DgtlShadeAr2Rear_D_Rq 3;
BA_ "GenSigSendType" SG_ 677 DgtlShadeAr1Rear_D_Rq 3;
BA_ "GenSigSendType" SG_ 677 DgtlShadeAr5Rear_D_Rq 3;
BA_ "GenSigSendType" SG_ 677 DgtlShadeAr4Rear_D_Rq 3;
BA_ "GenSigSendType" SG_ 677 DgtlShadeMdeRear_D_Rq 3;
BA_ "GenSigSendType" SG_ 677 DgtlShadeAr6Rear_D_Rq 3;
BA_ "GenSigSendType" SG_ 681 Con_DB1temIndex_St 1;
BA_ "GenSigSendType" SG_ 688 APIM_TCUB_Word_Rx 3;
BA_ "GenSigSendType" SG_ 696 APIM_TCUB_Word_Tx 3;
BA_ "ECGUsedRxSignal" SG_ 696 APIM_TCUB_Word_Tx 1;
BA_ "GenSigSendType" SG_ 710 BEZEL_RDISP_WORD_Tx 3;
BA_ "GenSigSendType" SG_ 718 BEZEL_RDISP_WORD_Rx 3;
BA_ "ECGUsedRxSignal" SG_ 718 BEZEL_RDISP_WORD_Rx 1;
BA_ "GenSigSendType" SG_ 720 VRM_BTBatteryLevel_St 3;
BA_ "GenSigSendType" SG_ 720 VRM_BTSignalStrength_St 3;
BA_ "GenSigSendType" SG_ 720 VRM_BTNetworkStatus_St 3;
BA_ "GenSigSendType" SG_ 720 VRM_PhMicrophoneMute_St 3;
BA_ "GenSigSendType" SG_ 720 VRM_VRMMonoOutMode_St 3;
BA_ "GenSigSendType" SG_ 720 Aioc_ExtSrcOutpMode_St 3;
BA_ "GenSigSendType" SG_ 720 VRM_BondRequest_St 3;
BA_ "GenSigSendType" SG_ 720 VRM_BlutoothStatus_St 3;
BA_ "GenSigSendType" SG_ 720 VRM_SubscribeStatus_St 3;
BA_ "GenSigSendType" SG_ 720 VRM_BTPhoneSts_St 3;
BA_ "ECGUsedRxSignal" SG_ 720 VRM_BTPhoneSts_St 1;
BA_ "GenSigSendType" SG_ 721 VRM_ComTrafficInfDsp_St 3;
BA_ "GenSigSendType" SG_ 721 VRM_ComGuidance_St 3;
BA_ "GenSigSendType" SG_ 721 VRM_ComCallControl_St 3;
BA_ "GenSigSendType" SG_ 721 VRM_ComZoom_St 3;
BA_ "GenSigSendType" SG_ 721 VRM_ComDynamicGuidande_St 3;
BA_ "GenSigSendType" SG_ 721 VRM_ComDisplay_St 3;
BA_ "GenSigSendType" SG_ 721 VRM_ComDetour_St 3;
BA_ "GenSigSendType" SG_ 721 VRM_ComSelTrackSource_St 3;
BA_ "GenSigSendType" SG_ 721 VRM_VoiceRecStatus_St 3;
BA_ "GenSigSendType" SG_ 721 VRM_ComShowNavInfo_St 3;
BA_ "GenSigSendType" SG_ 721 VRM_ComDestHome_St 3;
BA_ "GenSigSendType" SG_ 721 VRM_ComTelService_St 3;
BA_ "GenSigSendType" SG_ 721 VRM_ComSelectDisc_St 3;
BA_ "GenSigSendType" SG_ 721 VRM_ComDelWaypoint_St 3;
BA_ "GenSigSendType" SG_ 721 VRM_SuggestedRoute_St 3;
BA_ "GenSigSendType" SG_ 721 VRM_ComBTDTMFTone_St 3;
BA_ "GenSigSendType" SG_ 721 VRM_Zoom_Option_St 3;
BA_ "GenSigSendType" SG_ 721 VRM_DetourUnit_st 3;
BA_ "GenSigSendType" SG_ 721 VRM_BTDefaultPhone_St 3;
BA_ "GenSigSendType" SG_ 722 VRM_ComShuffleDiscs_St 3;
BA_ "GenSigSendType" SG_ 722 VRM_ComTape_St 3;
BA_ "GenSigSendType" SG_ 722 VRM_ComPresetCall_St 3;
BA_ "GenSigSendType" SG_ 722 VRM_ComRSEDisplay_St 3;
BA_ "GenSigSendType" SG_ 722 VRM_NewSMS 3;
BA_ "GenSigSendType" SG_ 722 VRM_TMCVoice 3;
BA_ "GenSigSendType" SG_ 722 VRM_ComBand_St 3;
BA_ "GenSigSendType" SG_ 722 VRM_ComAutostore_St 3;
BA_ "GenSigSendType" SG_ 722 VRM_ComStFreqMode_St 3;
BA_ "GenSigSendType" SG_ 722 VRM_ComCompression_St 3;
BA_ "GenSigSendType" SG_ 722 VRM_ComShuffleTrack_St 3;
BA_ "GenSigSendType" SG_ 722 VRM_ComRouteStrategy_St 3;
BA_ "GenSigSendType" SG_ 722 VRM_ComSourceSelect_St 3;
BA_ "GenSigSendType" SG_ 722 VRM_ComDolbyNR_St 3;
BA_ "GenSigSendType" SG_ 725 ACU_CurrentRadioBand_St 3;
BA_ "GenSigSendType" SG_ 725 ACU_CurrentPTYCode_St 3;
BA_ "GenSigSendType" SG_ 725 ACU_CurrentPICode_St 3;
BA_ "GenSigSendType" SG_ 725 InfotainmentAudio_St 3;
BA_ "GenSigSendType" SG_ 725 ACU_CurrentFreq_St 3;
BA_ "GenSigSendType" SG_ 725 ACU_AFMode_St 3;
BA_ "GenSigSendType" SG_ 725 ACU_HardwareError_St 3;
BA_ "GenSigSendType" SG_ 725 ACU_RadioError_St 3;
BA_ "GenSigSendType" SG_ 725 ACU_CompLogic_St 3;
VAL_ 531 LscmbBrkPrchg_B_Actl 0 "Inactive" 1 "Active" ;
VAL_ 531 LscmbbMntr_B_Err 0 "NoMessage" 1 "DisplayMessage" ;
VAL_ 531 LscmbbDeny_B_ActlBrk 0 "No" 1 "Yes" ;
VAL_ 531 LscmbbBrkDis_B_Actl 0 "No" 1 "Yes" ;
VAL_ 531 LscmbbBrkDecel_B_Actl 0 "No" 1 "Yes" ;
VAL_ 531 LscmbbBaSensInc_B_Actl 0 "No" 1 "Yes" ;
VAL_ 531 AccStopActv_B_ActlBrk 0 "No" 1 "Yes" ;
VAL_ 531 StabCtlBrkActv_B_Actl 0 "No" 1 "Yes" ;
VAL_ 531 PrkBrkStatus 0 "Not_Supported" 1 "Rear_Caliper_Closed" 2 "Rear_Caliper_Transition" 3 "RWU_By_EPB_Active" 4 "Rear_Caliper_Open" 5 "EPB_Limphome_Active" 6 "ECD_by_Brake_ECU_Active" 7 "GeneralFault_MaintenceMode" ;
VAL_ 531 VehStop_D_Stat 0 "No" 1 "Yes" 2 "NoDataExists" 3 "Faulty" ;
VAL_ 531 PrkBrkRedLamp_D_Rq 0 "Off" 1 "On" 2 "Slow_Flash" 3 "Fast_Flash" ;
VAL_ 531 TracCtlPtActv_B_Actl 0 "Inactive" 1 "Active" ;
VAL_ 531 AccDis_B_ActlEpb 0 "No" 1 "Yes" ;
VAL_ 531 PrkBrkMsgTxt_D_Rq 0 "No_Message" 1 "Message1" 2 "Message2" 3 "Message3" 4 "Message4" 5 "Message5" 6 "Message6" 7 "Message7" 8 "Message8" 9 "Message9" 10 "Message10" 11 "Message11" 12 "Message12" 13 "Message13" 14 "Message14" 15 "Message15" ;
VAL_ 531 PrkBrkYwLamp_D_Rq 0 "Off" 1 "On" 2 "Slow_Flash" 3 "Fast_Flash" ;
VAL_ 531 VehicleStationary 0 "No" 1 "Yes" ;
VAL_ 531 VehLongOvrGnd_A_Est 1022 "Unknown" 1023 "Fault" ;
VAL_ 531 AccBrkDeny_B_Actl 0 "No" 1 "Yes" ;
VAL_ 531 AccBrkActv_B_Actl 0 "No" 1 "Yes" ;
VAL_ 531 AccBrkDis_B_Actl 0 "No" 1 "Yes" ;
VAL_ 531 AbsActv_B_Actl 0 "No" 1 "Yes" ;
VAL_ 531 PrplDrgCtlActv_B_Actl 0 "Inactive" 1 "Active" ;
VAL_ 531 CcDis_B_Cmd 0 "No" 1 "Yes" ;
VAL_ 531 CmbbBrkDis_B_Actl 0 "No" 1 "Yes" ;
VAL_ 531 CmbbBaSensInc_B_Actl 0 "No" 1 "Yes" ;
VAL_ 531 CmbbBrkDecel_B_Actl 0 "No" 1 "Yes" ;
VAL_ 531 CmbbBrkPrchg_B_Actl 0 "No" 1 "Yes" ;
VAL_ 531 CmbbDeny_B_ActlBrk 0 "No" 1 "Yes" ;
VAL_ 531 AccBrkPrchgActv_B_Actl 0 "No" 1 "Yes" ;
VAL_ 531 AccBrkTotTqMn_B_Actl 0 "No" 1 "Yes" ;
VAL_ 531 AccBrkWarm_B_Actl 0 "No" 1 "Yes" ;
VAL_ 533 TCU_Init_Actvtn_St 0 "Invalid" 1 "InitialActivateAccept" 2 "InitialActivateDeny" 3 "NotUsed" ;
VAL_ 533 TCU_Final_Actvtn_St 0 "Invalid" 1 "FinalActivateAccept" 2 "FinalActivateDeny" 3 "NotUsed" ;
VAL_ 533 TrlrAidMde_D_Rq 0 "NoRequest" 1 "Mode_1" 2 "Mode_2" 3 "Mode_3" ;
VAL_ 533 PaakMyKey_D_Rq 0 "None" 1 "RequestNewPaakMyKey" 2 "ConfirmNewPaakMyKey" 3 "NotUsed" ;
VAL_ 533 DcacMdeButtn_B_Stat 0 "Not_Pressed" 1 "Pressed" ;
VAL_ 533 DcacGfciTestBttn_B_Stat 0 "Not_Pressed" 1 "Pressed" ;
VAL_ 533 DcacPwButtn_B_Stat 0 "Not_Pressed" 1 "Pressed" ;
VAL_ 533 DcacPwResetButtn_B_Stat 0 "Not_Pressed" 1 "Pressed" ;
VAL_ 533 DcacPwOffButtn_B_Stat 0 "Not_Pressed" 1 "Pressed" ;
VAL_ 533 DcacPwLoButtn_B_Stat 0 "Not_Pressed" 1 "Pressed" ;
VAL_ 533 DcacPwHiButtn_B_Stat 0 "Not_Pressed" 1 "Pressed" ;
VAL_ 533 DcacPwButtn_B_Falt 0 "NotFaulted" 1 "Faulted" ;
VAL_ 533 OnbChrgGoTUpdate_B_Rq 0 "NoRequest" 1 "Request" ;
VAL_ 533 OnbChrgGoTDelete_B_Rq 0 "NoRequest" 1 "Request" ;
VAL_ 533 OnbChrgClearAll_B_Rq 0 "NoRequest" 1 "Request" ;
VAL_ 533 AutoEpbButtn_B_Stat 0 "Not_Pressed" 1 "Pressed" ;
VAL_ 533 TrlrHitch_D_RqMnu 0 "NoRequest" 1 "CancelAutohitch" 2 "TurnOnAutohitch" 3 "TurnOnTba" 4 "Confirm" 5 "GoToTraileringDomain" 6 "NotUsed_1" 7 "NotUsed_2" 8 "NotUsed_3" 9 "NotUsed_4" 10 "NotUsed_5" 11 "NotUsed_6" 12 "NotUsed_7" 13 "NotUsed_8" 14 "NotUsed_9" 15 "NotUsed_10" ;
VAL_ 533 OnbChrgGoTOn_D_Rq 0 "Null" 1 "Off" 2 "On" 3 "NotUsed" ;
VAL_ 533 OnbChrgGoTExtHtr_D_Rq 0 "Null" 1 "Off" 2 "On" 3 "NotUsed" ;
VAL_ 533 AutoEpbZoomView_B_Stat 0 "Inactive" 1 "Active" ;
VAL_ 533 OnbChrgGoTPrcond_D_Rq 0 "Off" 1 "Low" 2 "Medium" 3 "High" ;
VAL_ 533 OnbChrgGoTHr_T_Rq 30 "NoDataExists" 31 "Faulty" ;
VAL_ 533 OtaTrg_D_Stat 0 "Null" 1 "NotAccepted" 2 "Accepted" 3 "NotUsed_1" ;
VAL_ 533 OnbChrgGoTTouch_D_Rq 0 "Null" 1 "Off" 2 "On" 3 "NotUsed" ;
VAL_ 533 OnbChrgGoTMnte_D_Rq 0 "Minute_0" 1 "Minute_5" 2 "Minute_10" 3 "Minute_15" 4 "Minute_20" 5 "Minute_25" 6 "Minute_30" 7 "Minute_35" 8 "Minute_40" 9 "Minute_45" 10 "Minute_50" 11 "Minute_55" 12 "NotUsed_1" 13 "NotUsed_2" 14 "NotUsed_3" 15 "NotUsed_4" ;
VAL_ 533 LghtAmbDrvMde_D_Rq 0 "Null" 1 "Manual" 2 "Automatic" 3 "NotUsed" ;
VAL_ 533 TrlrAlarmButtn_B_Stat 0 "Off" 1 "On" ;
VAL_ 533 TjaLcEnbl_D_RqMnu 0 "Null" 1 "Off" 2 "On" 3 "NotUsed" ;
VAL_ 533 ExtLghtRvrseOn_B_Rq 0 "Off" 1 "On" ;
VAL_ 533 ClrExitAsstEnbl_D_RqMnu 0 "Inactive" 1 "Disable" 2 "Enable" 3 "NotUsed" ;
VAL_ 533 DcacPw_D_Rq 0 "Null" 1 "Off" 2 "Low" 3 "High" ;
VAL_ 533 DcacPwReset_B_Rq 0 "Null" 1 "Reset" ;
VAL_ 534 WhlDirRr_D_Actl 0 "Forward" 1 "Backward" 2 "NoDataExists" 3 "Faulty" ;
VAL_ 534 WhlDirFl_D_Actl 0 "Forward" 1 "Backward" 2 "NoDataExists" 3 "Faulty" ;
VAL_ 534 WhlDirFr_D_Actl 0 "Forward" 1 "Backward" 2 "NoDataExists" 3 "Faulty" ;
VAL_ 534 WhlDirRl_D_Actl 0 "Forward" 1 "Backward" 2 "NoDataExists" 3 "Faulty" ;
VAL_ 535 WhlFl_W_Meas 32766 "Unknown" 32767 "Fault" ;
VAL_ 535 WhlFr_W_Meas 32766 "Unknown" 32767 "Fault" ;
VAL_ 535 WhlRl_W_Meas 32766 "Unknown" 32767 "Fault" ;
VAL_ 535 WhlRr_W_Meas 32766 "Unknown" 32767 "Fault" ;
VAL_ 538 MK_ESCRestrictConf_St 0 "Null" 1 "Off" 2 "On" 3 "NotUsed" ;
VAL_ 538 MK_ECalRestrictConf_St 0 "Null" 1 "Off" 2 "On" 3 "NotUsed" ;
VAL_ 538 MK_DNDRestrictConf_St 0 "Null" 1 "Off" 2 "On" 3 "NotUsed" ;
VAL_ 538 MK_AudioLimitConfig_St 0 "Null" 1 "Off" 2 "On" 3 "NotUsed" ;
VAL_ 538 MK_SpeedLimitConf_St 0 "Off" 1 "kmh70" 2 "kmh75" 3 "kmh80" 4 "kmh85" 5 "kmh90" 6 "kmh95" 7 "Kmh100" 8 "Kmh105" 9 "Kmh110" 10 "Kmh115" 11 "Kmh120" 12 "Kmh125" 13 "Kmh130" 14 "Kmh135" 15 "Kmh140" 16 "Kmh145" 17 "Kmh150" 18 "Kmh155" 19 "Kmh160" 20 "Kmh165" 21 "mph40" 22 "mph45" 23 "mph50" 24 "mph55" 25 "mph60" 26 "mph65" 27 "mph70" 28 "mph75" 29 "mph80" 30 "mph85" 31 "mph90" ;
VAL_ 538 MK_SpeedMinderConf_St 0 "Off" 1 "kmh70" 2 "kmh75" 3 "kmh80" 4 "kmh85" 5 "kmh90" 6 "kmh95" 7 "Kmh100" 8 "Kmh105" 9 "Kmh110" 10 "Kmh115" 11 "Kmh120" 12 "Kmh125" 13 "Kmh130" 14 "Kmh135" 15 "Kmh140" 16 "Kmh145" 17 "Kmh150" 18 "Kmh155" 19 "Kmh160" 20 "Kmh165" 21 "mph40" 22 "mph45" 23 "mph50" 24 "mph55" 25 "mph60" 26 "mph65" 27 "mph70" 28 "mph75" 29 "mph80" 30 "mph85" 31 "mph90" ;
VAL_ 539 NfcDevcDetct_D_Stat 0 "Null" 1 "Ext1FlDoorReader" 2 "Ext2FrDoorReader" 3 "Ext3RlDoorReader" 4 "Ext4RrDoorReader" 5 "Ext5DBackEndReader" 6 "Ext6FrontEndReader" 7 "Int1Starting" 8 "Int2Charging" 9 "NotUsed_1" 10 "NotUsed_2" 11 "NotUsed_3" 12 "NotUsed_4" 13 "NotUsed_5" 14 "NotUsed_6" 15 "NotUsed_7" ;
VAL_ 539 NfcDevcPair_D_Stat 0 "Null" 1 "Fail" 2 "Success" 3 "NotUsed_1" ;
VAL_ 539 NfcDevc_D_Stat 0 "Null" 1 "Fail" 2 "Success" 3 "NotUsed_1" ;
VAL_ 539 NfcDevcKeyType_D_Stat 0 "Null" 1 "Factory" 2 "User" 3 "NotUsed_1" ;
VAL_ 539 NfcDevc_D_Cmd 0 "Null" 1 "Add" 2 "Remove" 3 "RemoveAll" 4 "NotUsed_1" 5 "NotUsed_2" 6 "NotUsed_3" 7 "NotUsed_4" ;
VAL_ 539 DgtlKeyType_D_Stat 0 "Null" 1 "Passive" 2 "Active" 3 "NotUsed_1" ;
VAL_ 539 DgtlKeyReset_D_Stat 0 "Null" 1 "Fail" 2 "Success" 3 "NotUsed_1" 4 "NotUsed_2" 5 "NotUsed_3" 6 "NotUsed_4" 7 "NotUsed_5" 8 "NotUsed_6" 9 "NotUsed_7" 10 "NotUsed_8" 11 "NotUsed_9" 12 "NotUsed_10" 13 "NotUsed_11" 14 "NotUsed_12" 15 "NotUsed_13" ;
VAL_ 540 NfcDevcTapPrd_B_Stat 0 "No" 1 "Yes" ;
VAL_ 540 NfcDevcTapDur_D_Stat 0 "Null" 1 "Short" 2 "Long" 3 "NotUsed_1" ;
VAL_ 544 Chime_Time_Criticality 0 "Inactive" 1 "High" 2 "Low" ;
VAL_ 544 Chime_Directionality 0 "Inactive" 1 "ALL" 2 "FrontSpeakers" 3 "RearSpeakers" ;
VAL_ 544 AdjustableChimeVol_Rq 0 "DefaultVolume" 1 "LevelMinus6" 2 "LevelMinus5" 3 "LevelMinus4" 4 "LevelMinus3" 5 "LevelMinus2" 6 "LevelMinus1" 7 "LevelPlus1" 8 "LevelPlus2" 9 "LevelPlus3" 10 "LevelPlus4" 11 "LevelPlus5" 12 "LevelPlus6" 13 "NotUsed_1" 14 "NotUsed_2" 15 "NotUsed_3" ;
VAL_ 544 ChimeId_No_Rq 0 "Inactive" 1 "Id1" 10 "Id10" 20 "Id20" 30 "Id30" 40 "Id40" 50 "Id50" 60 "Id60" 70 "Id70" 80 "Id80" 90 "Id90" 100 "Id100" 120 "Id120" 140 "Id140" 160 "Id160" 180 "Id180" 200 "Id200" 220 "Id220" 240 "Id240" 250 "Id250" 255 "Id255" ;
VAL_ 544 Chime_Occurence 0 "Inactive" 1 "PlayOnce" 2 "2Repititions" 3 "3Repititions" 4 "4Repititions" 5 "5Repititions" 6 "6Repititions" 7 "7Repititions" 8 "8Repititions" 9 "9Repititions" 10 "10Repititions" 11 "11Repititions" 12 "12Repititions" 13 "13Repititions" 14 "14Repititions" 15 "Continuous" ;
VAL_ 545 DSP_MyKeyVolLim_St 0 "Invalid" 1 "Off" 2 "On" ;
VAL_ 545 DSP_BeltminderAudio_St 0 "Invalid" 1 "Off" 2 "On" ;
VAL_ 545 DSP_Sur_Sound_st 0 "Inactive" 1 "Stereo" 2 "Surround" ;
VAL_ 545 DSP_Audio_Volume_Up_St 0 "NoUpdate" 1 "Update" ;
VAL_ 545 DSP_MyKeyVolLimitUp_St 0 "Invalid" 1 "Updated" 2 "NotUpdated" ;
VAL_ 545 DSP_Bezel_Diag_St 0 "Inactive_NOP" 1 "SoftwarePartNumber" 2 "HardwarePartNumber" 3 "CalibrationPartNumber" 4 "SpeakerWalkAround" 5 "NotUsed_1" 6 "NotUsed_2" 7 "NotUsed_3" 8 "NotUsed_4" 9 "NotUsed_5" 10 "NotUsed_6" 11 "NotUsed_7" 12 "NotUsed_8" 13 "NotUsed_9" 14 "NotUsed_10" 15 "NotUsed_11" ;
VAL_ 545 AutoConfigOcc_Rear 0 "Not_Supported" 1 "Supported" ;
VAL_ 545 AutoConfigOcc_AllSeats 0 "Not_Supported" 1 "Supported" ;
VAL_ 545 AutoConfigOcc_Front 0 "Not_Supported" 1 "Supported" ;
VAL_ 545 AutoConfigOcc_Driver 0 "Not_Supported" 1 "Supported" ;
VAL_ 545 SurndSndUpmix2_D_Stat 0 "Inactive" 1 "Stereo" 2 "Surround" 3 "On_Stage" 4 "Audience" ;
VAL_ 545 AudioOccMde_D_Stat 0 "Invalid" 1 "All" 2 "Driver" 3 "Passenger" 4 "Reserved1" 5 "Reserved2" 6 "Reserved3" 7 "FrontSeats" 8 "RearSeats" 9 "Convertible" 10 "Reserved4" 11 "Reserved5" 12 "Reserved6" 13 "Reserved7" 14 "Reserved8" 15 "Reserved9" ;
VAL_ 545 SpkrDgtlCntr_D_Stat 0 "Null" 1 "NotPresent" 2 "Normal" 3 "Faulty" ;
VAL_ 545 SpkrDgtlLeft_D_Stat 0 "Null" 1 "NotPresent" 2 "Normal" 3 "Faulty" ;
VAL_ 545 SpkrDgtlRight_D_Stat 0 "Null" 1 "NotPresent" 2 "Normal" 3 "Faulty" ;
VAL_ 545 SndImmrsnLvl_D_Stat 0 "Inactive" 1 "Level0" 2 "Level1" 3 "Level2" 4 "Level3" 5 "Level4" 6 "Level5" 7 "Level6" 8 "Level7" 9 "Level8" 10 "Level9" 11 "Level10" 12 "Level11" 13 "Level12" 14 "Level13" 15 "Level14" 16 "Level15" 17 "Level16" 18 "Level17" 19 "Level18" 20 "Level19" 21 "Level20" 22 "Level21" 23 "Level22" 24 "Level23" 25 "Level24" 26 "Level25" 27 "Level26" 28 "Level27" 29 "Level28" 30 "Level29" 31 "Level30" 32 "Level31" 33 "Level32" 34 "Level33" 35 "Level34" 36 "Level35" 37 "Level36" 38 "Level37" 39 "Level38" 40 "Level39" 41 "Level40" 42 "Level41" 43 "Level42" 44 "Level43" 45 "Level44" 46 "Level45" 47 "Level46" 48 "Level47" 49 "Level48" 50 "Level49" 51 "Level50" 52 "Level51" 53 "Level52" 54 "Level53" 55 "Level54" 56 "Level55" 57 "Level56" 58 "Level57" 59 "Level58" 60 "Level59" 61 "Level60" 62 "Level61" 63 "Level62" 64 "Level63" 65 "Level64" 66 "Level65" 67 "Level66" 68 "Level67" 69 "Level68" 70 "Level69" 71 "Level70" 72 "Level71" 73 "Level72" 74 "Level73" 75 "Level74" 76 "Level75" 77 "Level76" 78 "Level77" 79 "Level78" 80 "Level79" 81 "Level80" 82 "Level81" 83 "Level82" 84 "Level83" 85 "Level84" 86 "Level85" 87 "Level86" 88 "Level87" 89 "Level88" 90 "Level89" 91 "Level90" 92 "Level91" 93 "Level92" 94 "Level93" 95 "Level94" 96 "Level95" 97 "Level96" 98 "Level97" 99 "Level98" 100 "Level99" 101 "Level100" 102 "Level101" 103 "Level102" 104 "Level103" 105 "Level104" 106 "Level105" 107 "Level106" 108 "Level107" 109 "Level108" 110 "Level109" 111 "Level110" 112 "Level111" 113 "Level112" 114 "Level113" 115 "Level114" 116 "Level115" 117 "Level116" 118 "Level117" 119 "Level118" 120 "Level119" 121 "Level120" 122 "Level121" 123 "Level122" 124 "Level123" 125 "Level124" 126 "Level125" 127 "Level126" 128 "Level127" 129 "NotUsed_1" 130 "NotUsed_2" 131 "NotUsed_3" 132 "NotUsed_4" 133 "NotUsed_5" 134 "NotUsed_6" 135 "NotUsed_7" 136 "NotUsed_8" 137 "NotUsed_9" 138 "NotUsed_10" 139 "NotUsed_11" 140 "NotUsed_12" 141 "NotUsed_13" 142 "NotUsed_14" 143 "NotUsed_15" 144 "NotUsed_16" 145 "NotUsed_17" 146 "NotUsed_18" 147 "NotUsed_19" 148 "NotUsed_20" 149 "NotUsed_21" 150 "NotUsed_22" 151 "NotUsed_23" 152 "NotUsed_24" 153 "NotUsed_25" 154 "NotUsed_26" 155 "NotUsed_27" 156 "NotUsed_28" 157 "NotUsed_29" 158 "NotUsed_30" 159 "NotUsed_31" 160 "NotUsed_32" 161 "NotUsed_33" 162 "NotUsed_34" 163 "NotUsed_35" 164 "NotUsed_36" 165 "NotUsed_37" 166 "NotUsed_38" 167 "NotUsed_39" 168 "NotUsed_40" 169 "NotUsed_41" 170 "NotUsed_42" 171 "NotUsed_43" 172 "NotUsed_44" 173 "NotUsed_45" 174 "NotUsed_46" 175 "NotUsed_47" 176 "NotUsed_48" 177 "NotUsed_49" 178 "NotUsed_50" 179 "NotUsed_51" 180 "NotUsed_52" 181 "NotUsed_53" 182 "NotUsed_54" 183 "NotUsed_55" 184 "NotUsed_56" 185 "NotUsed_57" 186 "NotUsed_58" 187 "NotUsed_59" 188 "NotUsed_60" 189 "NotUsed_61" 190 "NotUsed_62" 191 "NotUsed_63" 192 "NotUsed_64" 193 "NotUsed_65" 194 "NotUsed_66" 195 "NotUsed_67" 196 "NotUsed_68" 197 "NotUsed_69" 198 "NotUsed_70" 199 "NotUsed_71" 200 "NotUsed_72" 201 "NotUsed_73" 202 "NotUsed_74" 203 "NotUsed_75" 204 "NotUsed_76" 205 "NotUsed_77" 206 "NotUsed_78" 207 "NotUsed_79" 208 "NotUsed_80" 209 "NotUsed_81" 210 "NotUsed_82" 211 "NotUsed_83" 212 "NotUsed_84" 213 "NotUsed_85" 214 "NotUsed_86" 215 "NotUsed_87" 216 "NotUsed_88" 217 "NotUsed_89" 218 "NotUsed_90" 219 "NotUsed_91" 220 "NotUsed_92" 221 "NotUsed_93" 222 "NotUsed_94" 223 "NotUsed_95" 224 "NotUsed_96" 225 "NotUsed_97" 226 "NotUsed_98" 227 "NotUsed_99" 228 "NotUsed_100" 229 "NotUsed_101" 230 "NotUsed_102" 231 "NotUsed_103" 232 "NotUsed_104" 233 "NotUsed_105" 234 "NotUsed_106" 235 "NotUsed_107" 236 "NotUsed_108" 237 "NotUsed_109" 238 "NotUsed_110" 239 "NotUsed_111" 240 "NotUsed_112" 241 "NotUsed_113" 242 "NotUsed_114" 243 "NotUsed_115" 244 "NotUsed_116" 245 "NotUsed_117" 246 "NotUsed_118" 247 "NotUsed_119" 248 "NotUsed_120" 249 "NotUsed_121" 250 "NotUsed_122" 251 "NotUsed_123" 252 "NotUsed_124" 253 "NotUsed_125" 254 "NotUsed_126" 255 "NotUsed_127" ;
VAL_ 546 SYNC_Attn_Info_Audio 0 "Inactive" 1 "Attenuation_1" 2 "Attenuation_2" 3 "Attenuation_3" 4 "Attenuation_4" 5 "Attenuation_5" 6 "Attenuation_6" 7 "Unknown" ;
VAL_ 546 Audible_Beep 0 "Inactive" 1 "Active" ;
VAL_ 546 SYNC_New_Attn_Event 0 "Inactive" 1 "Active" ;
VAL_ 546 Alert_Chan 0 "Inactive" 1 "Mute" 2 "Initialize_for_Prompts" ;
VAL_ 546 PrplSnd_D_Rq 0 "Null" 1 "Disabled" 2 "Enabled" 3 "NotUsed" ;
VAL_ 546 Prompt_Directionality 0 "Inactive" 1 "ALL" 2 "FrontSpeakers" 3 "RearSpeakers" ;
VAL_ 547 Chime_Alert_Chan 0 "Inactive" 1 "Mute" 2 "Reserved" ;
VAL_ 547 AHU_Chime_Not_Recognized 0 "Inactive" 1 "Chime_Not_Recognized" ;
VAL_ 547 AHU_Chime2_Not_Recognized 0 "Inactive" 1 "Chime_Not_Recognized" ;
VAL_ 547 AHU_Chime_Supported 0 "Inactive" 1 "Supported" 2 "Not_Supported" 3 "Not_Used" ;
VAL_ 547 Chime_Alert_Chan2 0 "Inactive" 1 "Mute" 2 "Reserved" ;
VAL_ 547 AhuDgtlChime_D_Stat 0 "Inactive" 1 "NotSupported" 2 "Supported" 3 "NotUsed_1" ;
VAL_ 547 AHU_Alert_Channel1 0 "Inactive" 1 "Initialize_for_prompt" 2 "Muted" 3 "Reserved" ;
VAL_ 547 AHU_Chime_Active 0 "Inactive" 1 "NoChime" 2 "Chime_1" 3 "Chime_2" 4 "Chime_3" 63 "Chime_62" ;
VAL_ 547 AHU_AdjChimVolSupp2_St 0 "Inactive" 1 "NotSupported" 2 "Supported" 3 "NotUsed_1" ;
VAL_ 547 AHU_AdjChimeVolSupp_St 0 "Inactive" 1 "NotSupported" 2 "Supported" 3 "NotUsed_1" ;
VAL_ 547 Audio_Amp_St 0 "NoDataExists" 1 "Off" 2 "Partial_Amp" 3 "On" ;
VAL_ 547 AHU_Chime2_Active 0 "Inactive" 1 "NoChime" 2 "Chime_1" 3 "Chime_2" 4 "Chime_3" 63 "Chime_62" ;
VAL_ 547 ChimeId_No_Stat 0 "Inactive" 1 "Id1" 2 "Id2" 3 "Id3" 4 "Id4" 5 "Id5" 6 "Id6" 7 "Id7" 8 "Id8" 9 "Id9" 10 "Id10" 11 "Id11" 12 "Id12" 13 "Id13" 14 "Id14" 15 "Id15" 16 "Id16" 17 "Id17" 18 "Id18" 19 "Id19" 20 "Id20" 21 "Id21" 22 "Id22" 23 "Id23" 24 "Id24" 25 "Id25" 26 "Id26" 27 "Id27" 28 "Id28" 29 "Id29" 30 "Id30" 31 "Id31" 32 "Id32" 33 "Id33" 34 "Id34" 35 "Id35" 36 "Id36" 37 "Id37" 38 "Id38" 39 "Id39" 40 "Id40" 41 "Id41" 42 "Id42" 43 "Id43" 44 "Id44" 45 "Id45" 46 "Id46" 47 "Id47" 48 "Id48" 49 "Id49" 50 "Id50" 51 "Id51" 52 "Id52" 53 "Id53" 54 "Id54" 55 "Id55" 56 "Id56" 57 "Id57" 58 "Id58" 59 "Id59" 60 "Id60" 61 "Id61" 62 "Id62" 63 "Id63" 64 "Id64" 65 "Id65" 66 "Id66" 67 "Id67" 68 "Id68" 69 "Id69" 70 "Id70" 71 "Id71" 72 "Id72" 73 "Id73" 74 "Id74" 75 "Id75" 76 "Id76" 77 "Id77" 78 "Id78" 79 "Id79" 80 "Id80" 81 "Id81" 82 "Id82" 83 "Id83" 84 "Id84" 85 "Id85" 86 "Id86" 87 "Id87" 88 "Id88" 89 "Id89" 90 "Id90" 91 "Id91" 92 "Id92" 93 "Id93" 94 "Id94" 95 "Id95" 96 "Id96" 97 "Id97" 98 "Id98" 99 "Id99" 100 "Id100" 101 "Id101" 102 "Id102" 103 "Id103" 104 "Id104" 105 "Id105" 106 "Id106" 107 "Id107" 108 "Id108" 109 "Id109" 110 "Id110" 111 "Id111" 112 "Id112" 113 "Id113" 114 "Id114" 115 "Id115" 116 "Id116" 117 "Id117" 118 "Id118" 119 "Id119" 120 "Id120" 121 "Id121" 122 "Id122" 123 "Id123" 124 "Id124" 125 "Id125" 126 "Id126" 127 "Id127" 128 "Id128" 129 "Id129" 130 "Id130" 131 "Id131" 132 "Id132" 133 "Id133" 134 "Id134" 135 "Id135" 136 "Id136" 137 "Id137" 138 "Id138" 139 "Id139" 140 "Id140" 141 "Id141" 142 "Id142" 143 "Id143" 144 "Id144" 145 "Id145" 146 "Id146" 147 "Id147" 148 "Id148" 149 "Id149" 150 "Id150" 151 "Id151" 152 "Id152" 153 "Id153" 154 "Id154" 155 "Id155" 156 "Id156" 157 "Id157" 158 "Id158" 159 "Id159" 160 "Id160" 161 "Id161" 162 "Id162" 163 "Id163" 164 "Id164" 165 "Id165" 166 "Id166" 167 "Id167" 168 "Id168" 169 "Id169" 170 "Id170" 171 "Id171" 172 "Id172" 173 "Id173" 174 "Id174" 175 "Id175" 176 "Id176" 177 "Id177" 178 "Id178" 179 "Id179" 180 "Id180" 181 "Id181" 182 "Id182" 183 "Id183" 184 "Id184" 185 "Id185" 186 "Id186" 187 "Id187" 188 "Id188" 189 "Id189" 190 "Id190" 191 "Id191" 192 "Id192" 193 "Id193" 194 "Id194" 195 "Id195" 196 "Id196" 197 "Id197" 198 "Id198" 199 "Id199" 200 "Id200" 201 "Id201" 202 "Id202" 203 "Id203" 204 "Id204" 205 "Id205" 206 "Id206" 207 "Id207" 208 "Id208" 209 "Id209" 210 "Id210" 211 "Id211" 212 "Id212" 213 "Id213" 214 "Id214" 215 "Id215" 216 "Id216" 217 "Id217" 218 "Id218" 219 "Id219" 220 "Id220" 221 "Id221" 222 "Id222" 223 "Id223" 224 "Id224" 225 "Id225" 226 "Id226" 227 "Id227" 228 "Id228" 229 "Id229" 230 "Id230" 231 "Id231" 232 "Id232" 233 "Id233" 234 "Id234" 235 "Id235" 236 "Id236" 237 "Id237" 238 "Id238" 239 "Id239" 240 "Id240" 241 "Id241" 242 "Id242" 243 "Id243" 244 "Id244" 245 "Id245" 246 "Id246" 247 "Id247" 248 "Id248" 249 "Id249" 250 "Id250" 251 "Id251" 252 "Id252" 253 "Id253" 254 "Id254" 255 "Id255" ;
VAL_ 547 Chime2Id_No_Stat 0 "Inactive" 1 "Id1" 2 "Id2" 3 "Id3" 4 "Id4" 5 "Id5" 6 "Id6" 7 "Id7" 8 "Id8" 9 "Id9" 10 "Id10" 11 "Id11" 12 "Id12" 13 "Id13" 14 "Id14" 15 "Id15" 16 "Id16" 17 "Id17" 18 "Id18" 19 "Id19" 20 "Id20" 21 "Id21" 22 "Id22" 23 "Id23" 24 "Id24" 25 "Id25" 26 "Id26" 27 "Id27" 28 "Id28" 29 "Id29" 30 "Id30" 31 "Id31" 32 "Id32" 33 "Id33" 34 "Id34" 35 "Id35" 36 "Id36" 37 "Id37" 38 "Id38" 39 "Id39" 40 "Id40" 41 "Id41" 42 "Id42" 43 "Id43" 44 "Id44" 45 "Id45" 46 "Id46" 47 "Id47" 48 "Id48" 49 "Id49" 50 "Id50" 51 "Id51" 52 "Id52" 53 "Id53" 54 "Id54" 55 "Id55" 56 "Id56" 57 "Id57" 58 "Id58" 59 "Id59" 60 "Id60" 61 "Id61" 62 "Id62" 63 "Id63" 64 "Id64" 65 "Id65" 66 "Id66" 67 "Id67" 68 "Id68" 69 "Id69" 70 "Id70" 71 "Id71" 72 "Id72" 73 "Id73" 74 "Id74" 75 "Id75" 76 "Id76" 77 "Id77" 78 "Id78" 79 "Id79" 80 "Id80" 81 "Id81" 82 "Id82" 83 "Id83" 84 "Id84" 85 "Id85" 86 "Id86" 87 "Id87" 88 "Id88" 89 "Id89" 90 "Id90" 91 "Id91" 92 "Id92" 93 "Id93" 94 "Id94" 95 "Id95" 96 "Id96" 97 "Id97" 98 "Id98" 99 "Id99" 100 "Id100" 101 "Id101" 102 "Id102" 103 "Id103" 104 "Id104" 105 "Id105" 106 "Id106" 107 "Id107" 108 "Id108" 109 "Id109" 110 "Id110" 111 "Id111" 112 "Id112" 113 "Id113" 114 "Id114" 115 "Id115" 116 "Id116" 117 "Id117" 118 "Id118" 119 "Id119" 120 "Id120" 121 "Id121" 122 "Id122" 123 "Id123" 124 "Id124" 125 "Id125" 126 "Id126" 127 "Id127" 128 "Id128" 129 "Id129" 130 "Id130" 131 "Id131" 132 "Id132" 133 "Id133" 134 "Id134" 135 "Id135" 136 "Id136" 137 "Id137" 138 "Id138" 139 "Id139" 140 "Id140" 141 "Id141" 142 "Id142" 143 "Id143" 144 "Id144" 145 "Id145" 146 "Id146" 147 "Id147" 148 "Id148" 149 "Id149" 150 "Id150" 151 "Id151" 152 "Id152" 153 "Id153" 154 "Id154" 155 "Id155" 156 "Id156" 157 "Id157" 158 "Id158" 159 "Id159" 160 "Id160" 161 "Id161" 162 "Id162" 163 "Id163" 164 "Id164" 165 "Id165" 166 "Id166" 167 "Id167" 168 "Id168" 169 "Id169" 170 "Id170" 171 "Id171" 172 "Id172" 173 "Id173" 174 "Id174" 175 "Id175" 176 "Id176" 177 "Id177" 178 "Id178" 179 "Id179" 180 "Id180" 181 "Id181" 182 "Id182" 183 "Id183" 184 "Id184" 185 "Id185" 186 "Id186" 187 "Id187" 188 "Id188" 189 "Id189" 190 "Id190" 191 "Id191" 192 "Id192" 193 "Id193" 194 "Id194" 195 "Id195" 196 "Id196" 197 "Id197" 198 "Id198" 199 "Id199" 200 "Id200" 201 "Id201" 202 "Id202" 203 "Id203" 204 "Id204" 205 "Id205" 206 "Id206" 207 "Id207" 208 "Id208" 209 "Id209" 210 "Id210" 211 "Id211" 212 "Id212" 213 "Id213" 214 "Id214" 215 "Id215" 216 "Id216" 217 "Id217" 218 "Id218" 219 "Id219" 220 "Id220" 221 "Id221" 222 "Id222" 223 "Id223" 224 "Id224" 225 "Id225" 226 "Id226" 227 "Id227" 228 "Id228" 229 "Id229" 230 "Id230" 231 "Id231" 232 "Id232" 233 "Id233" 234 "Id234" 235 "Id235" 236 "Id236" 237 "Id237" 238 "Id238" 239 "Id239" 240 "Id240" 241 "Id241" 242 "Id242" 243 "Id243" 244 "Id244" 245 "Id245" 246 "Id246" 247 "Id247" 248 "Id248" 249 "Id249" 250 "Id250" 251 "Id251" 252 "Id252" 253 "Id253" 254 "Id254" 255 "Id255" ;
VAL_ 548 DspDgtlChime_D_Stat 0 "Inactive" 1 "NotSupported" 2 "Supported" 3 "NotUsed_1" ;
VAL_ 548 DSP_Chimes_Supported 0 "Inactive" 1 "Supported" 2 "Not_Supported" 3 "Not_Used" ;
VAL_ 548 DSP_Alert_Channel1 0 "Inactive" 1 "Reserved" 2 "Muted" 3 "Initialized_for_chimes" ;
VAL_ 548 DSP_Alert_Channel2 0 "Inactive" 1 "Reserved" 2 "Muted" 3 "Initialized_for_chimes" ;
VAL_ 548 DSP_Chime2_Not_Recgnizd 0 "Inactive" 1 "Chime_Not_Recognized" ;
VAL_ 548 DSP_Chime_Not_Recgnizd 0 "Inactive" 1 "Chime_Not_Recognized" ;
VAL_ 548 DSP_Alert_Channel3 0 "Inactive" 1 "Initialized_for_Prompts" 2 "Muted" 3 "Reserved" ;
VAL_ 548 DSP_AdjChimVolSupp_St 0 "Inactive" 1 "NotSupported" 2 "Supported" 3 "NotUsed_1" ;
VAL_ 548 DSP_AdjChimVolSupp2_St 0 "Inactive" 1 "NotSupported" 2 "Supported" 3 "NotUsed_1" ;
VAL_ 548 DSP_AHU_ChmTstTone_Rq 0 "Inactive" 1 "Active" ;
VAL_ 548 DSP_ChimeChanState_St 0 "Invalid" 1 "Muted" 2 "Ready" 3 "Busy" 4 "Reserved" 5 "Reserved2" 6 "Reserved3" 7 "Reserved4" ;
VAL_ 548 DSP_AHU_ChmTstT 0 "KeyOut" 1 "KeyRecentlyOut" 2 "KeyApproved_0" 3 "PostAccessory_0" 4 "Accessory_1" 5 "PostIgnition_1" 6 "IgnitionOn_2" 7 "Running_2" 8 "NotUsed" 9 "Crank_3" 10 "NotUsed_1" 11 "NotUsed_2" 12 "NotUsed_3" 13 "NotUsed_4" 14 "NotUsed_5" 15 "NotUsed_6" 16 "NotUsed_7" 17 "NotUsed_8" 18 "NotUsed_9" 19 "NotUsed_10" 20 "NotUsed_11" 21 "NotUsed_12" 22 "NotUsed_13" 23 "NotUsed_14" 24 "NotUsed_15" 25 "NotUsed_16" 26 "NotUsed_17" 27 "NotUsed_18" 28 "NotUsed_19" 29 "NotUsed_20" 30 "NotUsed_21" 31 "NotUsed_22" ;
VAL_ 549 IPC_New_Attn_Event 0 "Inactive" 1 "Active" ;
VAL_ 549 HudBrightMnuOn_B_Rq 0 "No" 1 "Yes" ;
VAL_ 549 IPC_Attn_Info_Audio 0 "No_Attenuation_of_Audio" 1 "Attenuation_1" 2 "Attenuation_2" 3 "Attenuation_3" 4 "Attenuation_4" 5 "Attenuation_5" 6 "Attenuation_6" 7 "Unknown" ;
VAL_ 549 BeltminderAudioMute 0 "Invalid" 1 "Off" 2 "On" ;
VAL_ 549 MetricActv_B_Dsply 0 "Inactive" 1 "Active" ;
VAL_ 549 IPC_MyKeyVolLimit_St 0 "Invalid" 1 "Off" 2 "On" ;
VAL_ 549 HudVertMnuOn_B_Rq 0 "No" 1 "Yes" ;
VAL_ 549 SpeedChngChime_D_Rq2 0 "Null" 1 "Off" 2 "On" 3 "NotUsed" ;
VAL_ 549 Chime_Source 0 "Invalid" 1 "Infotainment_Sys" 2 "Cluster" ;
VAL_ 549 StrtInGearOk_D_Stat 0 "Null" 1 "NotAccepted" 2 "Accepted" 3 "NotUsed" ;
VAL_ 549 FactoryReset_Rq2 0 "Inactive" 1 "ResetFactoryDefaults" ;
VAL_ 549 HdcOn_B_Rq 0 "Off" 1 "On" ;
VAL_ 549 HudCntntMnuOn_B_Rq 0 "Off" 1 "On" ;
VAL_ 549 HudVertSzMnuOn_B_Rq 0 "Off" 1 "On" ;
VAL_ 549 HudRotatMnuOn_B_Rq 0 "No" 1 "Yes" ;
VAL_ 549 Power_Up_Chime_Modules 0 "Inactive" 1 "Active" ;
VAL_ 549 WndwCabnMde_D_Rq2 0 "Inactive" 1 "Off" 2 "On" 3 "NotUsed" ;
VAL_ 549 HazrdLghtMde_D_Rq2 0 "Inactive" 1 "Off" 2 "On" 3 "NotUsed" ;
VAL_ 549 DelvrAsstLckMde_D_Rq2 0 "Inactive" 1 "Off" 2 "On" 3 "NotUsed" ;
VAL_ 549 DelvrAsstButtn_D_Rq2 0 "Inactive" 1 "OnDemand" 2 "MultipleStops" 3 "NotUsed_1" ;
VAL_ 549 TjaLcEnbl_D_DrvRq 0 "Inactive" 1 "Off" 2 "On" 3 "NotUsed" ;
VAL_ 549 CCOI_PolicyClient_St2 0 "Null" 1 "Waiting" 2 "OnBoardUpdatePending" 3 "OffBoardUpdatePending" 4 "OnBoardSyncNeeded" 5 "OnBoardSynchronizing" 6 "OnBoardSynchronized" 7 "OnBoardImplemented" 8 "OnBoardSyncFailed" 9 "UnrecoverableSyncError" 10 "StateMachineInconsistent" 11 "DataStorageError" 12 "NotUsed_1" 13 "NotUsed_2" 14 "NotUsed_3" 15 "NotUsed_4" ;
VAL_ 549 WwaActv_B_Stat 0 "Inactive" 1 "Active" ;
VAL_ 549 BattTracLoThres_D_Rq2 0 "Null" 1 "Thres20mi_32km" 2 "Thres30mi_48km" 3 "Thres50mi_80km" 4 "Thres30km_18mi" 5 "Thres50km_31mi" 6 "Thres80km_50mi" 7 "NotUsed" ;
VAL_ 549 NavIod_D_Rq 0 "NoRequest" 1 "VideoOutput" 2 "ModeChange" 3 "NotUsed_1" 4 "NotUsed_2" 5 "NotUsed_3" 6 "NotUsed_4" 7 "NotUsed_5" ;
VAL_ 551 PrkBrkPerfMnuOn_D_Stat 0 "Off" 1 "On" 2 "NotUsed" 3 "Faulty" ;
VAL_ 551 PrkBrkPerfButtn_D_Stat 0 "Not_Pressed" 1 "Pressed" 2 "NotUsed" 3 "Faulty" ;
VAL_ 551 TjaLaneBiasEnbl_D_RqMnu 0 "Null" 1 "Disabled" 2 "Enabled" 3 "NotUsed" ;
VAL_ 551 EcoIdl_D_Rq 0 "Null" 1 "Disabled" 2 "Enabled" 3 "NotUsed" ;
VAL_ 551 VehPerfDemo_B_RqDrv 0 "Off" 1 "On" ;
VAL_ 551 PrcondEdit_D_RqMnu 0 "Null" 1 "Off" 2 "Low" 3 "Medium" 4 "High" 5 "NotUsed_1" 6 "NotUsed_2" 7 "NotUsed_3" ;
VAL_ 551 SelDrvMdeDsply_B_Avai2 0 "NotAvailable" 1 "Available" ;
VAL_ 551 ChrgToPcEdit_Pc_RqMnu 126 "NoDataExists" 127 "Faulty" ;
VAL_ 551 PwRnngBoardT_D_Rq 0 "Inactive" 1 "Timer1" 2 "Timer2" 3 "NotUsed" ;
VAL_ 551 PwRnngBoardSwtch_D_Rq 0 "Inactive" 1 "AlwaysActive" 2 "DeployUnlocked" 3 "NotUsed" ;
VAL_ 551 PwRnngBoardMde_D_Rq 0 "Inactive" 1 "Off" 2 "Out" 3 "Auto" ;
VAL_ 551 Rba_D_Rq 0 "Null" 1 "Off" 2 "On" 3 "NotUsed" ;
VAL_ 551 EmPrflButtnAssoc_D_Rq 0 "Null" 1 "EnterButtonAssociation" 2 "ExitButtonAssociation" 3 "NotUsed" ;
VAL_ 551 PmCabnLvl_D_Stat 0 "NotKnown" 1 "Level_1_Best" 2 "Level_2" 3 "Level_3" 4 "Level_4" 5 "Level_5" 6 "Level_6_Worst" 7 "NotUsed_1" ;
VAL_ 551 PmCabn_D_Stat 0 "NotKnown" 1 "FilteringOff" 2 "FilteringOn" 3 "FilteringComplete" ;
VAL_ 551 Cntr_Plg_Mode_Cmd 0 "Disable" 1 "Enable" ;
VAL_ 551 OneTEditActv_B_RqMnu 0 "No" 1 "Yes" ;
VAL_ 551 BattTracLoThres_D_Rq 0 "Null" 1 "Thres20mi_32km" 2 "Thres30mi_48km" 3 "Thres50mi_80km" 4 "Thres30km_18mi" 5 "Thres50km_31mi" 6 "Thres80km_50mi" 7 "NotUsed" ;
VAL_ 551 EmPrflKeyAssoc_D_Rq 0 "Null" 1 "EnterKeyAssociation" 2 "ExitKeyAssociation" 3 "DisassociateKey" 4 "OverwriteKey" 5 "EnterPhoneAssociation" 6 "DisassociatePhone" 7 "NotUsed_3" ;
VAL_ 551 ChrgCrdLckEnbl_B_Stat 0 "Disable" 1 "Enable" ;
VAL_ 551 WndwChildLckPw_B_RqMnu 0 "Unlock" 1 "Lock" ;
VAL_ 551 Btt_L_Actl2 126 "NoDataExists" 127 "Faulty" ;
VAL_ 551 BecConfg_B_RqMnu 0 "Disable" 1 "Enable" ;
VAL_ 551 ChrgOvrdExitScrn_D_Rq 0 "Inactive" 1 "Do_not_request_override" 2 "Request_override" 3 "NotUsed_1" ;
VAL_ 551 EmPrflNo_D_Rq 0 "Null" 1 "Pers1" 2 "Pers2" 3 "Pers3" 4 "Pers4" 5 "NotUsed_1" 6 "NotUsed_2" 7 "NotUsed_3" ;
VAL_ 551 Em_D_Stat 0 "Null" 1 "ProfilesOn" 2 "ProfilesOff" 3 "NotSupported" ;
VAL_ 552 Audio_Demo_Status 0 "Inactive" 1 "Active" ;
VAL_ 552 DSP_Shaker_St 0 "Inactive" 1 "Active" ;
VAL_ 552 DSP_NavCmdVolume_Up 0 "NoUpdate" 1 "Update" ;
VAL_ 552 DSP_DSPProgram_St 0 "Invalid" 1 "Normal" 2 "Pop" 3 "Classical" 4 "Rock" 5 "Voice" 6 "Reserved1" 7 "Reserved2" ;
VAL_ 552 DSP_DSP_St 0 "Invalid" 1 "All" 2 "Driver" 3 "Passenger" 4 "Pop" 5 "Classical" 6 "Rock" ;
VAL_ 552 DSP_PhoneVolume_Up 0 "NoUpdate" 1 "Update" ;
VAL_ 552 DSP_Reg_St 0 "Invalid" 1 "Off" 2 "On" ;
VAL_ 552 DSP_TAVolume_Up 0 "NoUpdate" 1 "Update" ;
VAL_ 552 DSP_VoiceFBVolume_Up 0 "NoUpdate" 1 "Update" ;
VAL_ 552 ActvNseMute_D_Stat 0 "Inactive" 1 "NotMuted" 2 "Muted" 3 "NotUsed_1" ;
VAL_ 553 ResetTrip2_B_Rq 0 "Null" 1 "Reset" ;
VAL_ 553 ResetTrip1_B_Rq 0 "Null" 1 "Reset" ;
VAL_ 553 Audio_Demo_CMND 0 "Inactive" 1 "Off" 2 "On" ;
VAL_ 553 Audio_Visualizer 0 "Inactive" 1 "Off" 2 "On" ;
VAL_ 553 Surround_Sound_Upmix 0 "Inactive" 1 "Stereo" 2 "Surround" ;
VAL_ 553 CCOI_PolicyClient_St 0 "Null" 1 "Waiting" 2 "OnBoardUpdatePending" 3 "OffBoardUpdatePending" 4 "OnBoardSyncNeeded" 5 "OnBoardSynchronizing" 6 "OnBoardSynchronized" 7 "OnBoardImplemented" 8 "OnBoardSyncFailed" 9 "UnrecoverableSyncError" 10 "StateMachineInconsistent" 11 "DataStorageError" 12 "NotUsed_1" 13 "NotUsed_2" 14 "NotUsed_3" 15 "NotUsed_4" ;
VAL_ 553 Bezel_Diag_Module_Rq 0 "Inactive" 1 "AHU" 2 "DSP_AMP" 3 "EFP" 15 "Reserved" ;
VAL_ 553 Disp_LangSel_St 0 "Invalid" 1 "Unknown" 2 "UK_English" 3 "NA_English" 4 "German" 5 "Italian" 6 "EU_French" 7 "Cana_French" 8 "EU_Spanish" 9 "Mex_Spanish" 10 "Turkish" 11 "Russian" 12 "Dutch" 13 "Flemish" 14 "Polish" 15 "Czech" 16 "Greek" 17 "Hungarian" 18 "Swedish" 19 "Danish" 20 "Norwegian" 21 "Finish" 22 "EU_Portuguese" 23 "Braz_Portuguese" 24 "Japanese" 25 "AU_English" 26 "Korean" 27 "Mandarin_Chinese" 28 "Taiwanese" 29 "Arabic" 30 "Slovak" 31 "Thai" ;
VAL_ 553 ResetAvgFe_B_Rq 0 "Null" 1 "Reset" ;
VAL_ 553 Bezel_Diag_State_Rq 0 "Inactive" 1 "Active" ;
VAL_ 553 SurndSndUpmix2_D_Rq 0 "Inactive" 1 "Stereo" 2 "Surround" 3 "On_Stage" 4 "Audience" ;
VAL_ 553 Diagnostic_Operation_Rq 0 "Inactive" 1 "GetAllBackgroundDiagRq" 2 "SoftwarePartNumber" 3 "HardwarePartNumber" 4 "CalibrationPartNumber" 5 "SpeakerWalkAround" 6 "SDARSESNNumber" 7 "SignalStrength" 15 "Reserved" ;
VAL_ 553 Disp_LangSel2_St 0 "Invalid" 1 "Unknown" 2 "UK_English" 3 "NA_English" 4 "German" 5 "Italian" 6 "EU_French" 7 "Cana_French" 8 "EU_Spanish" 9 "Mex_Spanish" 10 "Turkish" 11 "Russian" 12 "Dutch" 13 "Flemish" 14 "Polish" 15 "Czech" 16 "Greek" 17 "Hungarian" 18 "Swedish" 19 "Danish" 20 "Norwegian" 21 "Finish" 22 "EU_Portuguese" 23 "Braz_Portuguese" 24 "Japanese" 25 "AU_English" 26 "Korean" 27 "Mandarin_Chinese" 28 "Taiwanese" 29 "Arabic" 30 "Slovak" 31 "Thai" 32 "Indian_English" 33 "Ukrainian" 34 "Romanian" ;
VAL_ 553 SndImmrsnLvl_D_Rq 0 "Inactive" 1 "Level0" 2 "Level1" 3 "Level2" 4 "Level3" 5 "Level4" 6 "Level5" 7 "Level6" 8 "Level7" 9 "Level8" 10 "Level9" 11 "Level10" 12 "Level11" 13 "Level12" 14 "Level13" 15 "Level14" 16 "Level15" 17 "Level16" 18 "Level17" 19 "Level18" 20 "Level19" 21 "Level20" 22 "Level21" 23 "Level22" 24 "Level23" 25 "Level24" 26 "Level25" 27 "Level26" 28 "Level27" 29 "Level28" 30 "Level29" 31 "Level30" 32 "Level31" 33 "Level32" 34 "Level33" 35 "Level34" 36 "Level35" 37 "Level36" 38 "Level37" 39 "Level38" 40 "Level39" 41 "Level40" 42 "Level41" 43 "Level42" 44 "Level43" 45 "Level44" 46 "Level45" 47 "Level46" 48 "Level47" 49 "Level48" 50 "Level49" 51 "Level50" 52 "Level51" 53 "Level52" 54 "Level53" 55 "Level54" 56 "Level55" 57 "Level56" 58 "Level57" 59 "Level58" 60 "Level59" 61 "Level60" 62 "Level61" 63 "Level62" 64 "Level63" 65 "Level64" 66 "Level65" 67 "Level66" 68 "Level67" 69 "Level68" 70 "Level69" 71 "Level70" 72 "Level71" 73 "Level72" 74 "Level73" 75 "Level74" 76 "Level75" 77 "Level76" 78 "Level77" 79 "Level78" 80 "Level79" 81 "Level80" 82 "Level81" 83 "Level82" 84 "Level83" 85 "Level84" 86 "Level85" 87 "Level86" 88 "Level87" 89 "Level88" 90 "Level89" 91 "Level90" 92 "Level91" 93 "Level92" 94 "Level93" 95 "Level94" 96 "Level95" 97 "Level96" 98 "Level97" 99 "Level98" 100 "Level99" 101 "Level100" 102 "Level101" 103 "Level102" 104 "Level103" 105 "Level104" 106 "Level105" 107 "Level106" 108 "Level107" 109 "Level108" 110 "Level109" 111 "Level110" 112 "Level111" 113 "Level112" 114 "Level113" 115 "Level114" 116 "Level115" 117 "Level116" 118 "Level117" 119 "Level118" 120 "Level119" 121 "Level120" 122 "Level121" 123 "Level122" 124 "Level123" 125 "Level124" 126 "Level125" 127 "Level126" 128 "Level127" 129 "NotUsed_1" 130 "NotUsed_2" 131 "NotUsed_3" 132 "NotUsed_4" 133 "NotUsed_5" 134 "NotUsed_6" 135 "NotUsed_7" 136 "NotUsed_8" 137 "NotUsed_9" 138 "NotUsed_10" 139 "NotUsed_11" 140 "NotUsed_12" 141 "NotUsed_13" 142 "NotUsed_14" 143 "NotUsed_15" 144 "NotUsed_16" 145 "NotUsed_17" 146 "NotUsed_18" 147 "NotUsed_19" 148 "NotUsed_20" 149 "NotUsed_21" 150 "NotUsed_22" 151 "NotUsed_23" 152 "NotUsed_24" 153 "NotUsed_25" 154 "NotUsed_26" 155 "NotUsed_27" 156 "NotUsed_28" 157 "NotUsed_29" 158 "NotUsed_30" 159 "NotUsed_31" 160 "NotUsed_32" 161 "NotUsed_33" 162 "NotUsed_34" 163 "NotUsed_35" 164 "NotUsed_36" 165 "NotUsed_37" 166 "NotUsed_38" 167 "NotUsed_39" 168 "NotUsed_40" 169 "NotUsed_41" 170 "NotUsed_42" 171 "NotUsed_43" 172 "NotUsed_44" 173 "NotUsed_45" 174 "NotUsed_46" 175 "NotUsed_47" 176 "NotUsed_48" 177 "NotUsed_49" 178 "NotUsed_50" 179 "NotUsed_51" 180 "NotUsed_52" 181 "NotUsed_53" 182 "NotUsed_54" 183 "NotUsed_55" 184 "NotUsed_56" 185 "NotUsed_57" 186 "NotUsed_58" 187 "NotUsed_59" 188 "NotUsed_60" 189 "NotUsed_61" 190 "NotUsed_62" 191 "NotUsed_63" 192 "NotUsed_64" 193 "NotUsed_65" 194 "NotUsed_66" 195 "NotUsed_67" 196 "NotUsed_68" 197 "NotUsed_69" 198 "NotUsed_70" 199 "NotUsed_71" 200 "NotUsed_72" 201 "NotUsed_73" 202 "NotUsed_74" 203 "NotUsed_75" 204 "NotUsed_76" 205 "NotUsed_77" 206 "NotUsed_78" 207 "NotUsed_79" 208 "NotUsed_80" 209 "NotUsed_81" 210 "NotUsed_82" 211 "NotUsed_83" 212 "NotUsed_84" 213 "NotUsed_85" 214 "NotUsed_86" 215 "NotUsed_87" 216 "NotUsed_88" 217 "NotUsed_89" 218 "NotUsed_90" 219 "NotUsed_91" 220 "NotUsed_92" 221 "NotUsed_93" 222 "NotUsed_94" 223 "NotUsed_95" 224 "NotUsed_96" 225 "NotUsed_97" 226 "NotUsed_98" 227 "NotUsed_99" 228 "NotUsed_100" 229 "NotUsed_101" 230 "NotUsed_102" 231 "NotUsed_103" 232 "NotUsed_104" 233 "NotUsed_105" 234 "NotUsed_106" 235 "NotUsed_107" 236 "NotUsed_108" 237 "NotUsed_109" 238 "NotUsed_110" 239 "NotUsed_111" 240 "NotUsed_112" 241 "NotUsed_113" 242 "NotUsed_114" 243 "NotUsed_115" 244 "NotUsed_116" 245 "NotUsed_117" 246 "NotUsed_118" 247 "NotUsed_119" 248 "NotUsed_120" 249 "NotUsed_121" 250 "NotUsed_122" 251 "NotUsed_123" 252 "NotUsed_124" 253 "NotUsed_125" 254 "NotUsed_126" 255 "NotUsed_127" ;
VAL_ 553 DistToChrgrBynd_L_Actl 510 "NoDataExists" 511 "Faulty" ;
VAL_ 553 InfoSysMasterPw_D_Stat 0 "Inactive" 1 "On" 2 "On_with_screen" 3 "NotUsed_1" 4 "NotUsed_2" 5 "NotUsed_3" 6 "NotUsed_4" 7 "NotUsed_5" ;
VAL_ 554 SeatOccRearMsgTxt_B_Rq 0 "Null" 1 "Active" ;
VAL_ 554 DrvHazrdModel_D_St 0 "None" 1 "DenmEm" 2 "TpegTec" 3 "NotUsed_1" 4 "NotUsed_2" 5 "NotUsed_3" 6 "NotUsed_4" 7 "NotUsed_5" 8 "NotUsed_6" 9 "NotUsed_7" 10 "NotUsed_8" 11 "NotUsed_9" 12 "NotUsed_10" 13 "NotUsed_11" 14 "NotUsed_12" 15 "NotUsed_13" ;
VAL_ 554 DrvHazrd_D_St 0 "NoStatus" 1 "bSAllowOff" 2 "bAllowOff" 3 "NoSession" 4 "NoService" 5 "Available" 6 "Suspended" 7 "NotUsed_1" ;
VAL_ 554 Drv_Set_Tmp2 0 "No_Request" 1 "LO" 2 "15_5" 3 "16_0" 4 "16_5" 5 "17_0" 6 "17_5" 7 "18_0" 8 "18_5" 9 "19_0" 10 "19_5" 11 "20_0" 12 "20_5" 13 "21_0" 14 "21_5" 15 "22_0" 16 "22_5" 17 "23_0" 18 "23_5" 19 "24_0" 20 "24_5" 21 "25_0" 22 "25_5" 23 "26_0" 24 "26_5" 25 "27_0" 26 "27_5" 27 "28_0" 28 "28_5" 29 "29_0" 30 "29_5" 31 "HI" ;
VAL_ 554 Frt_Btn_Status_1st_2 0 "None_Pressed" 1 "Panel_Pressed" 2 "Panel_Floor_Pressed" 3 "Floor_Pressed" 4 "Floor_Ws_Pressed" 5 "AC_Pressed" 6 "Dual_Pressed" 7 "LHS_Temp_Inc_Pressed" 8 "LHS_Temp_Dec_Pressed" 9 "RHS_Temp_Inc_Pressed" 10 "RHS_Temp_Dec_Pressed" 11 "Blwr_Inc_Pressed" 12 "Blwr_Dec_Pressed" 13 "AUTO_Pressed" 14 "Max_AC_Pressed" 15 "Recirc_Pressed" 16 "Outside_Pressed" 17 "Auto_Recirc_Pressed" 18 "Htd_Frt_Wsh_Pressed" 19 "Windscreen_Pressed" 20 "Pnl_Ws_Pressed" 21 "Pnl_Flr_Ws_Pressed" 22 "Rear_Defrost_Pressed" 23 "Front_Defrost_Pressed" 24 "My_Temp_Pressed" 25 "Max_Defrost_Pressed" 26 "LHS_Htd_Seat_Pressed" 27 "RHS_Htd_Seat_Pressed" 28 "LHS_Cld_Seat_Pressed" 29 "RHS_Cld_Seat_Pressed" 30 "Htd_Strg_Whl_Pressed" 31 "Defrost_Pressed" 32 "FrontMnu_Pressed" 33 "RearMnu_Pressed" 34 "Heat_Pressed" 35 "AAR_Pressed" 36 "MdeMnu_Pressed" 37 "DrvrFcsdMde_Pressed" 38 "LHS_Seat_Off_Pressed" 39 "LHS_Htd_Seat1_Pressed" 40 "LHS_Htd_Seat2_Pressed" 41 "LHS_Htd_Seat3_Pressed" 42 "LHS_Auto_Seat_Pressed" 43 "RHS_Seat_Off_Pressed" 44 "RHS_Htd_Seat1_Pressed" 45 "RHS_Htd_Seat2_Pressed" 46 "RHS_Htd_Seat3_Pressed" 47 "RHS_Auto_Seat_Pressed" 48 "LHS_Cld_Seat1_Pressed" 49 "LHS_Cld_Seat2_Pressed" 50 "LHS_Cld_Seat3_Pressed" 51 "RHS_Cld_Seat1_Pressed" 52 "RHS_Cld_Seat2_Pressed" 53 "RHS_Cld_Seat3_Pressed" 54 "AUTO_Lo_Pressed" 55 "AUTO_Med_Pressed" 56 "AUTO_Hi_Pressed" 57 "AUTO_Inc_Pressed" 58 "AUTO_Dec_Pressed" 59 "NotUsed_1" 60 "NotUsed_2" 61 "NotUsed_3" 62 "NotUsed_4" 63 "NotUsed_5" ;
VAL_ 554 PtWakeupActv1_B_Rq 0 "Don_t_Wake_Up_Powertrain" 1 "Wake_up_Powertrain_via_HW" ;
VAL_ 554 AudioPersSrvc_D_Rq 0 "Null" 1 "Query" 2 "Set" 3 "Upload" 4 "Restore" 5 "Copy" 6 "NotUsed_1" 7 "NotUsed_2" ;
VAL_ 554 AudioPersIndx_D_Rq 0 "Pers_1" 1 "Pers_2" 2 "Pers_3" 3 "Pers_4" 4 "Vehicle" 5 "NotUsed_1" 6 "NotUsed_2" 7 "NotUsed_3" ;
VAL_ 555 HudActv_D_Stat 0 "NoData" 1 "Inactive" 2 "Pending" 3 "Active" 4 "Error" 5 "NotUsed_1" 6 "NotUsed_2" 7 "Faulty" ;
VAL_ 555 HudTestMdeActv_B_Stat 0 "Inactive" 1 "Active" ;
VAL_ 555 HudHzntlMnuOn_B_Stat 0 "No" 1 "Yes" ;
VAL_ 555 HudRotatMnuOn_B_Stat 0 "No" 1 "Yes" ;
VAL_ 555 HudVertMnuOn_B_Stat 0 "No" 1 "Yes" ;
VAL_ 555 HudBrightMnuOn_B_Stat 0 "No" 1 "Yes" ;
VAL_ 555 HudSwtch_B_Stat 0 "Not_Pressed" 1 "Pressed" ;
VAL_ 555 HudVertSzMnuOn_B_Stat 0 "Off" 1 "On" ;
VAL_ 555 HudMsgTxt_D_Rq 0 "NoMessage" 1 "Message1" 2 "Message2" 3 "Message3" 4 "Message4" 5 "Message5" 6 "Message6" 7 "Message7" ;
VAL_ 556 PassRstrnInd_Stat 0 "Not_Supported" 1 "Normal" 2 "AirbagOn_Indicator_fault" 3 "AirbagOff_Indicator_fault" 4 "Both_Indicators_Faulted" 5 "Unused_1" 6 "Unused_2" 7 "Invalid" ;
VAL_ 556 DrvAsstMnuButtn_B_Stat 0 "Not_Pressed" 1 "Pressed" ;
VAL_ 556 Bezel_Beeps_Supported 0 "Invalid" 1 "Supported" 2 "Not_Supported" ;
VAL_ 556 Bezel_Beep_St 0 "Invalid" 1 "Enabled" 2 "Disabled" ;
VAL_ 556 EFP_Bezel_Diag_St 0 "Inactive_NOP" 1 "SoftwarePartNumber" 2 "HardwarePartNumber" 3 "CalibrationPartNumber" 15 "Reserved" ;
VAL_ 556 Manual_Temp_Setting 0 "Off" 1 "Full_Cool" 2 "Setting_2" 3 "Setting_3" 4 "Setting_4" 5 "Setting_5" 6 "Setting_6" 7 "Setting_7" 8 "Setting_8" 9 "Setting_9" 10 "Setting_10" 11 "Setting_11" 12 "Setting_12" 13 "Setting_13" 14 "Setting_14" 15 "Setting_15" 16 "Setting_16" 17 "Setting_17" 18 "Setting_18" 19 "Setting_19" 20 "Setting_20" 21 "Setting_21" 22 "Setting_22" 23 "Setting_23" 24 "Setting_24" 25 "Setting_25" 26 "Setting_26" 27 "Setting_27" 28 "Setting_28" 29 "Setting_29" 30 "Setting_30" 31 "Full_Heat" ;
VAL_ 557 AudioToneTouchX_D_Stat 0 "Null" 1 "Value0" 2 "Value1_up_to_0xFE_Value253" 255 "Value254" ;
VAL_ 557 AudioToneTouchY_D_Stat 0 "Null" 1 "Value0" 2 "Value1_up_to_0xFE_Value253" 255 "Value254" ;
VAL_ 557 AudioPersSrvc_D_Res 0 "Null" 1 "Success" 2 "Pending" 3 "Rejected" 4 "Interrupted" 5 "Failed" 6 "In_Prog" 7 "Invalid" 8 "NotUsed_1" 9 "NotUsed_2" 10 "NotUsed_3" 11 "NotUsed_4" 12 "NotUsed_5" 13 "NotUsed_6" 14 "NotUsed_7" 15 "Faulty" ;
VAL_ 557 AudioPersChng_D_Stat 0 "Null" 1 "Profile_Updated" 2 "Data_Lost" 3 "NotUsed_1" ;
VAL_ 557 AudioToneTouch_D_Stat 0 "Null" 1 "Disabled" 2 "Enabled" 3 "NotUsed" ;
VAL_ 560 TrnShifActv_B_Actl 0 "Inactive" 1 "Active" ;
VAL_ 560 TrnSrvcRqd_B_Rq 0 "Off" 1 "On" ;
VAL_ 560 GearLvrPos_D_Actl 0 "Park" 1 "Reverse" 2 "Neutral" 3 "Drive" 4 "Sport_DriveSport" 5 "Low" 6 "first" 7 "second" 8 "third" 9 "fourth" 10 "fifth" 11 "sixth" 12 "Undefined_Treat_as_Fault" 13 "Undefined_Treat_as__Fault" 14 "Unknown_Position" 15 "Fault" ;
VAL_ 560 BtsiShifInhbt_B_RqTrn 0 "No" 1 "Yes" ;
VAL_ 560 SelDrvMdeSwtch_D_Stat3 0 "NotPressed" 1 "SwitchState1" 2 "SwitchState2" 3 "Faulty" ;
VAL_ 560 CleanerHeater_D_Stat 0 "Inactive" 1 "Heat" 2 "Maintain" 3 "Success" ;
VAL_ 560 GboxOil_Te_Actl 254 "NoDataExists" 255 "Faulty" ;
VAL_ 560 TrnGbox_Rt_Actl 65534 "Unknown" 65535 "Fault" ;
VAL_ 560 RtmTerrMdeChng_D_Rdy 0 "Mode_Change_Available" 1 "Module_In_Initialization" 2 "ModeUnavailDynamicCond" 3 "SpOpModes_NotSupported" 4 "ModeUnavailDrInputRqd" 5 "Undefined_1" 6 "Undefined_2" 7 "Fault" ;
VAL_ 560 RtmTerrMde_D_Actl 0 "Special_Operating_Mode_Off" 1 "Low_Mu_Mode" 2 "Undefined" 3 "Sand_Mode" 4 "Mud_Ruts_Mode" 5 "Rock_Crawl_Mode" 6 "Dynamic_Mode" 7 "Fail_Safe_Default" ;
VAL_ 560 TrnCnvtClu_D_Actl 0 "No_Lock_Up" 1 "Lock_Up_Slip" 2 "Lock_Up_Fixed" 3 "Transition_or_Micro_Slip" ;
VAL_ 561 TrnMsgTxt_D_Rq 0 "NoMessage" 1 "Message_1" 2 "Message_2" 3 "Message_3" 4 "Message_4" 5 "Message_5" 6 "Message_6" 7 "Message_7" 8 "Message_8" 9 "Message_9" 10 "Message_10" 11 "Message_11" 12 "Message_12" 13 "Message_13" 14 "Message_14" 15 "Message_15" ;
VAL_ 561 TrnMsgTxt2_D_Rq 0 "NoText_NoChime" 1 "PressBrake_NoChime" 2 "PressBrake_SoftChime" 3 "PressBrake_LoudChime" 4 "TransTooHot_LoudChime" 5 "NotUsed1" 6 "NotUsed2" 7 "NotUsed3" ;
VAL_ 563 OfbChrgSetSync_D_Rq 0 "NoSyncInProgress" 1 "InProgress" 2 "Success" 3 "Fail" ;
VAL_ 563 ModemReset_D_Stat 0 "Null" 1 "ResetNotComplete" 2 "PaakResetComplete" 3 "OnlineTrafficResetComplete" 4 "CcsResetComplete" 5 "WifiHotSpotResetComplete" 6 "NotUsed_1" 7 "NotUsed_2" 8 "NotUsed_3" 9 "NotUsed_4" 10 "NotUsed_5" 11 "NotUsed_6" 12 "NotUsed_7" 13 "NotUsed_8" 14 "NotUsed_9" 15 "NotUsed_10" ;
VAL_ 563 FactoryReset_St 0 "Null" 1 "FactoryDefaultsRestored" 2 "NotUsed_1" 3 "NotUsed_2" ;
VAL_ 563 GridSrvc01_D_RqCld 0 "Off" 1 "On" 2 "No_Data_Exists" 3 "Faulty" ;
VAL_ 563 BattChrgStrtStop_D_Rq 0 "NoNewRequest" 1 "StartCharge" 2 "StopCharge" 3 "ReturnToSettings" ;
VAL_ 563 DrvBhavWarn_B_Rq 0 "Off" 1 "On" ;
VAL_ 563 KeyOffPwMde_D_Stat 0 "Inactive" 1 "On" 2 "On_With_Screen" 3 "NotUsed_2" 4 "NotUsed_3" 5 "NotUsed_4" 6 "NotUsed_5" 7 "NotUsed_6" ;
VAL_ 563 NtfyDrvTrgtDist_L2_Rq 8190 "NoDataExists" 8191 "Faulty" ;
VAL_ 563 VgfZone_D_Stat 0 "Off_Normal" 1 "Allowed_Zone" 2 "Warning_Zone" 3 "Restricted_Zone" 4 "GPS_Unavailable" 5 "NotUsed_1" 6 "NotUsed_2" 7 "Faulty" ;
VAL_ 563 DrvBhavAudioAlrt_D_Rq 0 "NoMessage" 1 "ExcessiveIdleBegin" 2 "ExcessiveSpeedBegin" 3 "HardAccelerationBegin" 4 "HardBrakingBegin" 5 "SeatbeltUnbuckled" 6 "ExcessiveSpeedAndUnbuckled" 7 "ExcessiveIdleAndUnbuckled" 8 "ExceedingPostedSpeedBegin" 9 "PostedSpeedAndUnbuckled" 10 "HarshCorneringBegin" 11 "ChangingLanesNoTurnSignal" 12 "DrivingTooClose" 13 "TooCloseAndExcessiveSpeed" 14 "TooCloseAndPostedSpeed" 15 "TooCloseAndUnbuckled" 16 "TooCloseAndDistracted" 17 "TooCloseAndDrowsy" 18 "DistractedDriving" 19 "DistractAndExcessiveSpeed" 20 "DistractAndPostedSpeed" 21 "DistractAndUnbuckled" 22 "DrowsyDriving" 23 "DrowsyAndExcessiveIdle" 24 "DrowsyAndExcessiveSpeed" 25 "DrowsyAndPostedSpeed" 26 "DrowsyAndUnbuckled" 27 "NotUsed_1" 28 "NotUsed_2" 29 "NotUsed_3" 30 "NotUsed_4" 31 "NotUsed_5" 32 "NotUsed_6" 33 "NotUsed_7" 34 "NotUsed_8" 35 "NotUsed_9" 36 "NotUsed_10" 37 "NotUsed_11" 38 "NotUsed_12" 39 "NotUsed_13" 40 "NotUsed_14" 41 "NotUsed_15" 42 "NotUsed_16" 43 "NotUsed_17" 44 "NotUsed_18" 45 "NotUsed_19" 46 "NotUsed_20" 47 "NotUsed_21" 48 "NotUsed_22" 49 "NotUsed_23" 50 "NotUsed_24" 51 "NotUsed_25" 52 "NotUsed_26" 53 "NotUsed_27" 54 "NotUsed_28" 55 "NotUsed_29" 56 "NotUsed_30" 57 "NotUsed_31" 58 "NotUsed_32" 59 "NotUsed_33" 60 "NotUsed_34" 61 "NotUsed_35" 62 "NotUsed_36" 63 "NotUsed_37" ;
VAL_ 563 EmgcyTrfcLght_D_Stat 0 "NoMessage" 1 "NotAvailable_ChimeOFF" 2 "NotAvailable_ChimeON" 3 "Engaged_ChimeOFF" 4 "Disengaged_ChimeOFF" 5 "Confirmed_ChimeOFF" 6 "NotUsed_1" 7 "NotUsed_2" 8 "NotUsed_3" 9 "NotUsed_4" 10 "NotUsed_5" 11 "NotUsed_6" 12 "NotUsed_7" 13 "NotUsed_8" 14 "NotUsed_9" 15 "NotUsed_10" ;
VAL_ 563 BattChrgStrtStop_D2_Rq 0 "NoNewRequest" 1 "StartCharge" 2 "StopCharge" 3 "ReturnToSettings" 4 "GridStartChargingPreferred" 5 "GridStartChargingFree" 6 "GridStopChargingMandatory" 7 "GridStopChargingPartial" 8 "NotUsed_1" 9 "NotUsed_2" 10 "NotUsed_3" 11 "NotUsed_4" 12 "NotUsed_5" 13 "NotUsed_6" 14 "NotUsed_7" 15 "NotUsed_8" ;
VAL_ 571 TrlrTngLoad_M_Est 2046 "NoDataExists" 2047 "Faulty" ;
VAL_ 571 VehPayloadAdd_M_Est 2046 "NoDataExists" 2047 "Faulty" ;
VAL_ 571 VehPayload_M_Est 1022 "NoDataExists" 1023 "Faulty" ;
VAL_ 571 TrlrTngLoad_Pc_Est 126 "NoDataExists" 127 "Faulty" ;
VAL_ 571 VehFalr_Pc_Est 126 "NoDataExists" 127 "Faulty" ;
VAL_ 571 VehPayload_Pc_Est 126 "NoDataExists" 127 "Faulty" ;
VAL_ 572 BattTracSrvcRqd_B_Rq 0 "Off" 1 "On" ;
VAL_ 572 BattTracWarnLamp_B_Rq 0 "Off" 1 "On" ;
VAL_ 572 PwSrcULoMde_D_Actl 0 "Standby" 1 "ForwardBuck" 2 "ReverseBoost" 3 "BuckSpecial" ;
VAL_ 572 BattTracClnt_Te_Actl 254 "NoDataExists" 255 "Faulty" ;
VAL_ 573 NfcDevcSearch_B_Rq 0 "Inactive" 1 "Active" ;
VAL_ 573 Esclck_D_RqLimActvtn 0 "NoRequest" 1 "Group1" 2 "Group2" 3 "Both" ;
VAL_ 573 VehStrtKeyType_D_Stat 0 "Null" 1 "Factory" 2 "User" 3 "NotUsed_1" ;
VAL_ 573 VehStrtKeySrc_D_Stat 0 "Null" 1 "Digital_Key" 2 "Peps_and_Ikt" 3 "Legacy_Paak" 4 "NotUsed_1" 5 "NotUsed_2" 6 "NotUsed_3" 7 "NotUsed_4" ;
VAL_ 573 VehOnOff_D_RqDrv 0 "Null" 1 "Off" 2 "Run" 3 "Start" ;
VAL_ 573 Esclck1_D_RqLim 0 "Initializing" 1 "NoLimitRequested" 2 "Custom1" 3 "Custom2" 4 "PowerPackBlock_Inhibit" 5 "SecureMode" 6 "NonMotiveMode" 7 "LimitedPropulsion" 8 "VslLow_ParkingLowSpeed" 9 "VslMed_UrbanSpeeds" 10 "VslHigh_HighwaySpeeds" 11 "VslCustom" 12 "TqLimitHigh_Truncation" 13 "TqLimitMed_ReducedPower" 14 "EvOnly" 15 "SaveEv" 16 "ForwardPropulsionOnly" 17 "ReversePropulsionOnly" 18 "NotUsed_1" 19 "NotUsed_2" 20 "NotUsed_3" 21 "NotUsed_4" 22 "NotUsed_5" 23 "NotUsed_6" 24 "NotUsed_7" 25 "NotUsed_8" 26 "NotUsed_9" 27 "NotUsed_10" 28 "NotUsed_11" 29 "NotUsed_12" 30 "NotUsed_13" 31 "NotUsed_14" ;
VAL_ 573 Esclck2_D_RqLim 0 "Initializing" 1 "NoLimitRequested" 2 "Custom1" 3 "Custom2" 4 "PowerPackBlock_Inhibit" 5 "SecureMode" 6 "NonMotiveMode" 7 "LimitedPropulsion" 8 "VslLow_ParkingLowSpeed" 9 "VslMed_UrbanSpeeds" 10 "VslHigh_HighwaySpeeds" 11 "VslCustom" 12 "TqLimitHigh_Truncation" 13 "TqLimitMed_ReducedPower" 14 "EvOnly" 15 "SaveEv" 16 "ForwardPropulsionOnly" 17 "ReversePropulsionOnly" 18 "NotUsed_1" 19 "NotUsed_2" 20 "NotUsed_3" 21 "NotUsed_4" 22 "NotUsed_5" 23 "NotUsed_6" 24 "NotUsed_7" 25 "NotUsed_8" 26 "NotUsed_9" 27 "NotUsed_10" 28 "NotUsed_11" 29 "NotUsed_12" 30 "NotUsed_13" 31 "NotUsed_14" ;
VAL_ 582 EngOff_T_Actl 65535 "Invalid" ;
VAL_ 582 BattULo_I_Actl 16383 "Fault" ;
VAL_ 582 PrkLckCtl_B_Enbl 0 "Disable" 1 "Enable" ;
VAL_ 582 BrkTrnShifLck_B_Stat 0 "NoShift" 1 "Shift" ;
VAL_ 582 BattULo_U_Actl 255 "Fault" ;
VAL_ 582 FuelPumpPwr_D_Stat 0 "Power_On" 1 "Power_Off_Impact" 2 "Power_Off_Service" 3 "Power_Off_Command" 4 "Power_Off_Default" 5 "NotUsed1" 6 "NotUsed2" 7 "NotUsed3" ;
VAL_ 582 DriverCrankingReq 0 "No_Crank_Request" 1 "Crank_Request" ;
VAL_ 582 DcacElPw_D_Rq 0 "AC_Power_NotRequested" 1 "AC_LowPower_Requested" 2 "AC_HighPower_Requested" 3 "NotUsed" ;
VAL_ 582 PrkLckCtlMsgTxt_D_Rq 0 "Null_BTSI_DI" 1 "BTSI_DI_1" 2 "BTSI_DI_2" 3 "BTSI_DI_3" ;
VAL_ 582 PtLatchActv_B_RqBcm 0 "Off" 1 "On" ;
VAL_ 582 PrkLckCtlUnlck_D_Stat 0 "Null" 1 "Transmission_Unlckd" 2 "Steering_Unlckd" 3 "Trans_And_Steer_Unlckd" ;
VAL_ 582 PrkLckCtlTow_B_Enbl 0 "Disable" 1 "Enable" ;
VAL_ 582 immoSecureIdleMode 0 "Inactive" 1 "Active" 2 "NotUsed1" 3 "NotUsed2" ;
VAL_ 582 ReFuelSwtchStat_D_Actl 0 "Off" 1 "On" 2 "NotUsed1" 3 "NotUsed2" ;
VAL_ 591 BattTrac_E_Nom 4094 "NoDataExists" 4095 "Faulty" ;
VAL_ 591 BattTrac_U_Nom 1022 "NoDataExists" 1023 "Faulty" ;
VAL_ 591 BattTrac_Ah_Nom 4095 "Faulty" ;
VAL_ 591 BattTracType_D_Actl 0 "LeadAcid" 1 "NickelMetalHydride" 2 "LithiumIronPhosphate" 3 "LithiumManganese" 4 "LithiumCobaltOxide" 5 "TernaryMaterial" 6 "LithiumIonPolymer" 7 "LithiumTitanateOxide" 8 "Other" 9 "NotUsed_1" 10 "NotUsed_2" 11 "NotUsed_3" 12 "NotUsed_4" 13 "NotUsed_5" 14 "NotUsed_6" 15 "NotUsed_7" ;
VAL_ 591 BattChrgRqd_E_Actl 4094 "NoDataExists" 4095 "Faulty" ;
VAL_ 594 BattTracClntIn_Te_Actl 255 "Fault" ;
VAL_ 594 BattTrac_Te_Actl 1022 "Unknown" 1023 "Fault" ;
VAL_ 594 BattTracCool_D_Falt 0 "Cooling_System_Operational" 1 "Cooling_System_Faulted" 2 "CoolSysPartialyOperational" 3 "NotUsed" ;
VAL_ 594 HvacRec_D_RqMxBatt 0 "0Percent_RecircFullOpen" 1 "10Percent_RecircMax" 2 "20Percent_RecircMax" 3 "30Percent_RecircMax" 4 "40Percent_RecircMax" 5 "50Percent_RecircMax" 6 "60Percent_RecircMax" 7 "70Percent_RecircMax" 8 "80Percent_RecircMax" 9 "90Percent_RecircMax" 10 "No_Override" 11 "NotUsed1" 12 "NotUsed2" 13 "NotUsed3" 14 "NotUsed4" 15 "NotUsed5" ;
VAL_ 594 BattTracSoc2_Pc_Actl 16382 "NoDataExists" 16383 "Faulty" ;
VAL_ 594 HvacAirFlw_B_RqBatt 0 "NoRequest" 1 "Request" ;
VAL_ 594 HvacAir_Flw_EstBatt 255 "Invalid" ;
VAL_ 594 BattTracSoc_Pc_Dsply 254 "NoDataExists" 255 "Faulty" ;
VAL_ 594 BattChrgRdyStat_D_Actl 0 "NotReady" 1 "ChargeWait" 2 "BatteryChargeReady" 3 "Charging" 4 "ChargeComplete" 5 "Faulted" 6 "NotUsed1" 7 "NotUsed2" ;
VAL_ 595 TrakAppl_D_RqMnu 0 "Deactivate_TrackApp" 1 "Activate_60_0mph" 2 "Activate_100_0mph" 3 "Activate_100_0kph" 4 "Activate_200_0kph" 5 "Activate_0_30mph" 6 "Activate_0_60mph" 7 "Activate_0_100mph" 8 "Activate_0_50kph" 9 "Activate_0_100kph" 10 "Activate_0_200kph" 11 "Activate_1_8mile" 12 "Activate_1_4mile" 13 "Activate_200m" 14 "Activate_400m" 15 "Activate_LapTimer" 16 "Activate_LineLock" 17 "NotUsed_1" 18 "NotUsed_2" 19 "NotUsed_3" 20 "NotUsed_4" 21 "NotUsed_5" 22 "NotUsed_6" 23 "NotUsed_7" 24 "NotUsed_8" 25 "NotUsed_9" 26 "NotUsed_10" 27 "NotUsed_11" 28 "NotUsed_12" 29 "NotUsed_13" 30 "NotUsed_14" 31 "NotUsed_15" ;
VAL_ 595 DrvIdMde_D_Rq 0 "Disable" 1 "Recognize" 2 "Enroll" 3 "ClearAll" 4 "DeleteMid" 5 "KeepAwake" 6 "NotUsed_2" 7 "Faulty" ;
VAL_ 595 EngIdlShutDownT_D_Rq 0 "Null" 1 "IdleMinute_1" 2 "IdleMinutes_2" 3 "IdleMinutes_3" 4 "IdleMinutes_4" 5 "IdleMinutes_5" 6 "IdleMinutes_6" 7 "IdleMinutes_7" 8 "IdleMinutes_8" 9 "IdleMinutes_9" 10 "IdleMinutes_10" 11 "IdleMinutes_11" 12 "IdleMinutes_12" 13 "IdleMinutes_13" 14 "IdleMinutes_14" 15 "IdleMinutes_15" 16 "IdleMinutes_16" 17 "IdleMinutes_17" 18 "IdleMinutes_18" 19 "IdleMinutes_19" 20 "IdleMinutes_20" 21 "IdleMinutes_21" 22 "IdleMinutes_22" 23 "IdleMinutes_23" 24 "IdleMinutes_24" 25 "IdleMinutes_25" 26 "IdleMinutes_26" 27 "IdleMinutes_27" 28 "IdleMinutes_28" 29 "IdleMinutes_29" 30 "IdleMinutes_30" 31 "IdleMinutes_31" 32 "IdleMinutes_32" 33 "IdleMinutes_33" 34 "IdleMinutes_34" 35 "IdleMinutes_35" 36 "IdleMinutes_36" 37 "IdleMinutes_37" 38 "IdleMinutes_38" 39 "IdleMinutes_39" 40 "IdleMinutes_40" 41 "IdleMinutes_41" 42 "IdleMinutes_42" 43 "IdleMinutes_43" 44 "IdleMinutes_44" 45 "IdleMinutes_45" 46 "IdleMinutes_46" 47 "IdleMinutes_47" 48 "IdleMinutes_48" 49 "IdleMinutes_49" 50 "IdleMinutes_50" 51 "IdleMinutes_51" 52 "IdleMinutes_52" 53 "IdleMinutes_53" 54 "IdleMinutes_54" 55 "IdleMinutes_55" 56 "IdleMinutes_56" 57 "IdleMinutes_57" 58 "IdleMinutes_58" 59 "IdleMinutes_59" 60 "IdleMinutes_60" 61 "IdleMinutes_61" 62 "IdleMinutes_62" 63 "IdleMinutes_63" 64 "IdleMinutes_64" 65 "IdleMinutes_65" 66 "IdleMinutes_66" 67 "IdleMinutes_67" 68 "IdleMinutes_68" 69 "IdleMinutes_69" 70 "IdleMinutes_70" 71 "IdleMinutes_71" 72 "IdleMinutes_72" 73 "IdleMinutes_73" 74 "IdleMinutes_74" 75 "IdleMinutes_75" 76 "IdleMinutes_76" 77 "IdleMinutes_77" 78 "IdleMinutes_78" 79 "IdleMinutes_79" 80 "IdleMinutes_80" 81 "IdleMinutes_81" 82 "IdleMinutes_82" 83 "IdleMinutes_83" 84 "IdleMinutes_84" 85 "IdleMinutes_85" 86 "IdleMinutes_86" 87 "IdleMinutes_87" 88 "IdleMinutes_88" 89 "IdleMinutes_89" 90 "IdleMinutes_90" 91 "IdleMinutes_91" 92 "IdleMinutes_92" 93 "IdleMinutes_93" 94 "IdleMinutes_94" 95 "IdleMinutes_95" 96 "IdleMinutes_96" 97 "IdleMinutes_97" 98 "IdleMinutes_98" 99 "IdleMinutes_99" 100 "IdleMinutes_100" 101 "IdleMinutes_101" 102 "IdleMinutes_102" 103 "IdleMinutes_103" 104 "IdleMinutes_104" 105 "IdleMinutes_105" 106 "IdleMinutes_106" 107 "IdleMinutes_107" 108 "IdleMinutes_108" 109 "IdleMinutes_109" 110 "IdleMinutes_110" 111 "IdleMinutes_111" 112 "IdleMinutes_112" 113 "IdleMinutes_113" 114 "IdleMinutes_114" 115 "IdleMinutes_115" 116 "IdleMinutes_116" 117 "IdleMinutes_117" 118 "IdleMinutes_118" 119 "IdleMinutes_119" 120 "IdleMinutes_120" 121 "IdleMinutes_121" 122 "IdleMinutes_122" 123 "IdleMinutes_123" 124 "IdleMinutes_124" 125 "IdleMinutes_125" 126 "IdleMinutes_126" 127 "IdleMinutes_127" 128 "IdleMinutes_128" 129 "IdleMinutes_129" 130 "IdleMinutes_130" 131 "IdleMinutes_131" 132 "IdleMinutes_132" 133 "IdleMinutes_133" 134 "IdleMinutes_134" 135 "IdleMinutes_135" 136 "IdleMinutes_136" 137 "IdleMinutes_137" 138 "IdleMinutes_138" 139 "IdleMinutes_139" 140 "IdleMinutes_140" 141 "IdleMinutes_141" 142 "IdleMinutes_142" 143 "IdleMinutes_143" 144 "IdleMinutes_144" 145 "IdleMinutes_145" 146 "IdleMinutes_146" 147 "IdleMinutes_147" 148 "IdleMinutes_148" 149 "IdleMinutes_149" 150 "IdleMinutes_150" 151 "IdleMinutes_151" 152 "IdleMinutes_152" 153 "IdleMinutes_153" 154 "IdleMinutes_154" 155 "IdleMinutes_155" 156 "IdleMinutes_156" 157 "IdleMinutes_157" 158 "IdleMinutes_158" 159 "IdleMinutes_159" 160 "IdleMinutes_160" 161 "IdleMinutes_161" 162 "IdleMinutes_162" 163 "IdleMinutes_163" 164 "IdleMinutes_164" 165 "IdleMinutes_165" 166 "IdleMinutes_166" 167 "IdleMinutes_167" 168 "IdleMinutes_168" 169 "IdleMinutes_169" 170 "IdleMinutes_170" 171 "IdleMinutes_171" 172 "IdleMinutes_172" 173 "IdleMinutes_173" 174 "IdleMinutes_174" 175 "IdleMinutes_175" 176 "IdleMinutes_176" 177 "IdleMinutes_177" 178 "IdleMinutes_178" 179 "IdleMinutes_179" 180 "IdleMinutes_180" 181 "IdleMinutes_181" 182 "IdleMinutes_182" 183 "IdleMinutes_183" 184 "IdleMinutes_184" 185 "IdleMinutes_185" 186 "IdleMinutes_186" 187 "IdleMinutes_187" 188 "IdleMinutes_188" 189 "IdleMinutes_189" 190 "IdleMinutes_190" 191 "IdleMinutes_191" 192 "IdleMinutes_192" 193 "IdleMinutes_193" 194 "IdleMinutes_194" 195 "IdleMinutes_195" 196 "IdleMinutes_196" 197 "IdleMinutes_197" 198 "IdleMinutes_198" 199 "IdleMinutes_199" 200 "IdleMinutes_200" 201 "IdleMinutes_201" 202 "IdleMinutes_202" 203 "IdleMinutes_203" 204 "IdleMinutes_204" 205 "IdleMinutes_205" 206 "IdleMinutes_206" 207 "IdleMinutes_207" 208 "IdleMinutes_208" 209 "IdleMinutes_209" 210 "IdleMinutes_210" 211 "IdleMinutes_211" 212 "IdleMinutes_212" 213 "IdleMinutes_213" 214 "IdleMinutes_214" 215 "IdleMinutes_215" 216 "IdleMinutes_216" 217 "IdleMinutes_217" 218 "IdleMinutes_218" 219 "IdleMinutes_219" 220 "IdleMinutes_220" 221 "IdleMinutes_221" 222 "IdleMinutes_222" 223 "IdleMinutes_223" 224 "IdleMinutes_224" 225 "IdleMinutes_225" 226 "IdleMinutes_226" 227 "IdleMinutes_227" 228 "IdleMinutes_228" 229 "IdleMinutes_229" 230 "IdleMinutes_230" 231 "IdleMinutes_231" 232 "IdleMinutes_232" 233 "IdleMinutes_233" 234 "IdleMinutes_234" 235 "IdleMinutes_235" 236 "IdleMinutes_236" 237 "IdleMinutes_237" 238 "IdleMinutes_238" 239 "IdleMinutes_239" 240 "IdleMinutes_240" 241 "Selectable_Idle_Not_Active" 242 "Indefinite_Idle" 243 "NotUsed_1" 244 "NotUsed_2" 245 "NotUsed_3" 246 "NotUsed_4" 247 "NotUsed_5" 248 "NotUsed_6" 249 "NotUsed_7" 250 "NotUsed_8" 251 "NotUsed_9" 252 "NotUsed_10" 253 "NotUsed_11" 254 "NotUsed_12" 255 "NotUsed_13" ;
VAL_ 595 TrakApplActvSet_D_Rq 0 "Null" 1 "AccTimer_Start_Automatic" 2 "AccTimer_Start_Drag" 3 "AccTimer_Start_Track" 4 "NotUsed_1" 5 "NotUsed_2" 6 "NotUsed_3" 7 "NotUsed_4" 8 "NotUsed_5" 9 "NotUsed_6" 10 "NotUsed_7" 11 "NotUsed_8" 12 "NotUsed_9" 13 "NotUsed_10" 14 "NotUsed_11" 15 "NotUsed_12" ;
VAL_ 596 DrvIdMde_D_Stat 0 "Null" 1 "Recognize" 2 "Enroll" 3 "ClearAll" 4 "DeleteMid" 5 "DBCorrupt" 6 "Idle" 7 "Temp_unavailable" ;
VAL_ 596 DrvId_D_Stat 0 "Null" 1 "OkMatched" 2 "OkNoMatch" 3 "FailWeakMatch" 4 "FailTimeout" 5 "NotUsed_1" 6 "NotUsed_2" 7 "NotUsed_3" ;
VAL_ 596 DrvIdActn_D_Stat 0 "Null" 1 "Fail" 2 "Success" 3 "NotUsed" ;
VAL_ 596 DrvExpression_D_Stat 0 "Null" 1 "FaceNotInView" 2 "TooManyFaces" 3 "OutsidePoseLimits" 4 "MouthOpen" 5 "FaceBlockage" 6 "EyesNotVisible" 7 "PoorTrackingQuality" 8 "NotAFace" 9 "ConstraintsOk" 10 "HasRegister" 11 "FailNoSlot" 12 "FailMultipleMatches" 13 "NotUsed_3" 14 "NotUsed_4" 15 "NotUsed_5" ;
VAL_ 602 PtcHtrRun_B_Rq 0 "Off" 1 "On" ;
VAL_ 602 ObdEngStdy_B_Stat 0 "No" 1 "Yes" ;
VAL_ 602 EngStrtSrvc_B_Allw 0 "No" 1 "Yes" ;
VAL_ 602 HtrnWarnLamp_B_Dsply 0 "Off" 1 "On" ;
VAL_ 602 HybPwLimOn_B_Stat 0 "No" 1 "Yes" ;
VAL_ 602 BattTracRsrvSoc_Pc_Rq 16382 "NoDataExists" 16383 "Faulty" ;
VAL_ 602 PwPckTqRdy_B_Dsply 0 "Off" 1 "On" ;
VAL_ 602 PwSrcULoMde_D_Rq 0 "Standby" 1 "ForwardBuck" 2 "ReverseBoost" 3 "BuckSpecial" ;
VAL_ 608 DcChrgWarnLamp_B_Rq 0 "Off" 1 "On" ;
VAL_ 608 DcChrgSrvcRqd_B_Rq 0 "Off" 1 "On" ;
VAL_ 608 EvseChrgIso_D_Stat 0 "Invalid" 1 "Valid" 2 "Warning" 3 "Faulty" ;
VAL_ 608 DgtlCommGtwyMde_D_Stat 0 "NotDetected" 1 "DcEim" 2 "DcPnc" 3 "DcPnc_Eim" 4 "AcEim" 5 "AcPnc" 6 "AcPnc_Eim" 7 "RestartRequest" 8 "Inactive" 9 "DgtlCommEstablished" 10 "DgtlCommFailed" 11 "NotUsed_3" 12 "NotUsed_4" 13 "NotUsed_5" 14 "NotUsed_6" 15 "NotUsed_7" ;
VAL_ 608 EvseDcChrgIso_D_Stat 0 "Invalid" 1 "Warning" 2 "Valid" 3 "NotUsed_1" 4 "NotUsed_2" 5 "NotUsed_3" 6 "NoDataExists" 7 "Faulty" ;
VAL_ 608 BattTracIsoDis_B_Rq 0 "No" 1 "Yes" ;
VAL_ 608 DcChrgRdy_D_Stat 0 "NotReady" 1 "Initialization" 2 "ChargeReady" 3 "WeldCheck" 4 "Precharge" 5 "Charging" 6 "ChargeComplete" 7 "GbtPrecharge" 8 "EvsePaused" 9 "EvseNotCompatible" 10 "EvseFault" 11 "CableCheck" 12 "NotUsed_2" 13 "NotUsed_3" 14 "NotUsed_4" 15 "Faulty" ;
VAL_ 608 EvseChrg2_Pw_Mx 32766 "NoDataExists" 32767 "Faulty" ;
VAL_ 608 DgtlCommGtwy_D_Falt 0 "NoFault" 1 "EvseStatShutdown" 2 "EvseStatUtilityIntrpt" 3 "EvseEmergShutdown" 4 "EvseMalfunction" 5 "EvseStopNotification" 6 "EvseSlaacErr" 7 "EvseUpdErr" 8 "EvseTcpCnnctFail" 9 "EvseTlsFail" 10 "EvseTlsUnexpectedMsg" 11 "EvseTlsBadRecordMac" 12 "EvseTlsDecryptFail" 13 "EvseTlsHandshakeFail" 14 "EvseTlsBadCert" 15 "EvseTlsCertExpired" 16 "EvseTlsUnknownCA" 17 "EvseMsgTimeout" 18 "EvseCommSetupTimeout" 19 "EvseCableCheckTimeout" 20 "EvsePreChrgTimeout" 21 "EvseResFailed" 22 "EvseResSeqErr" 23 "EvseResSignErr" 24 "EvseResUnknownSession" 25 "EvseResSvcldInvld" 26 "EvseResPymtSelectInvld" 27 "EvseResCertExp" 28 "EvseResCertRvk" 29 "EvseResNoCertAvail" 30 "EvseResCertChainErr" 31 "EvseResContractCancel" 32 "EvseResChlgInvld" 33 "EvseResWrongEnrgyTransMde" 34 "EvseResWrongChrgParam" 35 "EvseResChrgProfileInvld" 36 "EvseResTrfSelectInvld" 37 "EvseResPwrDelNotApplied" 38 "EvseResMeterSignNotVld" 39 "EvseResNoChrgSvcSelect" 40 "EvseResContractErr" 41 "EvseResCertNotAllowed" 42 "EvseResNoSuppAppProt" 43 "EvseResContractNotAccept" 44 "EvseResMoUnknown" 45 "EvseResOemProvCertRev" 46 "EvseResOemSubCa1CertRev" 47 "EvseResOemSubCa2CertRev" 48 "EvseResMoProvCertRev" 49 "EvseResMoSubCa1CertRev" 50 "EvseResMoSubCa2CertRev" 51 "EvseResRootCaCertRev" 52 "EvseResCpsProvCertRev" 53 "EvseResSubCA1CertRev" 54 "EvseResSubCA2CertRev" 55 "EvseResCpsRootCaCertRev" 56 "EvseGbtOverTemp" 57 "EvseGbtConnectorFalt" 58 "EvseGbtIntOverTemp" 59 "EvseGbtEnergyTransFalt" 60 "EvseGbtEmergShutdown" 61 "EvseGbtOtherFalt" 62 "EvseGbtChrgCurrntMismatch" 63 "EvseGbtCrgVoltMismatch" 64 "EvseGbtCommTimeout" 65 "NotUsed_1" 127 "NotUsed_63" ;
VAL_ 608 DgtlCommPnc_D_Stat 0 "Null" 1 "NoContractsInstalled" 2 "Disable" 3 "Enable" 4 "NotUsed_1" 5 "NotUsed_2" 6 "NotUsed_3" 7 "Faulty" ;
VAL_ 611 AwdSrvcRqd_B_Rq 0 "Off" 1 "On" ;
VAL_ 611 Awd2wdLamp_D_RqDsply 0 "Off" 1 "On" 2 "Flash" 3 "Not_Used" ;
VAL_ 611 NtrlTowAvail_B_Stat 0 "NotAvailable" 1 "Available" ;
VAL_ 611 AwdRnge_D_Actl 0 "Low_Range_Locked" 1 "Low_Range_Auto" 2 "Low_Range_2wd" 3 "Neutral" 4 "High_Range_Locked" 5 "High_Range_Auto" 6 "High_Range_2wd" 7 "Unknown" ;
VAL_ 611 AwdLck_Tq_Rq 4094 "Unknown" 4095 "Fault" ;
VAL_ 611 AwdAutoLamp_D_RqDsply 0 "Off" 1 "On" 2 "Flash" 3 "Not_Used" ;
VAL_ 611 AwdHiLamp_D_RqDsply 0 "Off" 1 "On" 2 "Flash" 3 "Not_Used" ;
VAL_ 611 AwdOffRoadMode_D_Stats 0 "Normal_Mode" 1 "Off_Road" 2 "Extreme_Off_Road" 3 "Invalid" ;
VAL_ 611 AwdSys_D_Stat 0 "4x4_L_H_Inactive" 1 "4x4_L_H_Active" 2 "NotUsed" 3 "Faulty" ;
VAL_ 611 AwdLck_D_Stat 0 "OK" 1 "Completely_Opened_by_Cmd" 2 "Inactive" 3 "Fault" 4 "Warning" 5 "Disabled" 6 "Fully_Locked_by_Cmd" 7 "Torque_Limited_by_Cmd" 8 "Under_External_Torque_Ctrl" 9 "Undefined" ;
VAL_ 611 SelDrvMdeAwd_D_Stat 0 "NotAvailable" 1 "Available" 2 "TemporarilyNotAvailable" 3 "Faulty" ;
VAL_ 611 AwdLoLamp_D_RqDsply 0 "Off" 1 "On" 2 "Flash" 3 "Not_Used" ;
VAL_ 611 AwdDrvMde_D_Stat 0 "Normal" 1 "Sport" 2 "Weather" 3 "MudAndSand" 4 "Baja" 5 "RockCrawl" 6 "NotAvailable" 7 "Faulty" ;
VAL_ 611 AwdTerrMde_D_Actl 0 "Special_Operating_Mode_Off" 1 "Low_Mu_Mode" 2 "Undefined" 3 "Sand_Mode" 4 "Mud_Ruts_Mode" 5 "Rock_Crawl_Mode" 6 "Dynamic_Mode" 7 "Fail_Safe_Default" ;
VAL_ 611 AwdTerrMdeChng_D_Rdy 0 "Mode_Change_Available" 1 "Module_In_Initialization" 2 "ModeUnavailDynamicCond" 3 "SpOpModes_NotSupported" 4 "ModeUnavailDrInputRqd" 5 "Undefined_1" 6 "Undefined_2" 7 "Fault" ;
VAL_ 611 AwdStat_D_RqDsply 0 "Normal_No_Message" 1 "Into_4Low_Speed" 2 "Into_4Low_Brake" 3 "Into_4Low_Neutral" 4 "Into_4Low_Clutch" 5 "Out_of_4Low_Speed" 6 "Out_of_4Low_Brake" 7 "Out_of_4Low_Neutral" 8 "Out_of_4Low_Clutch" 9 "Shift_In_Progress" 10 "4x4_Locked_Temporarily" 11 "4x4_Disabled_Temporarily" 12 "4x4_Auto_Restored" 13 "Blocked_Shift_Assist" 14 "4x4_Off_Road_Mode" 15 "4x4_Exiting_Off_Road" 16 "4x4_Extreme_Off_Road_Mode" 17 "4x4_Off_Road_Speed" 18 "AWD_OFF" 19 "Neutral_Tow_Enabled" 20 "Neutral_Tow_Disabled" 21 "Change_AWD_PTU_Oil" 22 "AWD_PTU_Oil_Changed" 23 "Out_of_4Low_Crawl" 24 "4x4_Mode_Unavail_TMS" 25 "Lkr_Mode_Unavail_TMS" 26 "Shift_To_Neutral" 27 "To_Engage_4x4_Slow_To_3MPH" 28 "To_Engage_4x4_Release_Aped" 29 "Cfg_Perf_Redc_See_Manual" 30 "4wd_Lock_Required" 31 "Rear_Diff_Lock_Not_Avail" ;
VAL_ 613 OCSLevel2Error 0 "No" 1 "Yes" ;
VAL_ 613 ObjectEntrapped 0 "No" 1 "Yes" ;
VAL_ 613 BeltWarnThres_D_Stat 0 "NotSupported" 1 "Under_Threshold" 2 "Over_Threshold" 3 "NotUsed1" 4 "NotUsed2" 5 "NotUsed3" 6 "No_Data_Exists" 7 "Faulty" ;
VAL_ 613 OCSLevel1Error 0 "No" 1 "Yes" ;
VAL_ 613 OCSSensrDataUpperLim 255 "Invalid" ;
VAL_ 613 OCSSensrDataLowerLim 255 "Invalid" ;
VAL_ 613 VehicleCalibrationId 255 "Invalid" ;
VAL_ 613 VehicleMYCalibrationId 255 "Invalid" ;
VAL_ 618 IgnPsswrdLckout_B_Stat 0 "Inactive" 1 "Active" ;
VAL_ 618 PaakCtlData_D_Stat 0 "Idle" 1 "RequestTargetIdBlock1" 2 "RequestTargetIdBlock2" 3 "EchoTargetIdBlock1" 4 "Response" 5 "NotUsed_1" 6 "NotUsed_2" 7 "NotUsed_3" ;
VAL_ 618 PaakLoclzd_D_Stat 0 "BackgroundScan" 1 "MaintainLink" 2 "PausedLoc" 3 "FullLoc" 4 "NotUsed_1" 5 "NotUsed_2" 6 "NotUsed_3" 7 "NotUsed_4" 8 "NotUsed_5" 9 "NotUsed_6" 10 "NotUsed_7" 11 "NotUsed_8" 12 "NotUsed_9" 13 "NotUsed_10" 14 "NotUsed_11" 15 "NotUsed_12" ;
VAL_ 618 IgnPsswrdSetup_B_Rq 0 "Inactive" 1 "Active" ;
VAL_ 618 PaakCtlType_D_Stat 0 "Null" 1 "Invalid" 2 "Valid" 3 "NotUsed" ;
VAL_ 619 PaakCtlActv_D_Rq 0 "Null" 1 "UnlockDriverDoor" 2 "UnlockAllDoors" 3 "UnlockCargoDoor" 4 "UnlockAllDoorsPlusCargo" 5 "LockAll" 6 "DoubleLock" 7 "DecklidRelease" 8 "LiftgateRelease" 9 "LiftgateGlassRelease" 10 "PanicOn" 11 "PanicOff" 12 "GlobalOpen" 13 "GlobalClose" 14 "PowerLiftgate" 15 "LeftPowerSlidingDoor" 16 "RightPowerSlidingDoor" 17 "PowerDecklid" 18 "RemoteStart" 19 "RemoteStop" 20 "TrunkFrontRelease" 21 "NotUsed_3" 22 "NotUsed_4" 23 "NotUsed_5" 24 "NotUsed_6" 25 "NotUsed_7" 26 "NotUsed_8" 27 "NotUsed_9" 28 "NotUsed_10" 29 "NotUsed_11" 30 "NotUsed_12" 31 "NotUsed_13" ;
VAL_ 619 KeyPadCodeProg_D_Rq 0 "Null" 1 "ProgrammingMode" 2 "Add" 3 "Delete" 4 "DeleteAll" 5 "NotUsed_1" 6 "NotUsed_2" 7 "NotUsed_3" ;
VAL_ 619 PaakCnnct_D_Stat 0 "Null" 1 "NotConnected" 2 "Connected" 3 "NotUsed" ;
VAL_ 621 IgnPsswrdActv_B_Stat 0 "Inactive" 1 "Active" ;
VAL_ 621 FobTrgtType_D_Rq 0 "Null" 1 "Crypto" 2 "Registry" 3 "Polling" 4 "NotUsed_1" 5 "NotUsed_2" 6 "NotUsed_3" 7 "NotUsed_4" ;
VAL_ 621 RmtCtlSelPrkMde_D_Rq 0 "None" 1 "ParkIn" 2 "FreeDrive" 3 "NotUsed" ;
VAL_ 621 RmtCtlSelMoveDir_D_Rq 0 "None" 1 "Forward" 2 "Backward" 3 "NotUsed" ;
VAL_ 621 FobTrgtZone_D_Rq 0 "Null" 1 "Interior" 2 "Driver" 3 "Passenger" 4 "RearExterior" 5 "RearInterior" 6 "Approach" 7 "NotUsed_1" 8 "NotUsed_2" 9 "NotUsed_3" 10 "NotUsed_4" 11 "NotUsed_5" 12 "NotUsed_6" 13 "NotUsed_7" 14 "NotUsed_8" 15 "NotUsed_9" ;
VAL_ 621 RmtCtlSelSlot_D_Rq 0 "None" 1 "Front" 2 "Rear" 3 "Left" 4 "Right" 5 "NotUsed_1" 6 "NotUsed_2" 7 "NotUsed_3" ;
VAL_ 621 RmtCtlRjctAutoCfg_B_Rq 0 "No" 1 "Yes" ;
VAL_ 627 RoadSignInfo1_D_Dsply 0 "Inactive" 1 "SlowTrafficAhead" 2 "RoadWorksAhead" 3 "CrossWindAhead" 4 "DriveWrongWay" 5 "FogAhead" 6 "GasPipeLeakWarning" 7 "GoodsDrop" 8 "Pedestrian" 9 "RainOrSnowRoad" 10 "RoadCrack" 11 "FireAlarmOnRoad" 12 "FrozenRoad" 13 "SandstormAhead" 14 "SlipperyRoad" 15 "Speedlimit_10" 16 "Speedlimit_20" 17 "Speedlimit_30" 18 "Speedlimit_40" 19 "Speedlimit_50" 20 "Speedlimit_60" 21 "Speedlimit_70" 22 "Speedlimit_80" 23 "Speedlimit_90" 24 "Speedlimit_100" 25 "Speedlimit_110" 26 "Speedlimit_120" 27 "TrafficAccidentAhead" 28 "TrafficControlAhead" 29 "TunnelInWaterAhead" 30 "VehicleBreak" 31 "VehiclesInQue" 32 "WaterOnRoad" 33 "WaterPipeBreak" 34 "DangerRoadAhead" 35 "NotUsed_1" 253 "NotUsed_219" 254 "NoDataExists" 255 "Faulty" ;
VAL_ 627 RoadStopLine_L_Est 65534 "NoDataExists" 65535 "Faulty" ;
VAL_ 627 TrfcLghtVActv_B_Stat 0 "Off" 1 "On" ;
VAL_ 627 TrfcLghtDir_D_Stat 0 "Inactive" 1 "StraightActivated" 2 "LeftActivated" 3 "RightActivated" 4 "UtrunActivated" 5 "NotUsed" 6 "NoDataExists" 7 "Faulty" ;
VAL_ 627 TrfcLght_D_Stat 0 "OffOrNoMatchedLight" 1 "One" 2 "Two" 3 "Three" 4 "Four" 5 "NotUsed" 6 "NoDataExists" 7 "Faulty" ;
VAL_ 627 RoadStopLineL_B_Avail 0 "Off" 1 "On" ;
VAL_ 627 TrfcLght_V_Mn 254 "NoDataExists" 255 "Faulty" ;
VAL_ 627 TrfcLght_V_Mx 254 "NoDataExists" 255 "Faulty" ;
VAL_ 627 TrfcLghtWarnActv_B_Stat 0 "Off" 1 "On" ;
VAL_ 627 TrfcLghtDecel_A_Dsply 126 "NoDataExists" 127 "Faulty" ;
VAL_ 627 VehToInfrstrctr_D_Stat 0 "InServiceFunctionOK" 1 "InServiceWithoutV2IData" 2 "LostConnection" 3 "SubComponentUnknownError" 4 "NotUsed_1" 5 "NotUsed_2" 6 "NoDataExists" 7 "Faulty" ;
VAL_ 630 TrfcLghtLeft_T_Actl 254 "NoDataExists" 255 "Faulty" ;
VAL_ 630 TrfcLghtLeftType_D_Stat 0 "Inactive" 1 "RoundBall" 2 "DirectionalArrow" 3 "Faulty" ;
VAL_ 630 TrfcLghtLeftOn_D_Stat 0 "Inactive" 1 "On" 2 "Blink" 3 "FocusedOn" 4 "FocusedBlink" 5 "NotUsed" 6 "NoDataExists" 7 "Faulty" ;
VAL_ 630 TrfcLghtLeftColr_D_Stat 0 "Inactive" 1 "Red" 2 "Orange" 3 "Green" 4 "NotUsed_1" 5 "NotUsed_2" 6 "NoDataExists" 7 "Faulty" ;
VAL_ 630 TrfcLghtRight_T_Actl 254 "NoDataExists" 255 "Faulty" ;
VAL_ 630 TrfcLghtRightType_D_St 0 "Inactive" 1 "RoundBall" 2 "DirectionalArrow" 3 "Faulty" ;
VAL_ 630 TrfcLghtRightOn_D_Stat 0 "Inactive" 1 "On" 2 "Blink" 3 "FocusedOn" 4 "FocusedBlink" 5 "NotUsed" 6 "NoDataExists" 7 "Faulty" ;
VAL_ 630 TrfcLghtRightColr_D_St 0 "Inactive" 1 "Red" 2 "Orange" 3 "Green" 4 "NotUsed_1" 5 "NotUsed_2" 6 "NoDataExists" 7 "Faulty" ;
VAL_ 630 TrfcLghtStrght_T_Actl 254 "NoDataExists" 255 "Faulty" ;
VAL_ 630 TrfcLghtStrghtType_D_St 0 "Inactive" 1 "RoundBall" 2 "DirectionalArrow" 3 "Faulty" ;
VAL_ 630 TrfcLghtStrghtOn_D_Stat 0 "Inactive" 1 "On" 2 "Blink" 3 "FocusedOn" 4 "FocusedBlink" 5 "NotUsed" 6 "NoDataExists" 7 "Faulty" ;
VAL_ 630 TrfcLghtStrghtColr_D_St 0 "Inactive" 1 "Red" 2 "Orange" 3 "Green" 4 "NotUsed_1" 5 "NotUsed_2" 6 "NoDataExists" 7 "Faulty" ;
VAL_ 630 TrfcLghtUturn_T_Actl 254 "NoDataExists" 255 "Faulty" ;
VAL_ 630 TrfcLghtUturnType_D_St 0 "Inactive" 1 "RoundBall" 2 "DirectionalArrow" 3 "Faulty" ;
VAL_ 630 TrfcLghtUturnOn_D_Stat 0 "Inactive" 1 "On" 2 "Blink" 3 "FocusedOn" 4 "FocusedBlink" 5 "NotUsed" 6 "NoDataExists" 7 "Faulty" ;
VAL_ 630 TrfcLghtUturnColr_D_St 0 "Inactive" 1 "Red" 2 "Orange" 3 "Green" 4 "NotUsed_1" 5 "NotUsed_2" 6 "NoDataExists" 7 "Faulty" ;
VAL_ 636 WifiHtsptCrdntl_B_Stat 0 "NotAvailable" 1 "Available" ;
VAL_ 636 WifiHtsptEnbl_D_Stat 0 "Null" 1 "Off" 2 "On" 3 "OnDisabled" ;
VAL_ 636 WifiEnbl_D_Stat 0 "Null" 1 "Disable" 2 "Enable" 3 "NotUsed" ;
VAL_ 636 WifiDevcListNew_B_Stat 0 "NotAvailable" 1 "Available" ;
VAL_ 636 WifiDataUsage_D_Stat 0 "Null" 1 "FreeTrialPeriodWaiting" 2 "PercentDataUsed" 3 "NotUsed_1" ;
VAL_ 636 ModemSigStren_D_Stat 0 "ZeroBars" 1 "OneBar" 2 "TwoBars" 3 "ThreeBars" 4 "FourBars" 5 "FiveBars" 6 "NotDetermined" 7 "NotUsed_1" ;
VAL_ 636 WifiHtsptVisbl_D_Stat 0 "Null" 1 "Off" 2 "On" 3 "Not_used" ;
VAL_ 636 WifiHtsptScrty_D_Stat 0 "Null" 1 "Wpa2_Wpa" 2 "Wapi" 3 "NotUsed_1" ;
VAL_ 636 WifiHtsptCnnct_D_Stat 0 "Null" 1 "NotConnected" 2 "Connected" 3 "NotUsed" ;
VAL_ 636 WifiDataUsageOn_D_Stat 0 "Null" 1 "Off" 2 "On" 3 "NotUsed" ;
VAL_ 636 ModemTechnology_D2_Stat 0 "Null" 1 "NoNetwork" 2 "Gsm" 3 "Gprs" 4 "Edge" 5 "Umts" 6 "HspaPlus" 7 "Lte" ;
VAL_ 636 Telematics_D_Falt 0 "Null" 1 "ChipsetInitializationFailu" 2 "RunTimeError" 3 "NotUsed_1" 4 "NotUsed_2" 5 "NotUsed_3" 6 "NotUsed_4" 7 "NotUsed_5" ;
VAL_ 636 WifiHtspt_D_Falt 0 "Null" 1 "Error1" 2 "Error2" 3 "Error3" 4 "Error4" 5 "Error5" 6 "Error6" 7 "Error7" 8 "Error8" 9 "Error9" 10 "Error10" 11 "Error11" 12 "Error12" 13 "Error13" 14 "Error14" 15 "Error15" ;
VAL_ 636 WifiHtsptFqBand_D_Stat 0 "Null" 1 "Band_1" 2 "Band_2" 3 "NotUsed_1" ;
VAL_ 636 WifiHtsptFq_D_Avail 0 "Null" 1 "AllRestricted" 2 "Band_1_Only" 3 "Band_2_Only" 4 "AllAvailable" 5 "NotUsed_1" 6 "NotUsed_2" 7 "NotUsed_3" ;
VAL_ 638 EmgcyCall_D_Stat 0 "Null" 1 "EmergencyCallNotSupported" 2 "NoEvent" 3 "AutoEmergencyCall" 4 "ManualEmergencyCall" 5 "NotUsed_1" 6 "NotUsed_2" 7 "NotUsed_3" ;
VAL_ 638 EmgcyCallHmi_D_Stat 0 "Null" 1 "NoEvent" 2 "CallCancelTimer" 3 "CallDial" 4 "CallMsdTransfer" 5 "CallInProgress" 6 "CallConnected" 7 "CallRetry" 8 "CallCancelled" 9 "CallNotPossible" 10 "CallDisconnected" 11 "CallCompleted" 12 "Malfunction" 13 "Disabled" 14 "Standby" 15 "NotUsed_1" ;
VAL_ 638 EmgcyCallFalt_B_Dsply 0 "No" 1 "Yes" ;
VAL_ 639 OfbChrgGoTExtHtr_D_Rq 0 "Null" 1 "Off" 2 "On" 3 "NotUsed" ;
VAL_ 639 OfbChrgGoTDelete_B_Rq 0 "NoRequest" 1 "Request" ;
VAL_ 639 OfbChrgClearAll_B_Rq 0 "NoRequest" 1 "Request" ;
VAL_ 639 OfbChrgGoTUpdate_B_Rq 0 "NoRequest" 1 "Request" ;
VAL_ 639 OfbChrgGoTOn_D_Rq 0 "Null" 1 "Off" 2 "On" 3 "NotUsed" ;
VAL_ 639 OfbChrgGoTHr_T_Rq 30 "NoDataExists" 31 "Faulty" ;
VAL_ 639 OfbChrgGoTTouch_D_Rq 0 "Null" 1 "Off" 2 "On" 3 "NotUsed" ;
VAL_ 639 OfbChrgGoTPrcond_D_Rq 0 "Off" 1 "Low" 2 "Medium" 3 "High" ;
VAL_ 639 OfbChrgGoTMnte_D_Rq 0 "Minute_0" 1 "Minute_5" 2 "Minute_10" 3 "Minute_15" 4 "Minute_20" 5 "Minute_25" 6 "Minute_30" 7 "Minute_35" 8 "Minute_40" 9 "Minute_45" 10 "Minute_50" 11 "Minute_55" 12 "NotUsed_1" 13 "NotUsed_2" 14 "NotUsed_3" 15 "NotUsed_4" ;
VAL_ 639 ScOnb_B_Stat 0 "Disable" 1 "Enable" ;
VAL_ 639 OfbChrgPrflUpdate_B_Rq 0 "NoRequest" 1 "Request" ;
VAL_ 640 SeatFold3lButtn_D_Stat 0 "Not_Pressed" 1 "Pressed" ;
VAL_ 640 SeatFold3bButtn_D_Stat 0 "Not_Pressed" 1 "Pressed" ;
VAL_ 640 SeatBckMtnRl_D_Stat 0 "NotMoving" 1 "Opening" 2 "Folding" 3 "NotUsed_1" 4 "NotUsed_2" 5 "NotUsed_3" 6 "NotUsed_4" 7 "NotUsed_5" ;
VAL_ 640 SeatBckMtn3l_D_Stat 0 "NotMoving" 1 "Opening" 2 "Folding" 3 "NotUsed_1" 4 "NotUsed_2" 5 "NotUsed_3" 6 "NotUsed_4" 7 "NotUsed_5" ;
VAL_ 640 SeatBckPosRl_D_Stat 0 "ComfortZone" 1 "FoldZone" 2 "FoldToFlat" 3 "Lifted" 4 "NotUsed_1" 5 "NotUsed_2" 6 "NotUsed_3" 7 "NotUsed_4" 8 "NotUsed_5" 9 "NotUsed_6" 10 "NotUsed_7" 11 "NotUsed_8" 12 "NotUsed_9" 13 "NotUsed_10" 14 "NotUsed_11" 15 "Faulty" ;
VAL_ 640 SeatBckPos3l_D_Stat 0 "ComfortZone" 1 "FoldZone" 2 "FoldToFlat" 3 "Lifted" 4 "NotUsed_1" 5 "NotUsed_2" 6 "NotUsed_3" 7 "NotUsed_4" 8 "NotUsed_5" 9 "NotUsed_6" 10 "NotUsed_7" 11 "NotUsed_8" 12 "NotUsed_9" 13 "NotUsed_10" 14 "NotUsed_11" 15 "Faulty" ;
VAL_ 640 SeatFoldRrButtn_D_Stat 0 "Not_Pressed" 1 "Pressed" ;
VAL_ 640 SeatFoldRlButtn_D_Stat 0 "Not_Pressed" 1 "Pressed" ;
VAL_ 640 SeatFoldRbButtn_D_Stat 0 "Not_Pressed" 1 "Pressed" ;
VAL_ 640 SeatFold3rButtn_D_Stat 0 "Not_Pressed" 1 "Pressed" ;
VAL_ 640 SeatMtnRlMsgTxt_D_Rq 0 "NoMessage" 1 "Malfunction" 2 "SeatLockReminder" 3 "SecondRowFnInhbtByOccupy" 4 "SecondRowFnInhbtByVehMovin" 5 "NotUsed_1" 6 "NotUsed_2" 7 "NotUsed_3" 8 "NotUsed_4" 9 "NotUsed_5" 10 "NotUsed_6" 11 "NotUsed_7" 12 "NotUsed_8" 13 "NotUsed_9" 14 "NotUsed_10" 15 "NotUsed_11" ;
VAL_ 640 SeatSlidPosR2Drv_B_St 0 "Null" 1 "Stall" ;
VAL_ 640 SeatMovR2Drv_D_Res 0 "Null" 1 "Success" 2 "Pending" 3 "Rejected" 4 "Interrupted" 5 "Failed" 6 "In_Prog" 7 "Invalid" 8 "NotUsed_1" 9 "NotUsed_2" 10 "NotUsed_3" 11 "NotUsed_4" 12 "NotUsed_5" 13 "NotUsed_6" 14 "NotUsed_7" 15 "Faulty" ;
VAL_ 640 SeatCalfRestR2Drv_B_St 0 "Null" 1 "Stall" ;
VAL_ 640 SeatLmbrHghtR2Drv_B_St 0 "Null" 1 "Stall" ;
VAL_ 640 SeatLmbrExtnR2Drv_B_St 0 "Null" 1 "Stall" ;
VAL_ 640 SeatBckInclnR2Drv_B_St 0 "Null" 1 "Stall" ;
VAL_ 640 SeatMovSrvcR2Drv_D_Arb 0 "Null" 1 "Local" 2 "Soa" 3 "NotUsed_1" ;
VAL_ 647 HEC_BTEndTelService_Rq 0 "Inactive" 1 "EndOngoingTelephonyCall" ;
VAL_ 647 HEC_BTIncomingCall_Rq 0 "Inactive" 1 "AcceptIncomingCall" 2 "DeclineIncomingCall" ;
VAL_ 648 TrlrCamraCalib_D_Rq 0 "CalibrationNotRequested" 1 "CalibrationRequested" 2 "NotUsed_1" 3 "NotUsed_2" ;
VAL_ 649 AirAmb_Te_ActlCld2 1022 "NoDataExists" 1023 "Faulty" ;
VAL_ 649 InftnmntHlth_D_Stat 0 "Unknown" 1 "HealthLevel_1" 2 "HealthLevel_2" 3 "HealthLevel_3" 4 "NotUsed_1" 5 "NotUsed_2" 6 "NotUsed_3" 7 "NotUsed_4" 8 "NotUsed_5" 9 "NotUsed_6" 10 "NotUsed_7" 11 "NotUsed_8" 12 "NotUsed_9" 13 "NotUsed_10" 14 "NotUsed_11" 15 "NotUsed_12" ;
VAL_ 651 CrnkInhbtSrvcHlth_B_St 0 "Not_Ok" 1 "Ok" ;
VAL_ 651 EmgcyCallMute_D_Stat 0 "Null" 1 "EmergencyCallUnmute" 2 "AutomaticEmergencyCallMute" 3 "ManualEmergencyCallMute" 4 "NotUsed1" 5 "NotUsed2" 6 "NotUsed3" 7 "NotUsed4" ;
VAL_ 651 TelematicsSrvc_D_St 0 "Null" 1 "Active" 2 "ExpiringSoon" 3 "Expired" 4 "NotifyExpired" 5 "NotActivatedYet" 6 "NotifyNotActivatedYet" 7 "NotUsed" ;
VAL_ 652 TelematicsSrvc_D_St2 0 "Null" 1 "Active" 2 "ExpiringSoon" 3 "Expired" 4 "NotifyExpired" 5 "NotActivatedYet" 6 "NotifyNotActivatedYet" 7 "NotUsed_1" ;
VAL_ 662 Rear_Temp 0 "No_Request" 1 "Max_Cooling" 2 "Level_3_Cooling" 3 "Level_2_Cooling" 4 "Level_1_Cooling" 5 "No_Heating_Cooling" 6 "Level_1_Heating" 7 "Level_2_Heating" 8 "Level_3_Heating" 9 "Max_Heating" 10 "NotUsed_1" 11 "NotUsed_2" 12 "NotUsed_3" 13 "NotUsed_4" 14 "NotUsed_5" 15 "NotUsed_6" ;
VAL_ 662 Rear_Blower_Speed 0 "No_Request" 1 "Blower_Speed_1" 2 "Blower_Speed_2" 3 "Blower_Speed_3" 4 "Blower_Speed_4" 5 "Blower_Speed_5" 6 "Blower_Speed_6" 7 "Blower_Speed_7" 8 "Min_Blower" 9 "Max_Blower" 10 "Zero_Blower" 11 "NotUsed_2" 12 "NotUsed_3" 13 "NotUsed_4" 14 "NotUsed_5" 15 "NotUsed_6" ;
VAL_ 662 Running_Board_Cmd2 0 "All_Disabled" 1 "All_Enabled" 2 "Manually_Deployed" 3 "Unused" ;
VAL_ 662 Rear_Set_Temp 0 "No_Request" 1 "LO" 2 "15_5" 3 "16_0" 4 "16_5" 5 "17_0" 6 "17_5" 7 "18_0" 8 "18_5" 9 "19_0" 10 "19_5" 11 "20_0" 12 "20_5" 13 "21_0" 14 "21_5" 15 "22_0" 16 "22_5" 17 "23_0" 18 "23_5" 19 "24_0" 20 "24_5" 21 "25_0" 22 "25_5" 23 "26_0" 24 "26_5" 25 "27_0" 26 "27_5" 27 "28_0" 28 "28_5" 29 "29_0" 30 "29_5" 31 "HI" ;
VAL_ 662 ActvButtnLeft_D_Rq 0 "NonePressed" 1 "OnBodyLHS" 2 "OffBodyLHS" 3 "PresetOneLHS" 4 "PresetTwoLHS" 5 "PresetOneSaveLHS" 6 "PresetTwoSaveLHS" 7 "Cycle_8_LHS" 8 "Cycle_C_LHS" 9 "Cycle_O_LHS" 10 "Cycle_LHS" 11 "Cycle_I_LHS" 12 "NotUsed_1" 13 "NotUsed_2" 14 "NotUsed_3" 15 "NotUsed_4" ;
VAL_ 662 Third_Rear_Blower_Speed 0 "No_Request" 1 "Blower_Speed_1" 2 "Blower_Speed_2" 3 "Blower_Speed_3" 4 "Blower_Speed_4" 5 "Blower_Speed_5" 6 "Blower_Speed_6" 7 "Blower_Speed_7" 8 "Min_Blower" 9 "Max_Blower" 10 "Zero_Blower" 11 "NotUsed_2" 12 "NotUsed_3" 13 "NotUsed_4" 14 "NotUsed_5" 15 "NotUsed_6" ;
VAL_ 662 RgstrSetObl_D_Rq 0 "NoChange" 1 "ManualChange" 2 "FeatureManualChange" 3 "FeatureButtonChange" 4 "Open" 5 "Close" 6 "NotUsed_1" 7 "NotUsed_2" ;
VAL_ 662 Third_Rear_Set_Temp 0 "No_Request" 1 "LO" 2 "15_5" 3 "16_0" 4 "16_5" 5 "17_0" 6 "17_5" 7 "18_0" 8 "18_5" 9 "19_0" 10 "19_5" 11 "20_0" 12 "20_5" 13 "21_0" 14 "21_5" 15 "22_0" 16 "22_5" 17 "23_0" 18 "23_5" 19 "24_0" 20 "24_5" 21 "25_0" 22 "25_5" 23 "26_0" 24 "26_5" 25 "27_0" 26 "27_5" 27 "28_0" 28 "28_5" 29 "29_0" 30 "29_5" 31 "HI" ;
VAL_ 662 ScOnb_B_Stat2 0 "Offboarded" 1 "Onboarded" ;
VAL_ 662 RgstrSetIbl_D_Rq 0 "NoChange" 1 "ManualChange" 2 "FeatureManualChange" 3 "FeatureButtonChange" 4 "Open" 5 "Close" 6 "NotUsed_1" 7 "NotUsed_2" ;
VAL_ 662 ActvButtnRight_D_Rq 0 "NonePressed" 1 "OnBodyRHS" 2 "OffBodyRHS" 3 "PresetOneRHS" 4 "PresetTwoRHS" 5 "PresetOneSaveRHS" 6 "PresetTwoSaveRHS" 7 "Cycle_8_RHS" 8 "Cycle_C_RHS" 9 "Cycle_O_RHS" 10 "Cycle_RHS" 11 "Cycle_I_RHS" 12 "NotUsed_1" 13 "NotUsed_2" 14 "NotUsed_3" 15 "NotUsed_4" ;
VAL_ 662 RgstrSetIbr_D_Rq 0 "NoChange" 1 "ManualChange" 2 "FeatureManualChange" 3 "FeatureButtonChange" 4 "Open" 5 "Close" 6 "NotUsed_1" 7 "NotUsed_2" ;
VAL_ 662 RgstrSetObr_D_Rq 0 "NoChange" 1 "ManualChange" 2 "FeatureManualChange" 3 "FeatureButtonChange" 4 "Open" 5 "Close" 6 "NotUsed_1" 7 "NotUsed_2" ;
VAL_ 663 Bpt_Pw_Allw 65534 "NoDataExists" 65535 "Faulty" ;
VAL_ 663 BptMnSoc_L_Actl 8190 "NoDataExists" 8191 "Faulty" ;
VAL_ 663 BptDchrg_T_Rmng 32766 "NoDataExists" 32767 "Faulty" ;
VAL_ 663 Bpt_I_Est 1022 "NoDataExists" 1023 "Faulty" ;
VAL_ 663 BptDchrg_Pw_Dsply 1022 "NoDataExists" 1023 "Faulty" ;
VAL_ 668 SeatFold3lButtn_D_Stat2 0 "Not_Pressed" 1 "Pressed" ;
VAL_ 668 SeatFold3bButtn_D_Stat2 0 "Not_Pressed" 1 "Pressed" ;
VAL_ 668 SeatBckMtnRr_D_Stat 0 "NotMoving" 1 "Opening" 2 "Folding" 3 "NotUsed_1" 4 "NotUsed_2" 5 "NotUsed_3" 6 "NotUsed_4" 7 "NotUsed_5" ;
VAL_ 668 SeatBckMtn3r_D_Stat 0 "NotMoving" 1 "Opening" 2 "Folding" 3 "NotUsed_1" 4 "NotUsed_2" 5 "NotUsed_3" 6 "NotUsed_4" 7 "NotUsed_5" ;
VAL_ 668 SeatBckPosRr_D_Stat 0 "ComfortZone" 1 "FoldZone" 2 "FoldToFlat" 3 "Lifted" 4 "NotUsed_1" 5 "NotUsed_2" 6 "NotUsed_3" 7 "NotUsed_4" 8 "NotUsed_5" 9 "NotUsed_6" 10 "NotUsed_7" 11 "NotUsed_8" 12 "NotUsed_9" 13 "NotUsed_10" 14 "NotUsed_11" 15 "Faulty" ;
VAL_ 668 SeatBckPos3r_D_Stat 0 "ComfortZone" 1 "FoldZone" 2 "FoldToFlat" 3 "Lifted" 4 "NotUsed_1" 5 "NotUsed_2" 6 "NotUsed_3" 7 "NotUsed_4" 8 "NotUsed_5" 9 "NotUsed_6" 10 "NotUsed_7" 11 "NotUsed_8" 12 "NotUsed_9" 13 "NotUsed_10" 14 "NotUsed_11" 15 "Faulty" ;
VAL_ 668 SeatFoldRrButtn_D_Stat2 0 "Not_Pressed" 1 "Pressed" ;
VAL_ 668 SeatFoldRlButtn_D_Stat2 0 "Not_Pressed" 1 "Pressed" ;
VAL_ 668 SeatFoldRbButtn_D_Stat2 0 "Not_Pressed" 1 "Pressed" ;
VAL_ 668 SeatFold3rButtn_D_Stat2 0 "Not_Pressed" 1 "Pressed" ;
VAL_ 668 SeatMtnRrMsgTxt_D_Rq 0 "NoMessage" 1 "Malfunction" 2 "SeatLockReminder" 3 "SecondRowFnInhbtByOccupy" 4 "SecondRowFnInhbtByVehMovin" 5 "NotUsed_1" 6 "NotUsed_2" 7 "NotUsed_3" 8 "NotUsed_4" 9 "NotUsed_5" 10 "NotUsed_6" 11 "NotUsed_7" 12 "NotUsed_8" 13 "NotUsed_9" 14 "NotUsed_10" 15 "NotUsed_11" ;
VAL_ 668 SeatSlidPosR2Psng_B_St 0 "Null" 1 "Stall" ;
VAL_ 668 SeatMovR2Psngr_D_Res 0 "Null" 1 "Success" 2 "Pending" 3 "Rejected" 4 "Interrupted" 5 "Failed" 6 "In_Prog" 7 "Invalid" 8 "NotUsed_1" 9 "NotUsed_2" 10 "NotUsed_3" 11 "NotUsed_4" 12 "NotUsed_5" 13 "NotUsed_6" 14 "NotUsed_7" 15 "Faulty" ;
VAL_ 668 SeatCalfRstR2Psng_B_St 0 "Null" 1 "Stall" ;
VAL_ 668 SeatLmbrHgtR2Psng_B_St 0 "Null" 1 "Stall" ;
VAL_ 668 SeatLmbrExtnR2Psn_B_St 0 "Null" 1 "Stall" ;
VAL_ 668 SeatBckInclR2Psng_B_St 0 "Null" 1 "Stall" ;
VAL_ 668 SeatMovSrvcR2Psn_D_Arb 0 "Null" 1 "Local" 2 "Soa" 3 "NotUsed_1" ;
VAL_ 669 DrHandleOuterRr_D_Stat 0 "None" 1 "Deploy" 2 "Flush" 3 "DeployFault1" 4 "DeployFault2" 5 "FlushFault" 6 "Deploying" 7 "Retracting" ;
VAL_ 669 DrHandleOuterFr_D_Stat 0 "None" 1 "Deploy" 2 "Flush" 3 "DeployFault1" 4 "DeployFault2" 5 "FlushFault" 6 "Deploying" 7 "Retracting" ;
VAL_ 670 DrHandleOuterRl_D_Stat 0 "None" 1 "Deploy" 2 "Flush" 3 "DeployFault1" 4 "DeployFault2" 5 "FlushFault" 6 "Deploying" 7 "Retracting" ;
VAL_ 670 DrHandleOuterFl_D_Stat 0 "None" 1 "Deploy" 2 "Flush" 3 "DeployFault1" 4 "DeployFault2" 5 "FlushFault" 6 "Deploying" 7 "Retracting" ;
VAL_ 672 Coding_BtnID_B 0 "Not_Pressed" 1 "Pressed" ;
VAL_ 672 Coding_BtnID_A 0 "Not_Pressed" 1 "Pressed" ;
VAL_ 672 Coding_BtnID_D 0 "Not_Pressed" 1 "Pressed" ;
VAL_ 672 Coding_BtnID_C 0 "Not_Pressed" 1 "Pressed" ;
VAL_ 672 BCP_Audible_Beep_Rq 0 "Inactive" 1 "Active" ;
VAL_ 673 ICI_Coding_BtnID_B 0 "Inactive" 1 "Active" 2 "ShortEvent" 3 "ShortElapsed" 4 "LongEvent" 5 "Stuck" 15 "Idle" ;
VAL_ 673 ICI_Coding_BtnID_A 0 "Inactive" 1 "Active" 2 "ShortEvent" 3 "ShortElapsed" 4 "LongEvent" 5 "Stuck" 15 "Idle" ;
VAL_ 673 ICI_Coding_BtnID_D 0 "Inactive" 1 "Active" 2 "ShortEvent" 3 "ShortElapsed" 4 "LongEvent" 5 "Stuck" 15 "Idle" ;
VAL_ 673 ICI_Coding_BtnID_C 0 "Inactive" 1 "Active" 2 "ShortEvent" 3 "ShortElapsed" 4 "LongEvent" 5 "Stuck" 15 "Idle" ;
VAL_ 674 RACM_Coding_BtnID_A 0 "Not_Pressed" 1 "Pressed" ;
VAL_ 674 RACM_Coding_BtnID_B 0 "Not_Pressed" 1 "Pressed" ;
VAL_ 674 RACM_Coding_BtnID_C 0 "Not_Pressed" 1 "Pressed" ;
VAL_ 674 RACM_Coding_BtnID_D 0 "Not_Pressed" 1 "Pressed" ;
VAL_ 674 ArmrestStwdRear_B_Stat 0 "No" 1 "Yes" ;
VAL_ 674 RearMnuCtlLck_B_Stat 0 "Unlocked" 1 "Locked" ;
VAL_ 674 RearAudioCtlLck_D_Stat 0 "Null" 1 "Locked" 2 "Unlocked" ;
VAL_ 677 SeatFnChngPsgr2_D_Rq3 0 "Inactive" 1 "NotUsed1" 2 "Increase" 3 "Decrease" 4 "Off" 5 "Low" 6 "High" 7 "Off_2" 8 "Low_2" 9 "Med_2" 10 "High_2" 11 "NotUsed6" 12 "NotUsed7" 13 "NotUsed8" 14 "NotUsed9" 15 "Faulty" ;
VAL_ 677 SeatFnChngDrv2_D_Rq3 0 "Inactive" 1 "NotUsed1" 2 "Increase" 3 "Decrease" 4 "Off" 5 "Low" 6 "High" 7 "Off_2" 8 "Low_2" 9 "Med_2" 10 "High_2" 11 "NotUsed6" 12 "NotUsed7" 13 "NotUsed8" 14 "NotUsed9" 15 "Faulty" ;
VAL_ 677 SeatMasgPsngrRr_D_Rq2 0 "Null" 1 "Pattern1" 2 "Pattern2" 3 "Pattern3" 4 "Pattern4" 5 "Pattern5" 6 "Pattern6" 7 "Pattern7" 8 "Pattern8" 9 "Pattern9" 10 "Pattern10" 11 "NotUsed_6" 12 "NotUsed_7" 13 "NotUsed_8" 14 "NotUsed_9" 15 "NotUsed_10" ;
VAL_ 677 SeatMasgDrvRr_D_Rq2 0 "Null" 1 "Pattern1" 2 "Pattern2" 3 "Pattern3" 4 "Pattern4" 5 "Pattern5" 6 "Pattern6" 7 "Pattern7" 8 "Pattern8" 9 "Pattern9" 10 "Pattern10" 11 "NotUsed_6" 12 "NotUsed_7" 13 "NotUsed_8" 14 "NotUsed_9" 15 "NotUsed_10" ;
VAL_ 677 SeatFnPsgr_D_Rq3 0 "Null" 1 "LowerLumbar" 2 "MiddleLumbar" 3 "UpperLumbar" 4 "LowerBolster" 5 "UpperBolster" 6 "LumbarMassage" 7 "CushionMassage" ;
VAL_ 677 SeatFnDrv_D_Rq3 0 "Null" 1 "LowerLumbar" 2 "MiddleLumbar" 3 "UpperLumbar" 4 "LowerBolster" 5 "UpperBolster" 6 "LumbarMassage" 7 "CushionMassage" ;
VAL_ 677 DgtlShadeAr3Rear_D_Rq 0 "Null" 1 "OnClear" 2 "OffShade" 3 "Auto" 4 "NotUsed_1" 5 "NotUsed_2" 6 "NotUsed_3" 7 "NotUsed_4" ;
VAL_ 677 DgtlShadeAr2Rear_D_Rq 0 "Null" 1 "OnClear" 2 "OffShade" 3 "Auto" 4 "NotUsed_1" 5 "NotUsed_2" 6 "NotUsed_3" 7 "NotUsed_4" ;
VAL_ 677 DgtlShadeAr1Rear_D_Rq 0 "Null" 1 "OnClear" 2 "OffShade" 3 "Auto" 4 "NotUsed_1" 5 "NotUsed_2" 6 "NotUsed_3" 7 "NotUsed_4" ;
VAL_ 677 DgtlShadeAr5Rear_D_Rq 0 "Null" 1 "OnClear" 2 "OffShade" 3 "Auto" 4 "NotUsed_1" 5 "NotUsed_2" 6 "NotUsed_3" 7 "NotUsed_4" ;
VAL_ 677 DgtlShadeAr4Rear_D_Rq 0 "Null" 1 "OnClear" 2 "OffShade" 3 "Auto" 4 "NotUsed_1" 5 "NotUsed_2" 6 "NotUsed_3" 7 "NotUsed_4" ;
VAL_ 677 DgtlShadeMdeRear_D_Rq 0 "Null" 1 "AllOnClear" 2 "AllOffShade" 3 "Pattern" 4 "Auto" 5 "ManualMode" 6 "NotUsed_1" 7 "NotUsed_2" ;
VAL_ 677 DgtlShadeAr6Rear_D_Rq 0 "Null" 1 "OnClear" 2 "OffShade" 3 "Auto" 4 "NotUsed_1" 5 "NotUsed_2" 6 "NotUsed_3" 7 "NotUsed_4" ;
VAL_ 681 Con_DB1Filter1_St 0 "NotEngaged" 1 "SIIndex_1" 65534 "SIIndex_65534" 65535 "All" ;
VAL_ 681 Con_DB1Filter2_St 0 "NotEngaged" 1 "SIIndex_1" 65534 "SIIndex_65534" 65535 "All" ;
VAL_ 681 Con_DB1Filter3_St 0 "NotEngaged" 1 "SIIndex_1" 1022 "SIIndex_1022" 1023 "All" ;
VAL_ 681 Con_DB1FilterConfig_St 0 "Root" 1 "Playlist" 2 "Artist" 3 "Album" 4 "Genre" 5 "Track" 6 "Composer" 7 "Audiobook" 8 "Podcast" 9 "Reserved" 31 "UnknownActive" ;
VAL_ 685 ElVehChrgMde_D_Stat 0 "Null" 1 "NotAvailable" 2 "Available" 3 "NotUsed" ;
VAL_ 685 OnePdlDrvBrk_D_Rq 0 "Inactive" 1 "Active_NoFbrkAllow" 2 "Active_FbrkStopApply" 3 "Active_FbrkStandstillApply" ;
VAL_ 685 ElVehNowMde_D_Stat 0 "Null" 1 "NotAvailable" 2 "Available" 3 "NotUsed" ;
VAL_ 685 ElVehLaterMde_D_Stat 0 "Null" 1 "NotAvailable" 2 "Available" 3 "NotUsed" ;
VAL_ 685 BattTracThrml_D_Stat 0 "ThrmlSysOff" 1 "ClntFlw" 2 "RadClntFlwWoFan" 3 "RadClntFlwFan" 4 "ChlrClntFlw" 5 "MxChlrClntFlw" 6 "ActvHeaterCoreClntFlw" 7 "InActvHeaterCoreClntFlw" 8 "VlvCalib" 9 "AirPurge" 10 "SysFill" 11 "NotUsed_1" 12 "NotUsed_2" 13 "NotUsed_3" 14 "NotUsed_4" 15 "NotUsed_5" ;
VAL_ 720 VRM_BTBatteryLevel_St 0 "Invalid" 1 "Level0" 2 "Level1" 3 "Level2" 4 "Level3" 5 "Level4" 6 "Level5" 7 "NoLinkToBtPhone" 8 "NotSupportedByBtPhone" ;
VAL_ 720 VRM_BTSignalStrength_St 0 "Invalid" 1 "SignalStrength0" 2 "SignalStrength1" 3 "SignalStrength2" 4 "SignalStrength3" 5 "SignalStrength4" 6 "SignalStrength5" 7 "NoLinkToBtPhone" 8 "NotSupportedByBtPhone" ;
VAL_ 720 VRM_BTNetworkStatus_St 0 "Invalid" 1 "NoNetwork" 2 "InNetwork" 3 "Roaming" 4 "NoLinkToBtPhone" 5 "NotSupportedByBtPhone" ;
VAL_ 720 VRM_PhMicrophoneMute_St 0 "Invalid" 1 "MicrophoneIsMuted" 2 "MicrophoneIsUnmuted" 3 "Reserved" ;
VAL_ 720 VRM_VRMMonoOutMode_St 0 "Invalid" 1 "AllocatedVr" 2 "AllocatedBt" 3 "NotAllocated" ;
VAL_ 720 Aioc_ExtSrcOutpMode_St 0 "Invalid" 1 "AllocatedVr" 2 "AllocatedBtPhone" 3 "AllocatedBtNavigation" 4 "AllocatedBtAudio" 5 "AllocatedUSB" 6 "AllocatediPod" 7 "AllocatedAUX3" 8 "NotAllocated" ;
VAL_ 720 VRM_BondRequest_St 0 "Invalid" 1 "BondRequestExist" 2 "NoBondRequestExist" ;
VAL_ 720 VRM_BlutoothStatus_St 0 "Invalid" 1 "On" 2 "Off" ;
VAL_ 720 VRM_SubscribeStatus_St 0 "Invalid" 1 "OnSubscribingInfo" 2 "OffNotSubscribingInfo" ;
VAL_ 720 VRM_BTPhoneSts_St 0 "Invalid" 1 "Idle" 2 "Dialing" 3 "Connected" 4 "CradlephNotReady" 5 "NumUnobtainable" 6 "IncomCall" 7 "NoLinkToBt" 8 "InitBtCon" 9 "PhoneBusy" 10 "PhoneVr" 11 "NotSupported" 12 "BtPhPriv" 13 "ConfCall" 14 "Conference_2ndIncCall" 15 "Conference_OtherCallOnHold" 16 "Connected_Call_on_hold" ;
VAL_ 721 VRM_ComTrafficInfDsp_St 0 "Invalid" 1 "CommandNotIssued" 2 "ShowTrafficInfoOnDisplay" 3 "HideTrafficInfoOnDisplay" ;
VAL_ 721 VRM_ComGuidance_St 0 "Invalid" 1 "CommandNotIssued" 2 "VoiceGuidanceOn" 3 "VoiceGuidanceOff" 4 "CancelGuidance" 5 "RepeatLastVoiceGuidance" ;
VAL_ 721 VRM_ComCallControl_St 0 "Invalid" 1 "CommandNotIssued" 2 "Pickup" 3 "Reject" 4 "EndOngoingCall" ;
VAL_ 721 VRM_ComZoom_St 0 "Invalid" 1 "CommandNotIssued" 2 "Level1" 3 "Level2" 4 "Level3" 5 "Level4" 6 "Level5" 7 "Level6" 8 "Level7" 9 "Level8" 10 "Level9" 11 "Level10" 12 "Level11" 13 "Level12" 14 "Level13" ;
VAL_ 721 VRM_ComDynamicGuidande_St 0 "Invalid" 1 "CommandNotIssued" 2 "On" 3 "Off" ;
VAL_ 721 VRM_ComDisplay_St 0 "Invalid" 1 "CommandNotIssued" 2 "DisplayOn" 3 "DisplayOff" 4 "Day" 5 "Night" 6 "Auto" 7 "Twilight" ;
VAL_ 721 VRM_ComDetour_St 0 "Invalid" 1 "CommandNotIssued" 2 "Detour1" 3 "Detour2" 4 "Detour3" 5 "Detour4" 6 "Detour5" 7 "Detour10" 8 "Detour15" 9 "Detour20" 10 "Detour25" 11 "Detour50" 12 "Detour100" ;
VAL_ 721 VRM_ComSelTrackSource_St 0 "Invalid" 1 "CommandNotIssued" 2 "Cd" 3 "CdChanger" ;
VAL_ 721 VRM_VoiceRecStatus_St 0 "Invalid" 1 "Idle" 2 "Listening" 3 "Reserved" 4 "CommandNotAllowed" ;
VAL_ 721 VRM_ComShowNavInfo_St 0 "Invalid" 1 "CommandNotIssued" 2 "CurrentPos" 3 "Destination" 4 "CompleteRoute" 5 "NorthDirectionToTop" 6 "CarDirectionToTop" 7 "TurnList" ;
VAL_ 721 VRM_ComDestHome_St 0 "Invalid" 1 "CommandNotIssued" 2 "SetDestinationHome" ;
VAL_ 721 VRM_ComTelService_St 0 "Invalid" 1 "CommandNotIssued" 2 "InformationCall" 3 "TelephonyCall" 4 "RedialLastIncoming" ;
VAL_ 721 VRM_ComSelectDisc_St 0 "Invalid" 1 "CommandNotIssued" 2 "Disc1" 3 "Disc2" 4 "Disc3" 5 "Disc4" 6 "Disc5" 7 "Disc6" ;
VAL_ 721 VRM_ComDelWaypoint_St 0 "Invalid" 1 "CommandNotIssued" 2 "DeleteNextWayptDestination" ;
VAL_ 721 VRM_SuggestedRoute_St 0 "Invalid" 1 "CommandNotIssued" 2 "Accept" 3 "Reject" ;
VAL_ 721 VRM_ComBTDTMFTone_St 0 "Invalid" 1 "CommandNotIssued" 2 "Dtmf0" 3 "Dtmf1" 4 "Dtmf2" 5 "Dtmf3" 6 "Dtmf4" 7 "Dtmf5" 8 "Dtmf6" 9 "Dtmf7" 10 "Dtmf8" 11 "Dtmf9" 12 "Dtmfstar" 13 "Dtmfcross" 14 "Dtmfplus" ;
VAL_ 721 VRM_Zoom_Option_St 0 "Invalid" 1 "AbsoluteValue" 2 "InrelativeValue" 3 "OutrelativeValue" ;
VAL_ 721 VRM_DetourUnit_st 0 "Invalid" 1 "Miles" 2 "Kilometer" 3 "Nounitdefined" ;
VAL_ 721 VRM_BTDefaultPhone_St 0 "Invalid" 1 "PhoneIndex1" 2 "PhoneIndex2" 3 "PhoneIndex3" 4 "PhoneIndex4" 5 "PhoneIndex5" 6 "PhoneIndex6" 7 "CradlePhone" 8 "NoPhone" ;
VAL_ 722 VRM_ComShuffleDiscs_St 0 "Invalid" 1 "CommandNotIssued" 2 "On" 3 "Off" ;
VAL_ 722 VRM_ComTape_St 0 "Invalid" 1 "CommandNotIssued" 2 "Play" 3 "Rewind" 4 "Forward" 5 "ChangeSide" 6 "AutosearchForward" 7 "AutosearchBackward" ;
VAL_ 722 VRM_ComPresetCall_St 0 "Invalid" 1 "CommandNotIssued" 2 "Prescall1" 3 "Prescall2" 4 "Prescall3" 5 "Prescall4" 6 "Prescall5" 7 "Prescall6" ;
VAL_ 722 VRM_ComRSEDisplay_St 0 "Invalid" 1 "CommandNotIssued" 2 "On" 3 "Off" ;
VAL_ 722 VRM_NewSMS 0 "Invalid" 1 "NewSmsAvailable" 2 "NoNewSmsAvailable" 3 "UnreadSMSMessagesAvailable" ;
VAL_ 722 VRM_TMCVoice 0 "Invalid" 1 "CommandNotIssued" 2 "On" 3 "Off" ;
VAL_ 722 VRM_ComBand_St 0 "Invalid" 1 "CommandNotIssued" 2 "Fm1" 3 "Fm2" 4 "Fmas" 5 "Am" 6 "Amas" 7 "AutostoreMode" ;
VAL_ 722 VRM_ComAutostore_St 0 "Invalid" 1 "CommandNotIssued" 2 "PerfomAutostore" ;
VAL_ 722 VRM_ComStFreqMode_St 0 "Invalid" 1 "CommandNotIssued" 2 "Fm" 3 "Am" 4 "Reserved" ;
VAL_ 722 VRM_ComCompression_St 0 "Invalid" 1 "CommandNotIssued" 2 "On" 3 "Off" ;
VAL_ 722 VRM_ComShuffleTrack_St 0 "Invalid" 1 "CommandNotIssued" 2 "On" 3 "Off" ;
VAL_ 722 VRM_ComRouteStrategy_St 0 "Invalid" 1 "CommandNotIssued" 2 "Shortesttime" 3 "Shortestdistance" 4 "Majorroadsavoid" 5 "Majorroadsprefer" 6 "TollRoadsaviod" 7 "TollRoadsprefer" 8 "Ferriesavoid" 9 "Ferriesprefer" ;
VAL_ 722 VRM_ComSourceSelect_St 0 "Invalid" 1 "CommandNotIssued" 2 "Radio" 3 "SDCard" 4 "SingleDisc" 5 "MultiDisc" 6 "Con" 7 "BTAudio" ;
VAL_ 722 VRM_ComDolbyNR_St 0 "Invalid" 1 "CommandNotIssued" 2 "On" 3 "Off" ;
VAL_ 725 ACU_CurrentRadioBand_St 0 "Invalid" 1 "Fm1" 2 "Fm2" 3 "FmAst" 4 "Am" 5 "AmAst" 6 "Fm3" ;
VAL_ 725 InfotainmentAudio_St 0 "Null" 1 "NormalOperation" 2 "ErrorState_NoAudio" 3 "NotUsed" ;
VAL_ 725 ACU_AFMode_St 0 "Invalid" 1 "AfOn" 2 "AfOff" 3 "Auto" ;
VAL_ 725 ACU_HardwareError_St 0 "Invalid" 1 "NoError" 2 "EepromReadError" 3 "KeycodeLocked" 4 "KeycodeLockedForever" 5 "CommunicationError" 6 "OverTemperature" 7 "FocusError" ;
VAL_ 725 ACU_RadioError_St 0 "Invalid" 1 "NoError" 2 "PiNotFound" 3 "PtyNotFound" ;
VAL_ 725 ACU_CompLogic_St 0 "Invalid" 1 "Off" 2 "On" ;
SIG_GROUP_ 540 SG_NfcDevcTapMsg_E2E_P01A 1 : NfcDevcTap2_No_Rq NfcDevcTapDur_D_Stat NfcDevcTapMsg_No_Cnt NfcDevcTapMsg_No_Crc NfcDevcTapMsg_UNUSED_6bit_1 NfcDevcTapMsg_UNUSED_8bit_1 NfcDevcTapMsg_UNUSED_8bit_2 NfcDevcTapMsg_UNUSED_8bit_3 NfcDevcTapMsg_UNUSED_8bit_4 NfcDevcTapMsg_UNUSED_8bit_5 NfcDevcTapPrd_B_Stat;
